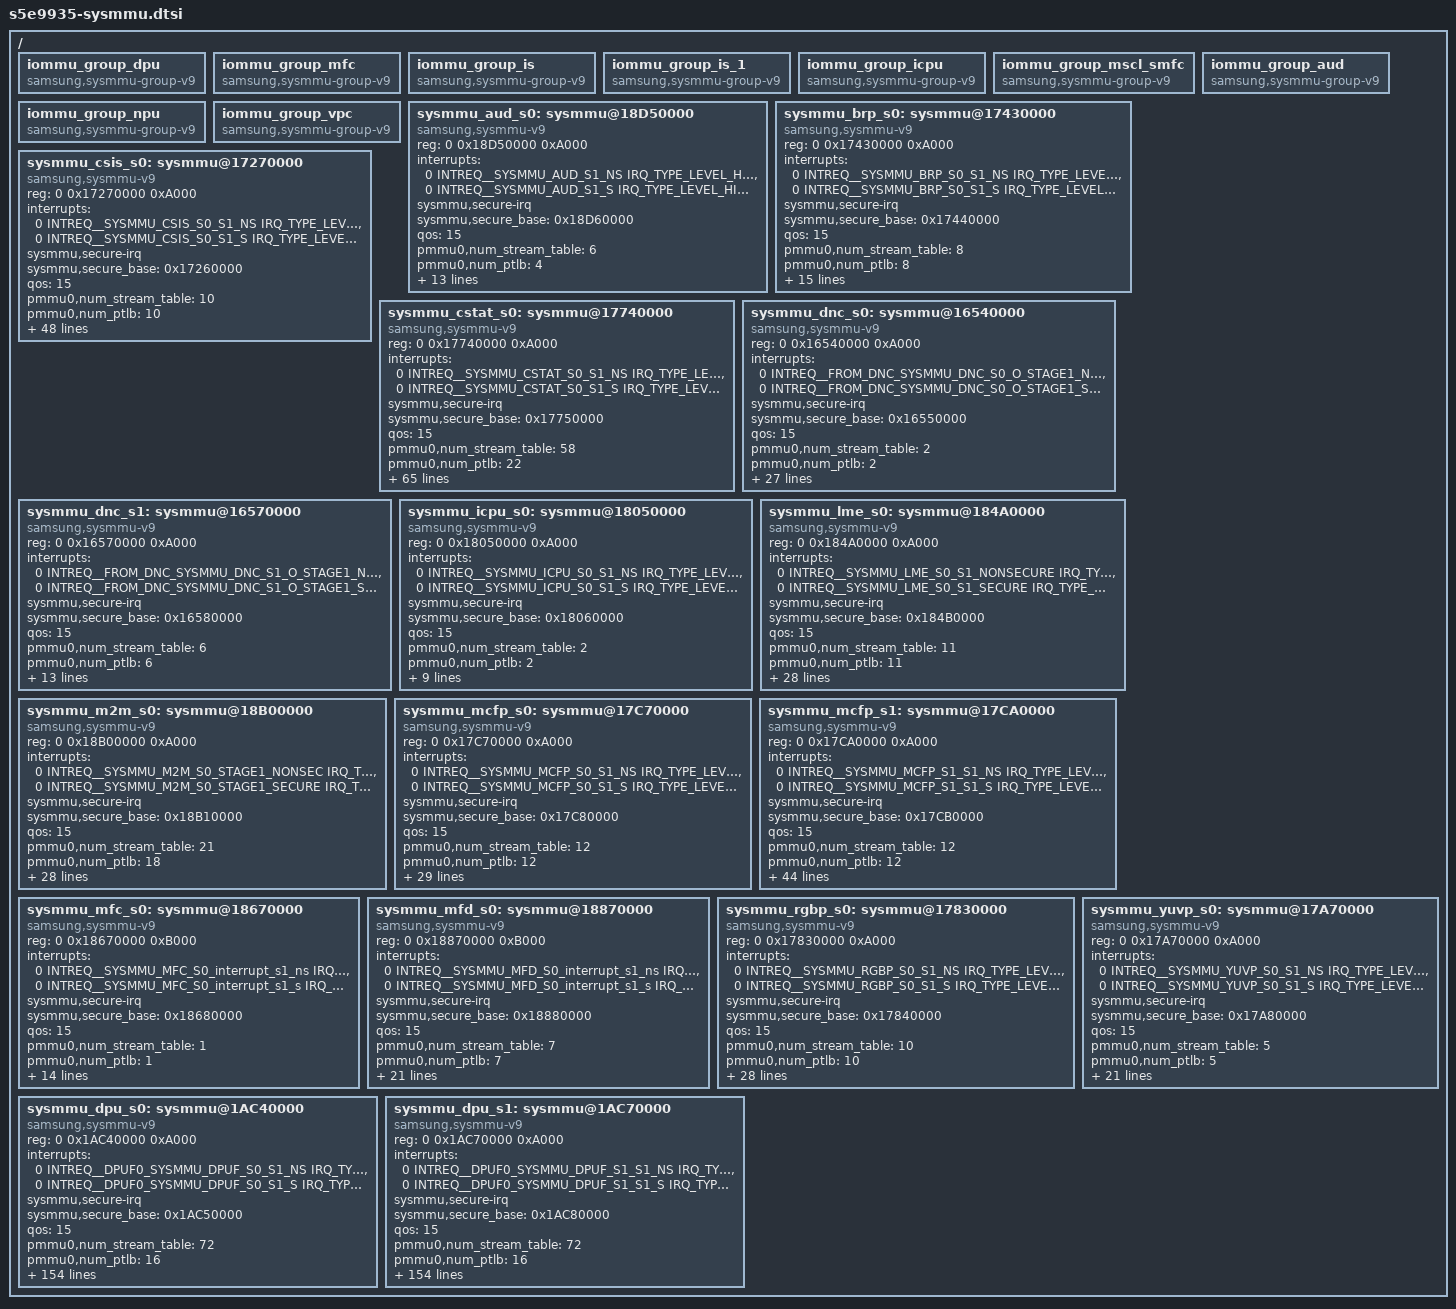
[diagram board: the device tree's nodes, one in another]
// SPDX-License-Identifier: GPL-2.0
/*
 * SAMSUNG S5E9935 SoC device tree source
 *
 * Copyright (c) 2022 Samsung Electronics Co., Ltd.
 *		http://www.samsung.com
 *
 * SAMSUNG S5E9935 SoC device nodes are listed in this file.
 * S5E9935 based board files can include this file and provide
 * values for board specific bindings.
 *
 * This program is free software; you can redistribute it and/or modify
 * it under the terms of the GNU General Public License version 2 as
 * published by the Free Software Foundation.
 */

#include <dt-bindings/interrupt-controller/arm-gic.h>
#include <dt-bindings/soc/samsung,sysmmu-v9.h>

/ {
	iommu_group_dpu: iommu_group_dpu {
		compatible = "samsung,sysmmu-group-v9";
	};

	iommu_group_mfc: iommu_group_mfc {
		compatible = "samsung,sysmmu-group-v9";
	};

	iommu_group_is: iommu_group_is {
		compatible = "samsung,sysmmu-group-v9";
	};

	iommu_group_is_1: iommu_group_is_1 {
		compatible = "samsung,sysmmu-group-v9";
	};

	iommu_group_icpu: iommu_group_icpu {
		compatible = "samsung,sysmmu-group-v9";
	};

	iommu_group_mscl_smfc: iommu_group_mscl_smfc {
		compatible = "samsung,sysmmu-group-v9";
	};

	iommu_group_aud: iommu_group_aud {
		compatible = "samsung,sysmmu-group-v9";
	};

	iommu_group_npu: iommu_group_npu {
		compatible = "samsung,sysmmu-group-v9";
	};

	iommu_group_vpc: iommu_group_vpc {
		compatible = "samsung,sysmmu-group-v9";
	};

	sysmmu_aud_s0: sysmmu@18D50000 {
		compatible = "samsung,sysmmu-v9";
		reg = <0 0x18D50000 0xA000>;
		interrupts = <0 INTREQ__SYSMMU_AUD_S1_NS IRQ_TYPE_LEVEL_HIGH>,
				<0 INTREQ__SYSMMU_AUD_S1_S IRQ_TYPE_LEVEL_HIGH>;
		sysmmu,secure-irq;
		sysmmu,secure_base = <0x18D60000>;
		qos = <15>;
		#iommu-cells = <0>;
		pmmu0,num_stream_table = <6>;
		pmmu0,num_ptlb = <4>;
		pmmu0,default_stream =
			<STREAM_CFG(PTLB_ID(0x0), STLB_ID(0x0), FETCH_SIZE(SIZE1), PTLB_DIS, STLB_DIS)>;
		pmmu0,stream_property =
			<1 STREAM_CFG(PTLB_ID(0x0), STLB_ID(0x0), FETCH_SIZE(SIZE1), PTLB_DIS, STLB_DIS)
			 STREAM_MATCH_CFG(DIR_RW)
			 STREAM_MATCH_SID_VALUE(0x1)
			 STREAM_MATCH_SID_MASK(0xF)>,
			<2 STREAM_CFG(PTLB_ID(0x0), STLB_ID(0x0), FETCH_SIZE(SIZE1), PTLB_DIS, STLB_DIS)
			 STREAM_MATCH_CFG(DIR_RW)
			 STREAM_MATCH_SID_VALUE(0x1)
			 STREAM_MATCH_SID_MASK(0xF)>,
			<3 STREAM_CFG(PTLB_ID(0x1), STLB_ID(0x1), FETCH_SIZE(SIZE1), PTLB_DIS, STLB_DIS)
			 STREAM_MATCH_CFG(DIR_RW)
			 STREAM_MATCH_SID_VALUE(0x3)
			 STREAM_MATCH_SID_MASK(0xF)>,
			<4 STREAM_CFG(PTLB_ID(0x2), STLB_ID(0x2), FETCH_SIZE(SIZE1), PTLB_DIS, STLB_DIS)
			 STREAM_MATCH_CFG(DIR_WRITE)
			 STREAM_MATCH_SID_VALUE(0x5)
			 STREAM_MATCH_SID_MASK(0xF)>,
			<5 STREAM_CFG(PTLB_ID(0x3), STLB_ID(0x3), FETCH_SIZE(SIZE1), PTLB_DIS, STLB_DIS)
			 STREAM_MATCH_CFG(DIR_WRITE)
			 STREAM_MATCH_SID_VALUE(0x6)
			 STREAM_MATCH_SID_MASK(0xF)>;
		num_pmmu = <1>;
		vmid_mask = <0x3>;
		sysmmu,feature-info = <0x0>;
		port-name = "ABOX (CA32_0) ABOX (UDMA) AB...";
		power-domains = <&pd_aud>;
	};

	sysmmu_brp_s0: sysmmu@17430000 {
		compatible = "samsung,sysmmu-v9";
		reg = <0 0x17430000 0xA000>;
		interrupts = <0 INTREQ__SYSMMU_BRP_S0_S1_NS IRQ_TYPE_LEVEL_HIGH>,
				<0 INTREQ__SYSMMU_BRP_S0_S1_S IRQ_TYPE_LEVEL_HIGH>;
		sysmmu,secure-irq;
		sysmmu,secure_base = <0x17440000>;
		qos = <15>;
		#iommu-cells = <0>;
		pmmu0,num_stream_table = <8>;
		pmmu0,num_ptlb = <8>;
		pmmu0,default_stream =
			<STREAM_CFG(PTLB_ID(0x5), STLB_ID(0x5), FETCH_SIZE(SIZE1), PTLB_DIS, STLB_DIS)>;
		pmmu0,stream_property =
			<1 STREAM_CFG(PTLB_ID(0x0), STLB_ID(0x0), FETCH_SIZE(SIZE1), PTLB_DIS, STLB_EN)
			 STREAM_MATCH_CFG(DIR_WRITE)
			 STREAM_MATCH_SID_VALUE(0x0)
			 STREAM_MATCH_SID_MASK(0xF)>,
			<2 STREAM_CFG(PTLB_ID(0x1), STLB_ID(0x1), FETCH_SIZE(SIZE1), PTLB_EN, STLB_EN)
			 STREAM_MATCH_CFG(DIR_READ)
			 STREAM_MATCH_SID_VALUE(0x1)
			 STREAM_MATCH_SID_MASK(0xF)>,
			<3 STREAM_CFG(PTLB_ID(0x2), STLB_ID(0x2), FETCH_SIZE(SIZE1), PTLB_EN, STLB_EN)
			 STREAM_MATCH_CFG(DIR_READ)
			 STREAM_MATCH_SID_VALUE(0x9)
			 STREAM_MATCH_SID_MASK(0xF)>,
			<4 STREAM_CFG(PTLB_ID(0x3), STLB_ID(0x3), FETCH_SIZE(SIZE1), PTLB_DIS, STLB_EN)
			 STREAM_MATCH_CFG(DIR_WRITE)
			 STREAM_MATCH_SID_VALUE(0x1)
			 STREAM_MATCH_SID_MASK(0xF)>,
			<5 STREAM_CFG(PTLB_ID(0x4), STLB_ID(0x4), FETCH_SIZE(SIZE1), PTLB_DIS, STLB_EN)
			 STREAM_MATCH_CFG(DIR_WRITE)
			 STREAM_MATCH_SID_VALUE(0x2)
			 STREAM_MATCH_SID_MASK(0xF)>,
			<6 STREAM_CFG(PTLB_ID(0x6), STLB_ID(0x6), FETCH_SIZE(SIZE1), PTLB_DIS, STLB_DIS)
			 STREAM_MATCH_CFG(DIR_WRITE)
			 STREAM_MATCH_SID_VALUE(0x3)
			 STREAM_MATCH_SID_MASK(0xF)>,
			<7 STREAM_CFG(PTLB_ID(0x7), STLB_ID(0x7), FETCH_SIZE(SIZE1), PTLB_DIS, STLB_DIS)
			 STREAM_MATCH_CFG(DIR_WRITE)
			 STREAM_MATCH_SID_VALUE(0x4)
			 STREAM_MATCH_SID_MASK(0xF)>;
		num_pmmu = <1>;
		vmid_mask = <0x3>;
		sysmmu,feature-info = <0x0>;
		port-name = "BYRP (M0) BYRP (M0) BYRP (M1...";
		power-domains = <&pd_brp>;
	};

	sysmmu_csis_s0: sysmmu@17270000 {
		compatible = "samsung,sysmmu-v9";
		reg = <0 0x17270000 0xA000>;
		interrupts = <0 INTREQ__SYSMMU_CSIS_S0_S1_NS IRQ_TYPE_LEVEL_HIGH>,
				<0 INTREQ__SYSMMU_CSIS_S0_S1_S IRQ_TYPE_LEVEL_HIGH>;
		sysmmu,secure-irq;
		sysmmu,secure_base = <0x17260000>;
		qos = <15>;
		#iommu-cells = <0>;
		pmmu0,num_stream_table = <10>;
		pmmu0,num_ptlb = <10>;
		pmmu0,default_stream =
			<STREAM_CFG(PTLB_ID(0x0), STLB_ID(0x0), FETCH_SIZE(SIZE1), PTLB_DIS, STLB_EN)>;
		pmmu0,stream_property =
			<1 STREAM_CFG(PTLB_ID(0x1), STLB_ID(0x1), FETCH_SIZE(SIZE1), PTLB_DIS, STLB_EN)
			 STREAM_MATCH_CFG(DIR_WRITE)
			 STREAM_MATCH_SID_VALUE(0x2)
			 STREAM_MATCH_SID_MASK(0xF)>,
			<2 STREAM_CFG(PTLB_ID(0x2), STLB_ID(0x2), FETCH_SIZE(SIZE1), PTLB_DIS, STLB_EN)
			 STREAM_MATCH_CFG(DIR_WRITE)
			 STREAM_MATCH_SID_VALUE(0x4)
			 STREAM_MATCH_SID_MASK(0xF)>,
			<3 STREAM_CFG(PTLB_ID(0x3), STLB_ID(0x3), FETCH_SIZE(SIZE1), PTLB_DIS, STLB_EN)
			 STREAM_MATCH_CFG(DIR_WRITE)
			 STREAM_MATCH_SID_VALUE(0x8)
			 STREAM_MATCH_SID_MASK(0xF)>,
			<4 STREAM_CFG(PTLB_ID(0x4), STLB_ID(0x4), FETCH_SIZE(SIZE1), PTLB_DIS, STLB_EN)
			 STREAM_MATCH_CFG(DIR_WRITE)
			 STREAM_MATCH_SID_VALUE(0xC)
			 STREAM_MATCH_SID_MASK(0xF)>,
			<5 STREAM_CFG(PTLB_ID(0x5), STLB_ID(0x5), FETCH_SIZE(SIZE1), PTLB_DIS, STLB_EN)
			 STREAM_MATCH_CFG(DIR_WRITE)
			 STREAM_MATCH_SID_VALUE(0x1)
			 STREAM_MATCH_SID_MASK(0xF)>,
			<6 STREAM_CFG(PTLB_ID(0x6), STLB_ID(0x6), FETCH_SIZE(SIZE1), PTLB_DIS, STLB_EN)
			 STREAM_MATCH_CFG(DIR_WRITE)
			 STREAM_MATCH_SID_VALUE(0x3)
			 STREAM_MATCH_SID_MASK(0xF)>,
			<7 STREAM_CFG(PTLB_ID(0x7), STLB_ID(0x7), FETCH_SIZE(SIZE1), PTLB_DIS, STLB_EN)
			 STREAM_MATCH_CFG(DIR_WRITE)
			 STREAM_MATCH_SID_VALUE(0x5)
			 STREAM_MATCH_SID_MASK(0xF)>,
			<8 STREAM_CFG(PTLB_ID(0x8), STLB_ID(0x8), FETCH_SIZE(SIZE1), PTLB_DIS, STLB_EN)
			 STREAM_MATCH_CFG(DIR_WRITE)
			 STREAM_MATCH_SID_VALUE(0x9)
			 STREAM_MATCH_SID_MASK(0xF)>,
			<9 STREAM_CFG(PTLB_ID(0x9), STLB_ID(0x9), FETCH_SIZE(SIZE1), PTLB_DIS, STLB_EN)
			 STREAM_MATCH_CFG(DIR_WRITE)
			 STREAM_MATCH_SID_VALUE(0xD)
			 STREAM_MATCH_SID_MASK(0xF)>;
		pmmu1,num_stream_table = <15>;
		pmmu1,num_ptlb = <15>;
		pmmu1,default_stream =
			<STREAM_CFG(PTLB_ID(0x0), STLB_ID(0xa), FETCH_SIZE(SIZE1), PTLB_DIS, STLB_EN)>;
		pmmu1,stream_property =
			<1 STREAM_CFG(PTLB_ID(0x1), STLB_ID(0xb), FETCH_SIZE(SIZE1), PTLB_DIS, STLB_EN)
			 STREAM_MATCH_CFG(DIR_WRITE)
			 STREAM_MATCH_SID_VALUE(0x4)
			 STREAM_MATCH_SID_MASK(0x1F)>,
			<2 STREAM_CFG(PTLB_ID(0x2), STLB_ID(0xc), FETCH_SIZE(SIZE1), PTLB_DIS, STLB_EN)
			 STREAM_MATCH_CFG(DIR_WRITE)
			 STREAM_MATCH_SID_VALUE(0x8)
			 STREAM_MATCH_SID_MASK(0x1F)>,
			<3 STREAM_CFG(PTLB_ID(0x3), STLB_ID(0xd), FETCH_SIZE(SIZE1), PTLB_DIS, STLB_EN)
			 STREAM_MATCH_CFG(DIR_WRITE)
			 STREAM_MATCH_SID_VALUE(0x10)
			 STREAM_MATCH_SID_MASK(0x1F)>,
			<4 STREAM_CFG(PTLB_ID(0x4), STLB_ID(0xe), FETCH_SIZE(SIZE1), PTLB_DIS, STLB_EN)
			 STREAM_MATCH_CFG(DIR_WRITE)
			 STREAM_MATCH_SID_VALUE(0x18)
			 STREAM_MATCH_SID_MASK(0x1F)>,
			<5 STREAM_CFG(PTLB_ID(0x5), STLB_ID(0xf), FETCH_SIZE(SIZE1), PTLB_DIS, STLB_EN)
			 STREAM_MATCH_CFG(DIR_WRITE)
			 STREAM_MATCH_SID_VALUE(0x1)
			 STREAM_MATCH_SID_MASK(0x1F)>,
			<6 STREAM_CFG(PTLB_ID(0x6), STLB_ID(0x10), FETCH_SIZE(SIZE1), PTLB_DIS, STLB_EN)
			 STREAM_MATCH_CFG(DIR_WRITE)
			 STREAM_MATCH_SID_VALUE(0x5)
			 STREAM_MATCH_SID_MASK(0x1F)>,
			<7 STREAM_CFG(PTLB_ID(0x7), STLB_ID(0x11), FETCH_SIZE(SIZE1), PTLB_DIS, STLB_EN)
			 STREAM_MATCH_CFG(DIR_WRITE)
			 STREAM_MATCH_SID_VALUE(0x9)
			 STREAM_MATCH_SID_MASK(0x1F)>,
			<8 STREAM_CFG(PTLB_ID(0x8), STLB_ID(0x12), FETCH_SIZE(SIZE1), PTLB_DIS, STLB_EN)
			 STREAM_MATCH_CFG(DIR_WRITE)
			 STREAM_MATCH_SID_VALUE(0x11)
			 STREAM_MATCH_SID_MASK(0x1F)>,
			<9 STREAM_CFG(PTLB_ID(0x9), STLB_ID(0x13), FETCH_SIZE(SIZE1), PTLB_DIS, STLB_EN)
			 STREAM_MATCH_CFG(DIR_WRITE)
			 STREAM_MATCH_SID_VALUE(0x19)
			 STREAM_MATCH_SID_MASK(0x1F)>,
			<10 STREAM_CFG(PTLB_ID(0xa), STLB_ID(0x14), FETCH_SIZE(SIZE1), PTLB_DIS, STLB_EN)
			 STREAM_MATCH_CFG(DIR_WRITE)
			 STREAM_MATCH_SID_VALUE(0x2)
			 STREAM_MATCH_SID_MASK(0x1F)>,
			<11 STREAM_CFG(PTLB_ID(0xb), STLB_ID(0x15), FETCH_SIZE(SIZE1), PTLB_DIS, STLB_EN)
			 STREAM_MATCH_CFG(DIR_WRITE)
			 STREAM_MATCH_SID_VALUE(0x6)
			 STREAM_MATCH_SID_MASK(0x1F)>,
			<12 STREAM_CFG(PTLB_ID(0xc), STLB_ID(0x16), FETCH_SIZE(SIZE1), PTLB_DIS, STLB_EN)
			 STREAM_MATCH_CFG(DIR_WRITE)
			 STREAM_MATCH_SID_VALUE(0xA)
			 STREAM_MATCH_SID_MASK(0x1F)>,
			<13 STREAM_CFG(PTLB_ID(0xd), STLB_ID(0x17), FETCH_SIZE(SIZE1), PTLB_DIS, STLB_EN)
			 STREAM_MATCH_CFG(DIR_WRITE)
			 STREAM_MATCH_SID_VALUE(0x12)
			 STREAM_MATCH_SID_MASK(0x1F)>,
			<14 STREAM_CFG(PTLB_ID(0xe), STLB_ID(0x18), FETCH_SIZE(SIZE1), PTLB_DIS, STLB_EN)
			 STREAM_MATCH_CFG(DIR_WRITE)
			 STREAM_MATCH_SID_VALUE(0x1A)
			 STREAM_MATCH_SID_MASK(0x1F)>;
		pmmu2,num_stream_table = <8>;
		pmmu2,num_ptlb = <8>;
		pmmu2,default_stream =
			<STREAM_CFG(PTLB_ID(0x5), STLB_ID(0x1e), FETCH_SIZE(SIZE1), PTLB_DIS, STLB_DIS)>;
		pmmu2,stream_property =
			<1 STREAM_CFG(PTLB_ID(0x6), STLB_ID(0x1f), FETCH_SIZE(SIZE1), PTLB_DIS, STLB_DIS)
			 STREAM_MATCH_CFG(DIR_WRITE)
			 STREAM_MATCH_SID_VALUE(0x2)
			 STREAM_MATCH_SID_MASK(0x7)>,
			<2 STREAM_CFG(PTLB_ID(0x0), STLB_ID(0x19), FETCH_SIZE(SIZE1), PTLB_DIS, STLB_EN)
			 STREAM_MATCH_CFG(DIR_WRITE)
			 STREAM_MATCH_SID_VALUE(0x0)
			 STREAM_MATCH_SID_MASK(0x7F)>,
			<3 STREAM_CFG(PTLB_ID(0x1), STLB_ID(0x1a), FETCH_SIZE(SIZE1), PTLB_DIS, STLB_EN)
			 STREAM_MATCH_CFG(DIR_READ)
			 STREAM_MATCH_SID_VALUE(0x0)
			 STREAM_MATCH_SID_MASK(0x7F)>,
			<4 STREAM_CFG(PTLB_ID(0x2), STLB_ID(0x1b), FETCH_SIZE(SIZE1), PTLB_DIS, STLB_EN)
			 STREAM_MATCH_CFG(DIR_WRITE)
			 STREAM_MATCH_SID_VALUE(0x20)
			 STREAM_MATCH_SID_MASK(0x7F)>,
			<5 STREAM_CFG(PTLB_ID(0x3), STLB_ID(0x1c), FETCH_SIZE(SIZE1), PTLB_DIS, STLB_EN)
			 STREAM_MATCH_CFG(DIR_WRITE)
			 STREAM_MATCH_SID_VALUE(0x40)
			 STREAM_MATCH_SID_MASK(0x7F)>,
			<6 STREAM_CFG(PTLB_ID(0x4), STLB_ID(0x1d), FETCH_SIZE(SIZE1), PTLB_DIS, STLB_EN)
			 STREAM_MATCH_CFG(DIR_WRITE)
			 STREAM_MATCH_SID_VALUE(0x60)
			 STREAM_MATCH_SID_MASK(0x7F)>,
			<7 STREAM_CFG(PTLB_ID(0x7), STLB_ID(0x20), FETCH_SIZE(SIZE1), PTLB_DIS, STLB_DIS)
			 STREAM_MATCH_CFG(DIR_WRITE)
			 STREAM_MATCH_SID_VALUE(0x3)
			 STREAM_MATCH_SID_MASK(0x7)>;
		num_pmmu = <3>;
		vmid_mask = <0x3>;
		sysmmu,feature-info = <0x0>;
		port-name = "CSISX7_V1.0 (CSIS DMA0) CSIS...";
		power-domains = <&pd_csis>;
	};

	sysmmu_cstat_s0: sysmmu@17740000 {
		compatible = "samsung,sysmmu-v9";
		reg = <0 0x17740000 0xA000>;
		interrupts = <0 INTREQ__SYSMMU_CSTAT_S0_S1_NS IRQ_TYPE_LEVEL_HIGH>,
				<0 INTREQ__SYSMMU_CSTAT_S0_S1_S IRQ_TYPE_LEVEL_HIGH>;
		sysmmu,secure-irq;
		sysmmu,secure_base = <0x17750000>;
		qos = <15>;
		#iommu-cells = <0>;
		pmmu0,num_stream_table = <58>;
		pmmu0,num_ptlb = <22>;
		pmmu0,default_stream =
			<STREAM_CFG(PTLB_ID(0x0), STLB_ID(0x0), FETCH_SIZE(SIZE1), PTLB_DIS, STLB_EN)>;
		pmmu0,stream_property =
			<1 STREAM_CFG(PTLB_ID(0x0), STLB_ID(0x1), FETCH_SIZE(SIZE1), PTLB_DIS, STLB_EN)
			 STREAM_MATCH_CFG(DIR_WRITE)
			 STREAM_MATCH_SID_VALUE(0x80)
			 STREAM_MATCH_SID_MASK(0x1FF)>,
			<2 STREAM_CFG(PTLB_ID(0x0), STLB_ID(0x2), FETCH_SIZE(SIZE1), PTLB_DIS, STLB_EN)
			 STREAM_MATCH_CFG(DIR_WRITE)
			 STREAM_MATCH_SID_VALUE(0x100)
			 STREAM_MATCH_SID_MASK(0x1FF)>,
			<3 STREAM_CFG(PTLB_ID(0x0), STLB_ID(0x3), FETCH_SIZE(SIZE1), PTLB_DIS, STLB_EN)
			 STREAM_MATCH_CFG(DIR_WRITE)
			 STREAM_MATCH_SID_VALUE(0x180)
			 STREAM_MATCH_SID_MASK(0x1FF)>,
			<4 STREAM_CFG(PTLB_ID(0x1), STLB_ID(0x4), FETCH_SIZE(SIZE1), PTLB_EN, STLB_EN)
			 STREAM_MATCH_CFG(DIR_READ)
			 STREAM_MATCH_SID_VALUE(0x0)
			 STREAM_MATCH_SID_MASK(0x1FF)>,
			<5 STREAM_CFG(PTLB_ID(0x2), STLB_ID(0x5), FETCH_SIZE(SIZE1), PTLB_DIS, STLB_EN)
			 STREAM_MATCH_CFG(DIR_WRITE)
			 STREAM_MATCH_SID_VALUE(0x1)
			 STREAM_MATCH_SID_MASK(0x1FF)>,
			<6 STREAM_CFG(PTLB_ID(0x0), STLB_ID(0x6), FETCH_SIZE(SIZE1), PTLB_DIS, STLB_EN)
			 STREAM_MATCH_CFG(DIR_WRITE)
			 STREAM_MATCH_SID_VALUE(0x21)
			 STREAM_MATCH_SID_MASK(0x1FF)>,
			<7 STREAM_CFG(PTLB_ID(0x0), STLB_ID(0x7), FETCH_SIZE(SIZE1), PTLB_DIS, STLB_EN)
			 STREAM_MATCH_CFG(DIR_WRITE)
			 STREAM_MATCH_SID_VALUE(0x41)
			 STREAM_MATCH_SID_MASK(0x1FF)>,
			<8 STREAM_CFG(PTLB_ID(0x0), STLB_ID(0x8), FETCH_SIZE(SIZE1), PTLB_DIS, STLB_EN)
			 STREAM_MATCH_CFG(DIR_WRITE)
			 STREAM_MATCH_SID_VALUE(0x81)
			 STREAM_MATCH_SID_MASK(0x1FF)>,
			<9 STREAM_CFG(PTLB_ID(0x3), STLB_ID(0x9), FETCH_SIZE(SIZE1), PTLB_EN, STLB_EN)
			 STREAM_MATCH_CFG(DIR_READ)
			 STREAM_MATCH_SID_VALUE(0x1)
			 STREAM_MATCH_SID_MASK(0x1FF)>,
			<10 STREAM_CFG(PTLB_ID(0x4), STLB_ID(0xa), FETCH_SIZE(SIZE1), PTLB_DIS, STLB_EN)
			 STREAM_MATCH_CFG(DIR_WRITE)
			 STREAM_MATCH_SID_VALUE(0x2)
			 STREAM_MATCH_SID_MASK(0x1FF)>,
			<11 STREAM_CFG(PTLB_ID(0x0), STLB_ID(0xb), FETCH_SIZE(SIZE1), PTLB_DIS, STLB_EN)
			 STREAM_MATCH_CFG(DIR_WRITE)
			 STREAM_MATCH_SID_VALUE(0x82)
			 STREAM_MATCH_SID_MASK(0x1FF)>,
			<12 STREAM_CFG(PTLB_ID(0x0), STLB_ID(0xc), FETCH_SIZE(SIZE1), PTLB_DIS, STLB_EN)
			 STREAM_MATCH_CFG(DIR_WRITE)
			 STREAM_MATCH_SID_VALUE(0x102)
			 STREAM_MATCH_SID_MASK(0x1FF)>,
			<13 STREAM_CFG(PTLB_ID(0x0), STLB_ID(0xd), FETCH_SIZE(SIZE1), PTLB_DIS, STLB_EN)
			 STREAM_MATCH_CFG(DIR_WRITE)
			 STREAM_MATCH_SID_VALUE(0x182)
			 STREAM_MATCH_SID_MASK(0x1FF)>,
			<14 STREAM_CFG(PTLB_ID(0x5), STLB_ID(0xe), FETCH_SIZE(SIZE1), PTLB_EN, STLB_EN)
			 STREAM_MATCH_CFG(DIR_READ)
			 STREAM_MATCH_SID_VALUE(0x2)
			 STREAM_MATCH_SID_MASK(0x1FF)>,
			<15 STREAM_CFG(PTLB_ID(0x6), STLB_ID(0xf), FETCH_SIZE(SIZE1), PTLB_DIS, STLB_EN)
			 STREAM_MATCH_CFG(DIR_WRITE)
			 STREAM_MATCH_SID_VALUE(0x3)
			 STREAM_MATCH_SID_MASK(0x1FF)>,
			<16 STREAM_CFG(PTLB_ID(0x0), STLB_ID(0x10), FETCH_SIZE(SIZE1), PTLB_DIS, STLB_EN)
			 STREAM_MATCH_CFG(DIR_WRITE)
			 STREAM_MATCH_SID_VALUE(0x83)
			 STREAM_MATCH_SID_MASK(0x1FF)>,
			<17 STREAM_CFG(PTLB_ID(0x0), STLB_ID(0x11), FETCH_SIZE(SIZE1), PTLB_DIS, STLB_EN)
			 STREAM_MATCH_CFG(DIR_WRITE)
			 STREAM_MATCH_SID_VALUE(0x103)
			 STREAM_MATCH_SID_MASK(0x1FF)>,
			<18 STREAM_CFG(PTLB_ID(0x0), STLB_ID(0x12), FETCH_SIZE(SIZE1), PTLB_DIS, STLB_EN)
			 STREAM_MATCH_CFG(DIR_WRITE)
			 STREAM_MATCH_SID_VALUE(0x183)
			 STREAM_MATCH_SID_MASK(0x1FF)>,
			<19 STREAM_CFG(PTLB_ID(0x7), STLB_ID(0x13), FETCH_SIZE(SIZE1), PTLB_EN, STLB_EN)
			 STREAM_MATCH_CFG(DIR_READ)
			 STREAM_MATCH_SID_VALUE(0x3)
			 STREAM_MATCH_SID_MASK(0x1FF)>,
			<20 STREAM_CFG(PTLB_ID(0x8), STLB_ID(0x14), FETCH_SIZE(SIZE1), PTLB_DIS, STLB_EN)
			 STREAM_MATCH_CFG(DIR_WRITE)
			 STREAM_MATCH_SID_VALUE(0x4)
			 STREAM_MATCH_SID_MASK(0x1FF)>,
			<21 STREAM_CFG(PTLB_ID(0x0), STLB_ID(0x15), FETCH_SIZE(SIZE1), PTLB_DIS, STLB_EN)
			 STREAM_MATCH_CFG(DIR_WRITE)
			 STREAM_MATCH_SID_VALUE(0x84)
			 STREAM_MATCH_SID_MASK(0x1FF)>,
			<22 STREAM_CFG(PTLB_ID(0x0), STLB_ID(0x16), FETCH_SIZE(SIZE1), PTLB_DIS, STLB_EN)
			 STREAM_MATCH_CFG(DIR_WRITE)
			 STREAM_MATCH_SID_VALUE(0x104)
			 STREAM_MATCH_SID_MASK(0x1FF)>,
			<23 STREAM_CFG(PTLB_ID(0x0), STLB_ID(0x17), FETCH_SIZE(SIZE1), PTLB_DIS, STLB_EN)
			 STREAM_MATCH_CFG(DIR_WRITE)
			 STREAM_MATCH_SID_VALUE(0x184)
			 STREAM_MATCH_SID_MASK(0x1FF)>,
			<24 STREAM_CFG(PTLB_ID(0x10), STLB_ID(0x34), FETCH_SIZE(SIZE1), PTLB_DIS, STLB_DIS)
			 STREAM_MATCH_CFG(DIR_READ)
			 STREAM_MATCH_SID_VALUE(0x4)
			 STREAM_MATCH_SID_MASK(0x1FF)>,
			<25 STREAM_CFG(PTLB_ID(0x9), STLB_ID(0x18), FETCH_SIZE(SIZE1), PTLB_DIS, STLB_EN)
			 STREAM_MATCH_CFG(DIR_WRITE)
			 STREAM_MATCH_SID_VALUE(0x5)
			 STREAM_MATCH_SID_MASK(0x1FF)>,
			<26 STREAM_CFG(PTLB_ID(0x0), STLB_ID(0x19), FETCH_SIZE(SIZE1), PTLB_DIS, STLB_EN)
			 STREAM_MATCH_CFG(DIR_WRITE)
			 STREAM_MATCH_SID_VALUE(0x85)
			 STREAM_MATCH_SID_MASK(0x1FF)>,
			<27 STREAM_CFG(PTLB_ID(0x0), STLB_ID(0x1a), FETCH_SIZE(SIZE1), PTLB_DIS, STLB_EN)
			 STREAM_MATCH_CFG(DIR_WRITE)
			 STREAM_MATCH_SID_VALUE(0x105)
			 STREAM_MATCH_SID_MASK(0x1FF)>,
			<28 STREAM_CFG(PTLB_ID(0x0), STLB_ID(0x1b), FETCH_SIZE(SIZE1), PTLB_DIS, STLB_EN)
			 STREAM_MATCH_CFG(DIR_WRITE)
			 STREAM_MATCH_SID_VALUE(0x185)
			 STREAM_MATCH_SID_MASK(0x1FF)>,
			<29 STREAM_CFG(PTLB_ID(0x11), STLB_ID(0x35), FETCH_SIZE(SIZE1), PTLB_DIS, STLB_DIS)
			 STREAM_MATCH_CFG(DIR_READ)
			 STREAM_MATCH_SID_VALUE(0x5)
			 STREAM_MATCH_SID_MASK(0x1FF)>,
			<30 STREAM_CFG(PTLB_ID(0xa), STLB_ID(0x1c), FETCH_SIZE(SIZE1), PTLB_DIS, STLB_EN)
			 STREAM_MATCH_CFG(DIR_WRITE)
			 STREAM_MATCH_SID_VALUE(0x6)
			 STREAM_MATCH_SID_MASK(0x1FF)>,
			<31 STREAM_CFG(PTLB_ID(0x0), STLB_ID(0x1d), FETCH_SIZE(SIZE1), PTLB_DIS, STLB_EN)
			 STREAM_MATCH_CFG(DIR_WRITE)
			 STREAM_MATCH_SID_VALUE(0x86)
			 STREAM_MATCH_SID_MASK(0x1FF)>,
			<32 STREAM_CFG(PTLB_ID(0x0), STLB_ID(0x1e), FETCH_SIZE(SIZE1), PTLB_DIS, STLB_EN)
			 STREAM_MATCH_CFG(DIR_WRITE)
			 STREAM_MATCH_SID_VALUE(0x106)
			 STREAM_MATCH_SID_MASK(0x1FF)>,
			<33 STREAM_CFG(PTLB_ID(0x0), STLB_ID(0x1f), FETCH_SIZE(SIZE1), PTLB_DIS, STLB_EN)
			 STREAM_MATCH_CFG(DIR_WRITE)
			 STREAM_MATCH_SID_VALUE(0x186)
			 STREAM_MATCH_SID_MASK(0x1FF)>,
			<34 STREAM_CFG(PTLB_ID(0x12), STLB_ID(0x36), FETCH_SIZE(SIZE1), PTLB_DIS, STLB_DIS)
			 STREAM_MATCH_CFG(DIR_READ)
			 STREAM_MATCH_SID_VALUE(0x6)
			 STREAM_MATCH_SID_MASK(0x1FF)>,
			<35 STREAM_CFG(PTLB_ID(0xb), STLB_ID(0x20), FETCH_SIZE(SIZE1), PTLB_DIS, STLB_EN)
			 STREAM_MATCH_CFG(DIR_WRITE)
			 STREAM_MATCH_SID_VALUE(0x7)
			 STREAM_MATCH_SID_MASK(0x1FF)>,
			<36 STREAM_CFG(PTLB_ID(0x0), STLB_ID(0x21), FETCH_SIZE(SIZE1), PTLB_DIS, STLB_EN)
			 STREAM_MATCH_CFG(DIR_WRITE)
			 STREAM_MATCH_SID_VALUE(0x87)
			 STREAM_MATCH_SID_MASK(0x1FF)>,
			<37 STREAM_CFG(PTLB_ID(0x0), STLB_ID(0x22), FETCH_SIZE(SIZE1), PTLB_DIS, STLB_EN)
			 STREAM_MATCH_CFG(DIR_WRITE)
			 STREAM_MATCH_SID_VALUE(0x107)
			 STREAM_MATCH_SID_MASK(0x1FF)>,
			<38 STREAM_CFG(PTLB_ID(0x0), STLB_ID(0x23), FETCH_SIZE(SIZE1), PTLB_DIS, STLB_EN)
			 STREAM_MATCH_CFG(DIR_WRITE)
			 STREAM_MATCH_SID_VALUE(0x187)
			 STREAM_MATCH_SID_MASK(0x1FF)>,
			<39 STREAM_CFG(PTLB_ID(0x13), STLB_ID(0x37), FETCH_SIZE(SIZE1), PTLB_DIS, STLB_DIS)
			 STREAM_MATCH_CFG(DIR_READ)
			 STREAM_MATCH_SID_VALUE(0x7)
			 STREAM_MATCH_SID_MASK(0x1FF)>,
			<40 STREAM_CFG(PTLB_ID(0xc), STLB_ID(0x24), FETCH_SIZE(SIZE1), PTLB_DIS, STLB_EN)
			 STREAM_MATCH_CFG(DIR_WRITE)
			 STREAM_MATCH_SID_VALUE(0x8)
			 STREAM_MATCH_SID_MASK(0x1FF)>,
			<41 STREAM_CFG(PTLB_ID(0x0), STLB_ID(0x25), FETCH_SIZE(SIZE1), PTLB_DIS, STLB_EN)
			 STREAM_MATCH_CFG(DIR_WRITE)
			 STREAM_MATCH_SID_VALUE(0x28)
			 STREAM_MATCH_SID_MASK(0x1FF)>,
			<42 STREAM_CFG(PTLB_ID(0x0), STLB_ID(0x26), FETCH_SIZE(SIZE1), PTLB_DIS, STLB_EN)
			 STREAM_MATCH_CFG(DIR_WRITE)
			 STREAM_MATCH_SID_VALUE(0x48)
			 STREAM_MATCH_SID_MASK(0x1FF)>,
			<43 STREAM_CFG(PTLB_ID(0x0), STLB_ID(0x27), FETCH_SIZE(SIZE1), PTLB_DIS, STLB_EN)
			 STREAM_MATCH_CFG(DIR_WRITE)
			 STREAM_MATCH_SID_VALUE(0x88)
			 STREAM_MATCH_SID_MASK(0x1FF)>,
			<44 STREAM_CFG(PTLB_ID(0xd), STLB_ID(0x28), FETCH_SIZE(SIZE1), PTLB_DIS, STLB_EN)
			 STREAM_MATCH_CFG(DIR_WRITE)
			 STREAM_MATCH_SID_VALUE(0x9)
			 STREAM_MATCH_SID_MASK(0x1FF)>,
			<45 STREAM_CFG(PTLB_ID(0x0), STLB_ID(0x29), FETCH_SIZE(SIZE1), PTLB_DIS, STLB_EN)
			 STREAM_MATCH_CFG(DIR_WRITE)
			 STREAM_MATCH_SID_VALUE(0x89)
			 STREAM_MATCH_SID_MASK(0x1FF)>,
			<46 STREAM_CFG(PTLB_ID(0x0), STLB_ID(0x2a), FETCH_SIZE(SIZE1), PTLB_DIS, STLB_EN)
			 STREAM_MATCH_CFG(DIR_WRITE)
			 STREAM_MATCH_SID_VALUE(0x109)
			 STREAM_MATCH_SID_MASK(0x1FF)>,
			<47 STREAM_CFG(PTLB_ID(0x0), STLB_ID(0x2b), FETCH_SIZE(SIZE1), PTLB_DIS, STLB_EN)
			 STREAM_MATCH_CFG(DIR_WRITE)
			 STREAM_MATCH_SID_VALUE(0x189)
			 STREAM_MATCH_SID_MASK(0x1FF)>,
			<48 STREAM_CFG(PTLB_ID(0xe), STLB_ID(0x2c), FETCH_SIZE(SIZE1), PTLB_DIS, STLB_EN)
			 STREAM_MATCH_CFG(DIR_WRITE)
			 STREAM_MATCH_SID_VALUE(0x29)
			 STREAM_MATCH_SID_MASK(0x1FF)>,
			<49 STREAM_CFG(PTLB_ID(0x0), STLB_ID(0x2d), FETCH_SIZE(SIZE1), PTLB_DIS, STLB_EN)
			 STREAM_MATCH_CFG(DIR_WRITE)
			 STREAM_MATCH_SID_VALUE(0xA9)
			 STREAM_MATCH_SID_MASK(0x1FF)>,
			<50 STREAM_CFG(PTLB_ID(0x0), STLB_ID(0x2e), FETCH_SIZE(SIZE1), PTLB_DIS, STLB_EN)
			 STREAM_MATCH_CFG(DIR_WRITE)
			 STREAM_MATCH_SID_VALUE(0x129)
			 STREAM_MATCH_SID_MASK(0x1FF)>,
			<51 STREAM_CFG(PTLB_ID(0x0), STLB_ID(0x2f), FETCH_SIZE(SIZE1), PTLB_DIS, STLB_EN)
			 STREAM_MATCH_CFG(DIR_WRITE)
			 STREAM_MATCH_SID_VALUE(0x1A9)
			 STREAM_MATCH_SID_MASK(0x1FF)>,
			<52 STREAM_CFG(PTLB_ID(0xf), STLB_ID(0x30), FETCH_SIZE(SIZE1), PTLB_DIS, STLB_EN)
			 STREAM_MATCH_CFG(DIR_WRITE)
			 STREAM_MATCH_SID_VALUE(0x49)
			 STREAM_MATCH_SID_MASK(0x1FF)>,
			<53 STREAM_CFG(PTLB_ID(0x0), STLB_ID(0x31), FETCH_SIZE(SIZE1), PTLB_DIS, STLB_EN)
			 STREAM_MATCH_CFG(DIR_WRITE)
			 STREAM_MATCH_SID_VALUE(0xC9)
			 STREAM_MATCH_SID_MASK(0x1FF)>,
			<54 STREAM_CFG(PTLB_ID(0x0), STLB_ID(0x32), FETCH_SIZE(SIZE1), PTLB_DIS, STLB_EN)
			 STREAM_MATCH_CFG(DIR_WRITE)
			 STREAM_MATCH_SID_VALUE(0x149)
			 STREAM_MATCH_SID_MASK(0x1FF)>,
			<55 STREAM_CFG(PTLB_ID(0x0), STLB_ID(0x33), FETCH_SIZE(SIZE1), PTLB_DIS, STLB_EN)
			 STREAM_MATCH_CFG(DIR_WRITE)
			 STREAM_MATCH_SID_VALUE(0x1C9)
			 STREAM_MATCH_SID_MASK(0x1FF)>,
			<56 STREAM_CFG(PTLB_ID(0x14), STLB_ID(0x38), FETCH_SIZE(SIZE1), PTLB_DIS, STLB_DIS)
			 STREAM_MATCH_CFG(DIR_WRITE)
			 STREAM_MATCH_SID_VALUE(0xA)
			 STREAM_MATCH_SID_MASK(0x1FF)>,
			<57 STREAM_CFG(PTLB_ID(0x15), STLB_ID(0x39), FETCH_SIZE(SIZE1), PTLB_DIS, STLB_DIS)
			 STREAM_MATCH_CFG(DIR_WRITE)
			 STREAM_MATCH_SID_VALUE(0xB)
			 STREAM_MATCH_SID_MASK(0x1FF)>;
		num_pmmu = <1>;
		vmid_mask = <0x3>;
		sysmmu,feature-info = <0x0>;
		port-name = "CSTAT_RD0_RGBYHIST CSTAT_RD1...";
		power-domains = <&pd_cstat>;
	};

	sysmmu_dnc_s0: sysmmu@16540000 {
		compatible = "samsung,sysmmu-v9";
		reg = <0 0x16540000 0xA000>;
		interrupts = <0 INTREQ__FROM_DNC_SYSMMU_DNC_S0_O_STAGE1_NONSEC IRQ_TYPE_LEVEL_HIGH>,
				<0 INTREQ__FROM_DNC_SYSMMU_DNC_S0_O_STAGE1_SECURE IRQ_TYPE_LEVEL_HIGH>;
		sysmmu,secure-irq;
		sysmmu,secure_base = <0x16550000>;
		qos = <15>;
		#iommu-cells = <0>;
		pmmu0,num_stream_table = <2>;
		pmmu0,num_ptlb = <2>;
		pmmu0,default_stream =
			<STREAM_CFG(PTLB_ID(0x0), STLB_ID(0x0), FETCH_SIZE(SIZE8), PTLB_EN, STLB_EN)>;
		pmmu0,stream_property =
			<1 STREAM_CFG(PTLB_ID(0x1), STLB_ID(0x1), FETCH_SIZE(SIZE1), PTLB_DIS, STLB_DIS)
			 STREAM_MATCH_CFG(DIR_RW)
			 STREAM_MATCH_SID_VALUE(0x40)
			 STREAM_MATCH_SID_MASK(0x40)>;
		pmmu1,num_stream_table = <2>;
		pmmu1,num_ptlb = <2>;
		pmmu1,default_stream =
			<STREAM_CFG(PTLB_ID(0x0), STLB_ID(0x0), FETCH_SIZE(SIZE8), PTLB_EN, STLB_EN)>;
		pmmu1,stream_property =
			<1 STREAM_CFG(PTLB_ID(0x1), STLB_ID(0x1), FETCH_SIZE(SIZE1), PTLB_DIS, STLB_DIS)
			 STREAM_MATCH_CFG(DIR_RW)
			 STREAM_MATCH_SID_VALUE(0x40)
			 STREAM_MATCH_SID_MASK(0x40)>;
		pmmu2,num_stream_table = <2>;
		pmmu2,num_ptlb = <2>;
		pmmu2,default_stream =
			<STREAM_CFG(PTLB_ID(0x0), STLB_ID(0x0), FETCH_SIZE(SIZE8), PTLB_EN, STLB_EN)>;
		pmmu2,stream_property =
			<1 STREAM_CFG(PTLB_ID(0x1), STLB_ID(0x1), FETCH_SIZE(SIZE1), PTLB_DIS, STLB_DIS)
			 STREAM_MATCH_CFG(DIR_RW)
			 STREAM_MATCH_SID_VALUE(0x40)
			 STREAM_MATCH_SID_MASK(0x40)>;
		pmmu3,num_stream_table = <2>;
		pmmu3,num_ptlb = <2>;
		pmmu3,default_stream =
			<STREAM_CFG(PTLB_ID(0x0), STLB_ID(0x0), FETCH_SIZE(SIZE8), PTLB_EN, STLB_EN)>;
		pmmu3,stream_property =
			<1 STREAM_CFG(PTLB_ID(0x1), STLB_ID(0x1), FETCH_SIZE(SIZE1), PTLB_DIS, STLB_DIS)
			 STREAM_MATCH_CFG(DIR_RW)
			 STREAM_MATCH_SID_VALUE(0x40)
			 STREAM_MATCH_SID_MASK(0x40)>;
		num_pmmu = <4>;
		vmid_mask = <0x3>;
		sysmmu,feature-info = <0x0>;
		port-name = "IP_SDMA (BUSD0) IP_SDMA (BUS...";
		power-domains = <&pd_dnc>;
	};

	sysmmu_dnc_s1: sysmmu@16570000 {
		compatible = "samsung,sysmmu-v9";
		reg = <0 0x16570000 0xA000>;
		interrupts = <0 INTREQ__FROM_DNC_SYSMMU_DNC_S1_O_STAGE1_NONSEC IRQ_TYPE_LEVEL_HIGH>,
				<0 INTREQ__FROM_DNC_SYSMMU_DNC_S1_O_STAGE1_SECURE IRQ_TYPE_LEVEL_HIGH>;
		sysmmu,secure-irq;
		sysmmu,secure_base = <0x16580000>;
		qos = <15>;
		#iommu-cells = <0>;
		pmmu0,num_stream_table = <6>;
		pmmu0,num_ptlb = <6>;
		pmmu0,default_stream =
			<STREAM_CFG(PTLB_ID(0x0), STLB_ID(0x0), FETCH_SIZE(SIZE1), PTLB_DIS, STLB_DIS)>;
		pmmu0,stream_property =
			<1 STREAM_CFG(PTLB_ID(0x4), STLB_ID(0x4), FETCH_SIZE(SIZE1), PTLB_DIS, STLB_DIS)
			 STREAM_MATCH_CFG(DIR_READ)
			 STREAM_MATCH_SID_VALUE(0x1)
			 STREAM_MATCH_SID_MASK(0xF)>,
			<2 STREAM_CFG(PTLB_ID(0x1), STLB_ID(0x1), FETCH_SIZE(SIZE1), PTLB_DIS, STLB_EN)
			 STREAM_MATCH_CFG(DIR_READ)
			 STREAM_MATCH_SID_VALUE(0x9)
			 STREAM_MATCH_SID_MASK(0xF)>,
			<3 STREAM_CFG(PTLB_ID(0x2), STLB_ID(0x2), FETCH_SIZE(SIZE1), PTLB_DIS, STLB_EN)
			 STREAM_MATCH_CFG(DIR_READ)
			 STREAM_MATCH_SID_VALUE(0x2)
			 STREAM_MATCH_SID_MASK(0xF)>,
			<4 STREAM_CFG(PTLB_ID(0x3), STLB_ID(0x3), FETCH_SIZE(SIZE1), PTLB_DIS, STLB_EN)
			 STREAM_MATCH_CFG(DIR_READ)
			 STREAM_MATCH_SID_VALUE(0x3)
			 STREAM_MATCH_SID_MASK(0xF)>,
			<5 STREAM_CFG(PTLB_ID(0x5), STLB_ID(0x5), FETCH_SIZE(SIZE1), PTLB_DIS, STLB_DIS)
			 STREAM_MATCH_CFG(DIR_WRITE)
			 STREAM_MATCH_SID_VALUE(0x4)
			 STREAM_MATCH_SID_MASK(0xF)>;
		num_pmmu = <1>;
		vmid_mask = <0x3>;
		sysmmu,feature-info = <0x0>;
		port-name = "IP_DNC (DRAM) ";
		power-domains = <&pd_dnc>;
	};

	sysmmu_icpu_s0: sysmmu@18050000 {
		compatible = "samsung,sysmmu-v9";
		reg = <0 0x18050000 0xA000>;
		interrupts = <0 INTREQ__SYSMMU_ICPU_S0_S1_NS IRQ_TYPE_LEVEL_HIGH>,
				<0 INTREQ__SYSMMU_ICPU_S0_S1_S IRQ_TYPE_LEVEL_HIGH>;
		sysmmu,secure-irq;
		sysmmu,secure_base = <0x18060000>;
		qos = <15>;
		#iommu-cells = <0>;
		pmmu0,num_stream_table = <2>;
		pmmu0,num_ptlb = <2>;
		pmmu0,default_stream =
			<STREAM_CFG(PTLB_ID(0x0), STLB_ID(0x0), FETCH_SIZE(SIZE1), PTLB_DIS, STLB_DIS)>;
		pmmu0,stream_property =
			<1 STREAM_CFG(PTLB_ID(0x1), STLB_ID(0x1), FETCH_SIZE(SIZE1), PTLB_DIS, STLB_EN)
			 STREAM_MATCH_CFG(DIR_RW)
			 STREAM_MATCH_SID_VALUE(0x1)
			 STREAM_MATCH_SID_MASK(0x1)>;
		num_pmmu = <1>;
		vmid_mask = <0x3>;
		sysmmu,feature-info = <0x0>;
		port-name = "ICPU (CA32) ";
		power-domains = <&pd_icpu>;
	};

	sysmmu_lme_s0: sysmmu@184A0000 {
		compatible = "samsung,sysmmu-v9";
		reg = <0 0x184A0000 0xA000>;
		interrupts = <0 INTREQ__SYSMMU_LME_S0_S1_NONSECURE IRQ_TYPE_LEVEL_HIGH>,
				<0 INTREQ__SYSMMU_LME_S0_S1_SECURE IRQ_TYPE_LEVEL_HIGH>;
		sysmmu,secure-irq;
		sysmmu,secure_base = <0x184B0000>;
		qos = <15>;
		#iommu-cells = <0>;
		pmmu0,num_stream_table = <11>;
		pmmu0,num_ptlb = <11>;
		pmmu0,default_stream =
			<STREAM_CFG(PTLB_ID(0x0), STLB_ID(0x0), FETCH_SIZE(SIZE16), PTLB_DIS, STLB_EN)>;
		pmmu0,stream_property =
			<1 STREAM_CFG(PTLB_ID(0x4), STLB_ID(0x4), FETCH_SIZE(SIZE1), PTLB_DIS, STLB_EN)
			 STREAM_MATCH_CFG(DIR_READ)
			 STREAM_MATCH_SID_VALUE(0x8)
			 STREAM_MATCH_SID_MASK(0x1F)>,
			<2 STREAM_CFG(PTLB_ID(0x2), STLB_ID(0x1), FETCH_SIZE(SIZE8), PTLB_DIS, STLB_EN)
			 STREAM_MATCH_CFG(DIR_WRITE)
			 STREAM_MATCH_SID_VALUE(0x0)
			 STREAM_MATCH_SID_MASK(0x1F)>,
			<3 STREAM_CFG(PTLB_ID(0x5), STLB_ID(0x5), FETCH_SIZE(SIZE1), PTLB_DIS, STLB_EN)
			 STREAM_MATCH_CFG(DIR_WRITE)
			 STREAM_MATCH_SID_VALUE(0x8)
			 STREAM_MATCH_SID_MASK(0x1F)>,
			<4 STREAM_CFG(PTLB_ID(0x3), STLB_ID(0x2), FETCH_SIZE(SIZE8), PTLB_DIS, STLB_EN)
			 STREAM_MATCH_CFG(DIR_WRITE)
			 STREAM_MATCH_SID_VALUE(0x10)
			 STREAM_MATCH_SID_MASK(0x1F)>,
			<5 STREAM_CFG(PTLB_ID(0x6), STLB_ID(0x6), FETCH_SIZE(SIZE1), PTLB_DIS, STLB_EN)
			 STREAM_MATCH_CFG(DIR_WRITE)
			 STREAM_MATCH_SID_VALUE(0x18)
			 STREAM_MATCH_SID_MASK(0x1F)>,
			<6 STREAM_CFG(PTLB_ID(0x1), STLB_ID(0x3), FETCH_SIZE(SIZE16), PTLB_DIS, STLB_EN)
			 STREAM_MATCH_CFG(DIR_READ)
			 STREAM_MATCH_SID_VALUE(0x1)
			 STREAM_MATCH_SID_MASK(0x1F)>,
			<7 STREAM_CFG(PTLB_ID(0x7), STLB_ID(0x7), FETCH_SIZE(SIZE1), PTLB_DIS, STLB_EN)
			 STREAM_MATCH_CFG(DIR_READ)
			 STREAM_MATCH_SID_VALUE(0x9)
			 STREAM_MATCH_SID_MASK(0x1F)>,
			<8 STREAM_CFG(PTLB_ID(0x8), STLB_ID(0xe), FETCH_SIZE(SIZE1), PTLB_DIS, STLB_DIS)
			 STREAM_MATCH_CFG(DIR_WRITE)
			 STREAM_MATCH_SID_VALUE(0x2)
			 STREAM_MATCH_SID_MASK(0x1F)>,
			<9 STREAM_CFG(PTLB_ID(0xa), STLB_ID(0x10), FETCH_SIZE(SIZE1), PTLB_DIS, STLB_DIS)
			 STREAM_MATCH_CFG(DIR_WRITE)
			 STREAM_MATCH_SID_VALUE(0x3)
			 STREAM_MATCH_SID_MASK(0x1F)>,
			<10 STREAM_CFG(PTLB_ID(0x9), STLB_ID(0xf), FETCH_SIZE(SIZE1), PTLB_DIS, STLB_DIS)
			 STREAM_MATCH_CFG(DIR_READ)
			 STREAM_MATCH_SID_VALUE(0x4)
			 STREAM_MATCH_SID_MASK(0x1F)>;
		pmmu1,num_stream_table = <6>;
		pmmu1,num_ptlb = <6>;
		pmmu1,default_stream =
			<STREAM_CFG(PTLB_ID(0x1), STLB_ID(0x8), FETCH_SIZE(SIZE1), PTLB_DIS, STLB_EN)>;
		pmmu1,stream_property =
			<1 STREAM_CFG(PTLB_ID(0x2), STLB_ID(0x9), FETCH_SIZE(SIZE1), PTLB_DIS, STLB_EN)
			 STREAM_MATCH_CFG(DIR_WRITE)
			 STREAM_MATCH_SID_VALUE(0x1)
			 STREAM_MATCH_SID_MASK(0x1F)>,
			<2 STREAM_CFG(PTLB_ID(0x0), STLB_ID(0xd), FETCH_SIZE(SIZE1), PTLB_DIS, STLB_DIS)
			 STREAM_MATCH_CFG(DIR_READ)
			 STREAM_MATCH_SID_VALUE(0x0)
			 STREAM_MATCH_SID_MASK(0x1F)>,
			<3 STREAM_CFG(PTLB_ID(0x3), STLB_ID(0xa), FETCH_SIZE(SIZE1), PTLB_EN, STLB_EN)
			 STREAM_MATCH_CFG(DIR_READ)
			 STREAM_MATCH_SID_VALUE(0x1)
			 STREAM_MATCH_SID_MASK(0x1F)>,
			<4 STREAM_CFG(PTLB_ID(0x4), STLB_ID(0xb), FETCH_SIZE(SIZE1), PTLB_DIS, STLB_EN)
			 STREAM_MATCH_CFG(DIR_WRITE)
			 STREAM_MATCH_SID_VALUE(0x3)
			 STREAM_MATCH_SID_MASK(0x1F)>,
			<5 STREAM_CFG(PTLB_ID(0x5), STLB_ID(0xc), FETCH_SIZE(SIZE1), PTLB_DIS, STLB_EN)
			 STREAM_MATCH_CFG(DIR_WRITE)
			 STREAM_MATCH_SID_VALUE(0x2)
			 STREAM_MATCH_SID_MASK(0x1F)>;
		num_pmmu = <2>;
		vmid_mask = <0x3>;
		sysmmu,feature-info = <0x0>;
		port-name = "GDC1 (M0) GDC1 (M1) GDC1 (M2...";
		power-domains = <&pd_lme>;
	};

	sysmmu_m2m_s0: sysmmu@18B00000 {
		compatible = "samsung,sysmmu-v9";
		reg = <0 0x18B00000 0xA000>;
		interrupts = <0 INTREQ__SYSMMU_M2M_S0_STAGE1_NONSEC IRQ_TYPE_LEVEL_HIGH>,
				<0 INTREQ__SYSMMU_M2M_S0_STAGE1_SECURE IRQ_TYPE_LEVEL_HIGH>;
		sysmmu,secure-irq;
		sysmmu,secure_base = <0x18B10000>;
		qos = <15>;
		#iommu-cells = <0>;
		pmmu0,num_stream_table = <21>;
		pmmu0,num_ptlb = <18>;
		pmmu0,default_stream =
			<STREAM_CFG(PTLB_ID(0x1), STLB_ID(0xd), FETCH_SIZE(SIZE8), PTLB_DIS, STLB_DIS)>;
		pmmu0,stream_property =
			<1 STREAM_CFG(PTLB_ID(0x2), STLB_ID(0xe), FETCH_SIZE(SIZE8), PTLB_DIS, STLB_DIS)
			 STREAM_MATCH_CFG(DIR_RW)
			 STREAM_MATCH_SID_VALUE(0x1)
			 STREAM_MATCH_SID_MASK(0x3F)>,
			<2 STREAM_CFG(PTLB_ID(0x4), STLB_ID(0x10), FETCH_SIZE(SIZE1), PTLB_DIS, STLB_DIS)
			 STREAM_MATCH_CFG(DIR_READ)
			 STREAM_MATCH_SID_VALUE(0xA)
			 STREAM_MATCH_SID_MASK(0x3F)>,
			<3 STREAM_CFG(PTLB_ID(0x5), STLB_ID(0x7), FETCH_SIZE(SIZE1), PTLB_DIS, STLB_EN)
			 STREAM_MATCH_CFG(DIR_WRITE)
			 STREAM_MATCH_SID_VALUE(0x22)
			 STREAM_MATCH_SID_MASK(0x3F)>,
			<4 STREAM_CFG(PTLB_ID(0x6), STLB_ID(0x8), FETCH_SIZE(SIZE1), PTLB_DIS, STLB_EN)
			 STREAM_MATCH_CFG(DIR_WRITE)
			 STREAM_MATCH_SID_VALUE(0x32)
			 STREAM_MATCH_SID_MASK(0x3F)>,
			<5 STREAM_CFG(PTLB_ID(0x0), STLB_ID(0xc), FETCH_SIZE(SIZE32), PTLB_DIS, STLB_EN)
			 STREAM_MATCH_CFG(DIR_READ)
			 STREAM_MATCH_SID_VALUE(0x2)
			 STREAM_MATCH_SID_MASK(0x3F)>,
			<6 STREAM_CFG(PTLB_ID(0x0), STLB_ID(0xc), FETCH_SIZE(SIZE32), PTLB_DIS, STLB_EN)
			 STREAM_MATCH_CFG(DIR_WRITE)
			 STREAM_MATCH_SID_VALUE(0x42)
			 STREAM_MATCH_SID_MASK(0x3F)>,
			<7 STREAM_CFG(PTLB_ID(0x0), STLB_ID(0xc), FETCH_SIZE(SIZE32), PTLB_DIS, STLB_EN)
			 STREAM_MATCH_CFG(DIR_WRITE)
			 STREAM_MATCH_SID_VALUE(0x2)
			 STREAM_MATCH_SID_MASK(0x3F)>,
			<8 STREAM_CFG(PTLB_ID(0x0), STLB_ID(0xc), FETCH_SIZE(SIZE32), PTLB_DIS, STLB_EN)
			 STREAM_MATCH_CFG(DIR_WRITE)
			 STREAM_MATCH_SID_VALUE(0x12)
			 STREAM_MATCH_SID_MASK(0x3F)>,
			<9 STREAM_CFG(PTLB_ID(0xa), STLB_ID(0x11), FETCH_SIZE(SIZE1), PTLB_DIS, STLB_DIS)
			 STREAM_MATCH_CFG(DIR_WRITE)
			 STREAM_MATCH_SID_VALUE(0xA)
			 STREAM_MATCH_SID_MASK(0x3F)>,
			<10 STREAM_CFG(PTLB_ID(0x3), STLB_ID(0xf), FETCH_SIZE(SIZE8), PTLB_DIS, STLB_DIS)
			 STREAM_MATCH_CFG(DIR_RW)
			 STREAM_MATCH_SID_VALUE(0x3)
			 STREAM_MATCH_SID_MASK(0x3F)>,
			<11 STREAM_CFG(PTLB_ID(0xb), STLB_ID(0x0), FETCH_SIZE(SIZE8), PTLB_DIS, STLB_EN)
			 STREAM_MATCH_CFG(DIR_READ)
			 STREAM_MATCH_SID_VALUE(0x4)
			 STREAM_MATCH_SID_MASK(0x3F)>,
			<12 STREAM_CFG(PTLB_ID(0xc), STLB_ID(0x3), FETCH_SIZE(SIZE4), PTLB_DIS, STLB_EN)
			 STREAM_MATCH_CFG(DIR_READ)
			 STREAM_MATCH_SID_VALUE(0xC)
			 STREAM_MATCH_SID_MASK(0x3F)>,
			<13 STREAM_CFG(PTLB_ID(0xd), STLB_ID(0x1), FETCH_SIZE(SIZE8), PTLB_DIS, STLB_EN)
			 STREAM_MATCH_CFG(DIR_READ)
			 STREAM_MATCH_SID_VALUE(0x14)
			 STREAM_MATCH_SID_MASK(0x3F)>,
			<14 STREAM_CFG(PTLB_ID(0xe), STLB_ID(0x4), FETCH_SIZE(SIZE4), PTLB_DIS, STLB_EN)
			 STREAM_MATCH_CFG(DIR_READ)
			 STREAM_MATCH_SID_VALUE(0x1C)
			 STREAM_MATCH_SID_MASK(0x3F)>,
			<15 STREAM_CFG(PTLB_ID(0xf), STLB_ID(0x2), FETCH_SIZE(SIZE8), PTLB_DIS, STLB_EN)
			 STREAM_MATCH_CFG(DIR_READ)
			 STREAM_MATCH_SID_VALUE(0x24)
			 STREAM_MATCH_SID_MASK(0x3F)>,
			<16 STREAM_CFG(PTLB_ID(0x7), STLB_ID(0x9), FETCH_SIZE(SIZE1), PTLB_DIS, STLB_EN)
			 STREAM_MATCH_CFG(DIR_READ)
			 STREAM_MATCH_SID_VALUE(0x2C)
			 STREAM_MATCH_SID_MASK(0x3F)>,
			<17 STREAM_CFG(PTLB_ID(0x10), STLB_ID(0x5), FETCH_SIZE(SIZE4), PTLB_DIS, STLB_EN)
			 STREAM_MATCH_CFG(DIR_WRITE)
			 STREAM_MATCH_SID_VALUE(0x4)
			 STREAM_MATCH_SID_MASK(0x3F)>,
			<18 STREAM_CFG(PTLB_ID(0x11), STLB_ID(0x6), FETCH_SIZE(SIZE2), PTLB_DIS, STLB_EN)
			 STREAM_MATCH_CFG(DIR_WRITE)
			 STREAM_MATCH_SID_VALUE(0xC)
			 STREAM_MATCH_SID_MASK(0x3F)>,
			<19 STREAM_CFG(PTLB_ID(0x8), STLB_ID(0xa), FETCH_SIZE(SIZE1), PTLB_DIS, STLB_EN)
			 STREAM_MATCH_CFG(DIR_WRITE)
			 STREAM_MATCH_SID_VALUE(0x14)
			 STREAM_MATCH_SID_MASK(0x3F)>,
			<20 STREAM_CFG(PTLB_ID(0x9), STLB_ID(0xb), FETCH_SIZE(SIZE1), PTLB_DIS, STLB_EN)
			 STREAM_MATCH_CFG(DIR_WRITE)
			 STREAM_MATCH_SID_VALUE(0x1C)
			 STREAM_MATCH_SID_MASK(0x3F)>;
		num_pmmu = <1>;
		vmid_mask = <0x3>;
		sysmmu,feature-info = <0x0>;
		port-name = "JPEG0 JPEG1 M2M(M2M_SCALER_V...";
		power-domains = <&pd_m2m>;
	};

	sysmmu_mcfp_s0: sysmmu@17C70000 {
		compatible = "samsung,sysmmu-v9";
		reg = <0 0x17C70000 0xA000>;
		interrupts = <0 INTREQ__SYSMMU_MCFP_S0_S1_NS IRQ_TYPE_LEVEL_HIGH>,
				<0 INTREQ__SYSMMU_MCFP_S0_S1_S IRQ_TYPE_LEVEL_HIGH>;
		sysmmu,secure-irq;
		sysmmu,secure_base = <0x17C80000>;
		qos = <15>;
		#iommu-cells = <0>;
		pmmu0,num_stream_table = <12>;
		pmmu0,num_ptlb = <12>;
		pmmu0,default_stream =
			<STREAM_CFG(PTLB_ID(0x0), STLB_ID(0x0), FETCH_SIZE(SIZE32), PTLB_DIS, STLB_EN)>;
		pmmu0,stream_property =
			<1 STREAM_CFG(PTLB_ID(0x2), STLB_ID(0x2), FETCH_SIZE(SIZE1), PTLB_EN, STLB_EN)
			 STREAM_MATCH_CFG(DIR_READ)
			 STREAM_MATCH_SID_VALUE(0x8)
			 STREAM_MATCH_SID_MASK(0x1F)>,
			<2 STREAM_CFG(PTLB_ID(0x1), STLB_ID(0x0), FETCH_SIZE(SIZE32), PTLB_DIS, STLB_EN)
			 STREAM_MATCH_CFG(DIR_READ)
			 STREAM_MATCH_SID_VALUE(0x1)
			 STREAM_MATCH_SID_MASK(0x1F)>,
			<3 STREAM_CFG(PTLB_ID(0x3), STLB_ID(0x2), FETCH_SIZE(SIZE1), PTLB_EN, STLB_EN)
			 STREAM_MATCH_CFG(DIR_READ)
			 STREAM_MATCH_SID_VALUE(0x9)
			 STREAM_MATCH_SID_MASK(0x1F)>,
			<4 STREAM_CFG(PTLB_ID(0x4), STLB_ID(0x4), FETCH_SIZE(SIZE1), PTLB_DIS, STLB_EN)
			 STREAM_MATCH_CFG(DIR_WRITE)
			 STREAM_MATCH_SID_VALUE(0x2)
			 STREAM_MATCH_SID_MASK(0x1F)>,
			<5 STREAM_CFG(PTLB_ID(0x5), STLB_ID(0x5), FETCH_SIZE(SIZE1), PTLB_DIS, STLB_EN)
			 STREAM_MATCH_CFG(DIR_WRITE)
			 STREAM_MATCH_SID_VALUE(0x6)
			 STREAM_MATCH_SID_MASK(0x1F)>,
			<6 STREAM_CFG(PTLB_ID(0x6), STLB_ID(0x6), FETCH_SIZE(SIZE1), PTLB_DIS, STLB_EN)
			 STREAM_MATCH_CFG(DIR_WRITE)
			 STREAM_MATCH_SID_VALUE(0xA)
			 STREAM_MATCH_SID_MASK(0x1F)>,
			<7 STREAM_CFG(PTLB_ID(0x7), STLB_ID(0x7), FETCH_SIZE(SIZE1), PTLB_DIS, STLB_EN)
			 STREAM_MATCH_CFG(DIR_WRITE)
			 STREAM_MATCH_SID_VALUE(0xE)
			 STREAM_MATCH_SID_MASK(0x1F)>,
			<8 STREAM_CFG(PTLB_ID(0x8), STLB_ID(0x8), FETCH_SIZE(SIZE1), PTLB_DIS, STLB_EN)
			 STREAM_MATCH_CFG(DIR_WRITE)
			 STREAM_MATCH_SID_VALUE(0x12)
			 STREAM_MATCH_SID_MASK(0x1F)>,
			<9 STREAM_CFG(PTLB_ID(0x9), STLB_ID(0x9), FETCH_SIZE(SIZE1), PTLB_DIS, STLB_EN)
			 STREAM_MATCH_CFG(DIR_WRITE)
			 STREAM_MATCH_SID_VALUE(0x3)
			 STREAM_MATCH_SID_MASK(0x1F)>,
			<10 STREAM_CFG(PTLB_ID(0xa), STLB_ID(0xa), FETCH_SIZE(SIZE16), PTLB_DIS, STLB_EN)
			 STREAM_MATCH_CFG(DIR_WRITE)
			 STREAM_MATCH_SID_VALUE(0xB)
			 STREAM_MATCH_SID_MASK(0x1F)>,
			<11 STREAM_CFG(PTLB_ID(0xb), STLB_ID(0xb), FETCH_SIZE(SIZE1), PTLB_DIS, STLB_EN)
			 STREAM_MATCH_CFG(DIR_WRITE)
			 STREAM_MATCH_SID_VALUE(0x13)
			 STREAM_MATCH_SID_MASK(0x1F)>;
		pmmu1,num_stream_table = <6>;
		pmmu1,num_ptlb = <6>;
		pmmu1,default_stream =
			<STREAM_CFG(PTLB_ID(0x0), STLB_ID(0x1), FETCH_SIZE(SIZE1), PTLB_DIS, STLB_EN)>;
		pmmu1,stream_property =
			<1 STREAM_CFG(PTLB_ID(0x1), STLB_ID(0x3), FETCH_SIZE(SIZE1), PTLB_DIS, STLB_EN)
			 STREAM_MATCH_CFG(DIR_WRITE)
			 STREAM_MATCH_SID_VALUE(0x0)
			 STREAM_MATCH_SID_MASK(0xF)>,
			<2 STREAM_CFG(PTLB_ID(0x2), STLB_ID(0xc), FETCH_SIZE(SIZE1), PTLB_DIS, STLB_EN)
			 STREAM_MATCH_CFG(DIR_READ)
			 STREAM_MATCH_SID_VALUE(0x1)
			 STREAM_MATCH_SID_MASK(0xF)>,
			<3 STREAM_CFG(PTLB_ID(0x3), STLB_ID(0xd), FETCH_SIZE(SIZE1), PTLB_DIS, STLB_EN)
			 STREAM_MATCH_CFG(DIR_WRITE)
			 STREAM_MATCH_SID_VALUE(0x1)
			 STREAM_MATCH_SID_MASK(0xF)>,
			<4 STREAM_CFG(PTLB_ID(0x4), STLB_ID(0xe), FETCH_SIZE(SIZE1), PTLB_DIS, STLB_EN)
			 STREAM_MATCH_CFG(DIR_WRITE)
			 STREAM_MATCH_SID_VALUE(0x5)
			 STREAM_MATCH_SID_MASK(0xF)>,
			<5 STREAM_CFG(PTLB_ID(0x5), STLB_ID(0xf), FETCH_SIZE(SIZE1), PTLB_DIS, STLB_DIS)
			 STREAM_MATCH_CFG(DIR_READ)
			 STREAM_MATCH_SID_VALUE(0x2)
			 STREAM_MATCH_SID_MASK(0xF)>;
		num_pmmu = <2>;
		vmid_mask = <0x3>;
		sysmmu,feature-info = <0x0>;
		port-name = "MCFP_M0 MCFP_M1 MCSC_M1 MCSC...";
		power-domains = <&pd_mcsc>;
	};

	sysmmu_mcfp_s1: sysmmu@17CA0000 {
		compatible = "samsung,sysmmu-v9";
		reg = <0 0x17CA0000 0xA000>;
		interrupts = <0 INTREQ__SYSMMU_MCFP_S1_S1_NS IRQ_TYPE_LEVEL_HIGH>,
				<0 INTREQ__SYSMMU_MCFP_S1_S1_S IRQ_TYPE_LEVEL_HIGH>;
		sysmmu,secure-irq;
		sysmmu,secure_base = <0x17CB0000>;
		qos = <15>;
		#iommu-cells = <0>;
		pmmu0,num_stream_table = <12>;
		pmmu0,num_ptlb = <12>;
		pmmu0,default_stream =
			<STREAM_CFG(PTLB_ID(0x0), STLB_ID(0x3), FETCH_SIZE(SIZE1), PTLB_EN, STLB_EN)>;
		pmmu0,stream_property =
			<1 STREAM_CFG(PTLB_ID(0x1), STLB_ID(0x4), FETCH_SIZE(SIZE1), PTLB_DIS, STLB_EN)
			 STREAM_MATCH_CFG(DIR_WRITE)
			 STREAM_MATCH_SID_VALUE(0x0)
			 STREAM_MATCH_SID_MASK(0x1F)>,
			<2 STREAM_CFG(PTLB_ID(0x2), STLB_ID(0x5), FETCH_SIZE(SIZE1), PTLB_DIS, STLB_EN)
			 STREAM_MATCH_CFG(DIR_WRITE)
			 STREAM_MATCH_SID_VALUE(0x10)
			 STREAM_MATCH_SID_MASK(0x1F)>,
			<3 STREAM_CFG(PTLB_ID(0x3), STLB_ID(0x6), FETCH_SIZE(SIZE1), PTLB_EN, STLB_EN)
			 STREAM_MATCH_CFG(DIR_READ)
			 STREAM_MATCH_SID_VALUE(0x1)
			 STREAM_MATCH_SID_MASK(0x1F)>,
			<4 STREAM_CFG(PTLB_ID(0x4), STLB_ID(0x7), FETCH_SIZE(SIZE1), PTLB_EN, STLB_EN)
			 STREAM_MATCH_CFG(DIR_READ)
			 STREAM_MATCH_SID_VALUE(0x2)
			 STREAM_MATCH_SID_MASK(0x1F)>,
			<5 STREAM_CFG(PTLB_ID(0x5), STLB_ID(0x8), FETCH_SIZE(SIZE1), PTLB_EN, STLB_EN)
			 STREAM_MATCH_CFG(DIR_READ)
			 STREAM_MATCH_SID_VALUE(0x3)
			 STREAM_MATCH_SID_MASK(0x1F)>,
			<6 STREAM_CFG(PTLB_ID(0x6), STLB_ID(0x9), FETCH_SIZE(SIZE1), PTLB_EN, STLB_EN)
			 STREAM_MATCH_CFG(DIR_READ)
			 STREAM_MATCH_SID_VALUE(0x4)
			 STREAM_MATCH_SID_MASK(0x1F)>,
			<7 STREAM_CFG(PTLB_ID(0x7), STLB_ID(0xa), FETCH_SIZE(SIZE1), PTLB_EN, STLB_EN)
			 STREAM_MATCH_CFG(DIR_READ)
			 STREAM_MATCH_SID_VALUE(0x5)
			 STREAM_MATCH_SID_MASK(0x1F)>,
			<8 STREAM_CFG(PTLB_ID(0x8), STLB_ID(0x1), FETCH_SIZE(SIZE1), PTLB_EN, STLB_EN)
			 STREAM_MATCH_CFG(DIR_READ)
			 STREAM_MATCH_SID_VALUE(0x6)
			 STREAM_MATCH_SID_MASK(0x1F)>,
			<9 STREAM_CFG(PTLB_ID(0x9), STLB_ID(0xb), FETCH_SIZE(SIZE1), PTLB_EN, STLB_EN)
			 STREAM_MATCH_CFG(DIR_READ)
			 STREAM_MATCH_SID_VALUE(0x7)
			 STREAM_MATCH_SID_MASK(0x1F)>,
			<10 STREAM_CFG(PTLB_ID(0xa), STLB_ID(0x19), FETCH_SIZE(SIZE1), PTLB_DIS, STLB_DIS)
			 STREAM_MATCH_CFG(DIR_WRITE)
			 STREAM_MATCH_SID_VALUE(0x8)
			 STREAM_MATCH_SID_MASK(0x1F)>,
			<11 STREAM_CFG(PTLB_ID(0xb), STLB_ID(0x1a), FETCH_SIZE(SIZE1), PTLB_DIS, STLB_DIS)
			 STREAM_MATCH_CFG(DIR_WRITE)
			 STREAM_MATCH_SID_VALUE(0x9)
			 STREAM_MATCH_SID_MASK(0x1F)>;
		pmmu1,num_stream_table = <8>;
		pmmu1,num_ptlb = <8>;
		pmmu1,default_stream =
			<STREAM_CFG(PTLB_ID(0x0), STLB_ID(0x0), FETCH_SIZE(SIZE32), PTLB_DIS, STLB_EN)>;
		pmmu1,stream_property =
			<1 STREAM_CFG(PTLB_ID(0x1), STLB_ID(0x2), FETCH_SIZE(SIZE1), PTLB_DIS, STLB_EN)
			 STREAM_MATCH_CFG(DIR_READ)
			 STREAM_MATCH_SID_VALUE(0x4)
			 STREAM_MATCH_SID_MASK(0x1F)>,
			<2 STREAM_CFG(PTLB_ID(0x2), STLB_ID(0xc), FETCH_SIZE(SIZE1), PTLB_DIS, STLB_EN)
			 STREAM_MATCH_CFG(DIR_WRITE)
			 STREAM_MATCH_SID_VALUE(0x1)
			 STREAM_MATCH_SID_MASK(0x1F)>,
			<3 STREAM_CFG(PTLB_ID(0x3), STLB_ID(0xd), FETCH_SIZE(SIZE1), PTLB_DIS, STLB_EN)
			 STREAM_MATCH_CFG(DIR_WRITE)
			 STREAM_MATCH_SID_VALUE(0x9)
			 STREAM_MATCH_SID_MASK(0x1F)>,
			<4 STREAM_CFG(PTLB_ID(0x4), STLB_ID(0xe), FETCH_SIZE(SIZE1), PTLB_DIS, STLB_EN)
			 STREAM_MATCH_CFG(DIR_WRITE)
			 STREAM_MATCH_SID_VALUE(0x11)
			 STREAM_MATCH_SID_MASK(0x1F)>,
			<5 STREAM_CFG(PTLB_ID(0x5), STLB_ID(0xf), FETCH_SIZE(SIZE1), PTLB_DIS, STLB_EN)
			 STREAM_MATCH_CFG(DIR_WRITE)
			 STREAM_MATCH_SID_VALUE(0x2)
			 STREAM_MATCH_SID_MASK(0x1F)>,
			<6 STREAM_CFG(PTLB_ID(0x6), STLB_ID(0x10), FETCH_SIZE(SIZE1), PTLB_DIS, STLB_EN)
			 STREAM_MATCH_CFG(DIR_WRITE)
			 STREAM_MATCH_SID_VALUE(0xA)
			 STREAM_MATCH_SID_MASK(0x1F)>,
			<7 STREAM_CFG(PTLB_ID(0x7), STLB_ID(0x11), FETCH_SIZE(SIZE1), PTLB_DIS, STLB_EN)
			 STREAM_MATCH_CFG(DIR_WRITE)
			 STREAM_MATCH_SID_VALUE(0x12)
			 STREAM_MATCH_SID_MASK(0x1F)>;
		pmmu2,num_stream_table = <9>;
		pmmu2,num_ptlb = <9>;
		pmmu2,default_stream =
			<STREAM_CFG(PTLB_ID(0x0), STLB_ID(0x0), FETCH_SIZE(SIZE32), PTLB_DIS, STLB_EN)>;
		pmmu2,stream_property =
			<1 STREAM_CFG(PTLB_ID(0x1), STLB_ID(0x2), FETCH_SIZE(SIZE1), PTLB_EN, STLB_EN)
			 STREAM_MATCH_CFG(DIR_READ)
			 STREAM_MATCH_SID_VALUE(0x2)
			 STREAM_MATCH_SID_MASK(0xF)>,
			<2 STREAM_CFG(PTLB_ID(0x2), STLB_ID(0x12), FETCH_SIZE(SIZE1), PTLB_EN, STLB_EN)
			 STREAM_MATCH_CFG(DIR_READ)
			 STREAM_MATCH_SID_VALUE(0x1)
			 STREAM_MATCH_SID_MASK(0xF)>,
			<3 STREAM_CFG(PTLB_ID(0x3), STLB_ID(0x13), FETCH_SIZE(SIZE1), PTLB_EN, STLB_EN)
			 STREAM_MATCH_CFG(DIR_READ)
			 STREAM_MATCH_SID_VALUE(0x3)
			 STREAM_MATCH_SID_MASK(0xF)>,
			<4 STREAM_CFG(PTLB_ID(0x4), STLB_ID(0x14), FETCH_SIZE(SIZE1), PTLB_DIS, STLB_EN)
			 STREAM_MATCH_CFG(DIR_WRITE)
			 STREAM_MATCH_SID_VALUE(0x1)
			 STREAM_MATCH_SID_MASK(0xF)>,
			<5 STREAM_CFG(PTLB_ID(0x5), STLB_ID(0x15), FETCH_SIZE(SIZE1), PTLB_DIS, STLB_EN)
			 STREAM_MATCH_CFG(DIR_WRITE)
			 STREAM_MATCH_SID_VALUE(0x3)
			 STREAM_MATCH_SID_MASK(0xF)>,
			<6 STREAM_CFG(PTLB_ID(0x6), STLB_ID(0x16), FETCH_SIZE(SIZE1), PTLB_DIS, STLB_EN)
			 STREAM_MATCH_CFG(DIR_WRITE)
			 STREAM_MATCH_SID_VALUE(0x5)
			 STREAM_MATCH_SID_MASK(0xF)>,
			<7 STREAM_CFG(PTLB_ID(0x7), STLB_ID(0x17), FETCH_SIZE(SIZE1), PTLB_DIS, STLB_EN)
			 STREAM_MATCH_CFG(DIR_WRITE)
			 STREAM_MATCH_SID_VALUE(0x7)
			 STREAM_MATCH_SID_MASK(0xF)>,
			<8 STREAM_CFG(PTLB_ID(0x8), STLB_ID(0x18), FETCH_SIZE(SIZE1), PTLB_DIS, STLB_EN)
			 STREAM_MATCH_CFG(DIR_WRITE)
			 STREAM_MATCH_SID_VALUE(0x9)
			 STREAM_MATCH_SID_MASK(0xF)>;
		num_pmmu = <3>;
		vmid_mask = <0x3>;
		sysmmu,feature-info = <0x0>;
		port-name = "MCFP_M6 MCFP_M7 MCFP_M8 MCFP...";
		power-domains = <&pd_mcsc>;
	};

	sysmmu_mfc_s0: sysmmu@18670000 {
		compatible = "samsung,sysmmu-v9";
		reg = <0 0x18670000 0xB000>;
		interrupts = <0 INTREQ__SYSMMU_MFC_S0_interrupt_s1_ns IRQ_TYPE_LEVEL_HIGH>,
				<0 INTREQ__SYSMMU_MFC_S0_interrupt_s1_s IRQ_TYPE_LEVEL_HIGH>;
		sysmmu,secure-irq;
		sysmmu,secure_base = <0x18680000>;
		qos = <15>;
		#iommu-cells = <0>;
		pmmu0,num_stream_table = <1>;
		pmmu0,num_ptlb = <1>;
		pmmu0,default_stream =
			<STREAM_CFG(PTLB_ID(0x0), STLB_ID(0x0), FETCH_SIZE(SIZE4), PTLB_DIS, STLB_DIS)>;
		pmmu1,num_stream_table = <3>;
		pmmu1,num_ptlb = <3>;
		pmmu1,default_stream =
			<STREAM_CFG(PTLB_ID(0x0), STLB_ID(0x1), FETCH_SIZE(SIZE4), PTLB_DIS, STLB_EN)>;
		pmmu1,stream_property =
			<1 STREAM_CFG(PTLB_ID(0x2), STLB_ID(0x3), FETCH_SIZE(SIZE1), PTLB_DIS, STLB_DIS)
			 STREAM_MATCH_CFG(DIR_WRITE)
			 STREAM_MATCH_SID_VALUE(0x1)
			 STREAM_MATCH_SID_MASK(0x3)>,
			<2 STREAM_CFG(PTLB_ID(0x1), STLB_ID(0x2), FETCH_SIZE(SIZE1), PTLB_DIS, STLB_DIS)
			 STREAM_MATCH_CFG(DIR_RW)
			 STREAM_MATCH_SID_VALUE(0x2)
			 STREAM_MATCH_SID_MASK(0x3)>;
		num_pmmu = <2>;
		vmid_mask = <0x7>;
		sysmmu,feature-info = <0x0>;
		port-name = "FIMV_MFC_V17.0 (M0) FIMV_MFC...";
		power-domains = <&pd_mfc>;
	};

	sysmmu_mfd_s0: sysmmu@18870000 {
		compatible = "samsung,sysmmu-v9";
		reg = <0 0x18870000 0xB000>;
		interrupts = <0 INTREQ__SYSMMU_MFD_S0_interrupt_s1_ns IRQ_TYPE_LEVEL_HIGH>,
				<0 INTREQ__SYSMMU_MFD_S0_interrupt_s1_s IRQ_TYPE_LEVEL_HIGH>;
		sysmmu,secure-irq;
		sysmmu,secure_base = <0x18880000>;
		qos = <15>;
		#iommu-cells = <0>;
		pmmu0,num_stream_table = <7>;
		pmmu0,num_ptlb = <7>;
		pmmu0,default_stream =
			<STREAM_CFG(PTLB_ID(0x0), STLB_ID(0x1), FETCH_SIZE(SIZE4), PTLB_DIS, STLB_DIS)>;
		pmmu0,stream_property =
			<1 STREAM_CFG(PTLB_ID(0x1), STLB_ID(0x2), FETCH_SIZE(SIZE32), PTLB_DIS, STLB_EN)
			 STREAM_MATCH_CFG(DIR_READ)
			 STREAM_MATCH_SID_VALUE(0x1)
			 STREAM_MATCH_SID_MASK(0x7)>,
			<2 STREAM_CFG(PTLB_ID(0x4), STLB_ID(0x6), FETCH_SIZE(SIZE1), PTLB_DIS, STLB_EN)
			 STREAM_MATCH_CFG(DIR_READ)
			 STREAM_MATCH_SID_VALUE(0x3)
			 STREAM_MATCH_SID_MASK(0x7)>,
			<3 STREAM_CFG(PTLB_ID(0x2), STLB_ID(0x4), FETCH_SIZE(SIZE16), PTLB_DIS, STLB_EN)
			 STREAM_MATCH_CFG(DIR_READ)
			 STREAM_MATCH_SID_VALUE(0x5)
			 STREAM_MATCH_SID_MASK(0x7)>,
			<4 STREAM_CFG(PTLB_ID(0x5), STLB_ID(0x7), FETCH_SIZE(SIZE1), PTLB_DIS, STLB_EN)
			 STREAM_MATCH_CFG(DIR_READ)
			 STREAM_MATCH_SID_VALUE(0x7)
			 STREAM_MATCH_SID_MASK(0x7)>,
			<5 STREAM_CFG(PTLB_ID(0x3), STLB_ID(0x5), FETCH_SIZE(SIZE16), PTLB_DIS, STLB_EN)
			 STREAM_MATCH_CFG(DIR_WRITE)
			 STREAM_MATCH_SID_VALUE(0x1)
			 STREAM_MATCH_SID_MASK(0x7)>,
			<6 STREAM_CFG(PTLB_ID(0x6), STLB_ID(0x8), FETCH_SIZE(SIZE1), PTLB_DIS, STLB_EN)
			 STREAM_MATCH_CFG(DIR_WRITE)
			 STREAM_MATCH_SID_VALUE(0x3)
			 STREAM_MATCH_SID_MASK(0x7)>;
		pmmu1,num_stream_table = <3>;
		pmmu1,num_ptlb = <3>;
		pmmu1,default_stream =
			<STREAM_CFG(PTLB_ID(0x0), STLB_ID(0x0), FETCH_SIZE(SIZE4), PTLB_DIS, STLB_EN)>;
		pmmu1,stream_property =
			<1 STREAM_CFG(PTLB_ID(0x1), STLB_ID(0x3), FETCH_SIZE(SIZE32), PTLB_DIS, STLB_EN)
			 STREAM_MATCH_CFG(DIR_WRITE)
			 STREAM_MATCH_SID_VALUE(0x1)
			 STREAM_MATCH_SID_MASK(0x3)>,
			<2 STREAM_CFG(PTLB_ID(0x2), STLB_ID(0x9), FETCH_SIZE(SIZE1), PTLB_DIS, STLB_EN)
			 STREAM_MATCH_CFG(DIR_WRITE)
			 STREAM_MATCH_SID_VALUE(0x3)
			 STREAM_MATCH_SID_MASK(0x3)>;
		num_pmmu = <2>;
		vmid_mask = <0x7>;
		sysmmu,feature-info = <0x0>;
		port-name = "FIMV_MFD_V17.0 (M0) FIMV_MFD...";
		power-domains = <&pd_mfd>;
	};

	sysmmu_rgbp_s0: sysmmu@17830000 {
		compatible = "samsung,sysmmu-v9";
		reg = <0 0x17830000 0xA000>;
		interrupts = <0 INTREQ__SYSMMU_RGBP_S0_S1_NS IRQ_TYPE_LEVEL_HIGH>,
				<0 INTREQ__SYSMMU_RGBP_S0_S1_S IRQ_TYPE_LEVEL_HIGH>;
		sysmmu,secure-irq;
		sysmmu,secure_base = <0x17840000>;
		qos = <15>;
		#iommu-cells = <0>;
		pmmu0,num_stream_table = <10>;
		pmmu0,num_ptlb = <10>;
		pmmu0,default_stream =
			<STREAM_CFG(PTLB_ID(0x8), STLB_ID(0xe), FETCH_SIZE(SIZE1), PTLB_DIS, STLB_DIS)>;
		pmmu0,stream_property =
			<1 STREAM_CFG(PTLB_ID(0x0), STLB_ID(0x0), FETCH_SIZE(SIZE1), PTLB_DIS, STLB_EN)
			 STREAM_MATCH_CFG(DIR_WRITE)
			 STREAM_MATCH_SID_VALUE(0x0)
			 STREAM_MATCH_SID_MASK(0xF)>,
			<2 STREAM_CFG(PTLB_ID(0x1), STLB_ID(0x1), FETCH_SIZE(SIZE1), PTLB_DIS, STLB_EN)
			 STREAM_MATCH_CFG(DIR_WRITE)
			 STREAM_MATCH_SID_VALUE(0x8)
			 STREAM_MATCH_SID_MASK(0xF)>,
			<3 STREAM_CFG(PTLB_ID(0x2), STLB_ID(0x2), FETCH_SIZE(SIZE1), PTLB_EN, STLB_EN)
			 STREAM_MATCH_CFG(DIR_READ)
			 STREAM_MATCH_SID_VALUE(0x1)
			 STREAM_MATCH_SID_MASK(0xF)>,
			<4 STREAM_CFG(PTLB_ID(0x3), STLB_ID(0x3), FETCH_SIZE(SIZE1), PTLB_DIS, STLB_EN)
			 STREAM_MATCH_CFG(DIR_WRITE)
			 STREAM_MATCH_SID_VALUE(0x1)
			 STREAM_MATCH_SID_MASK(0xF)>,
			<5 STREAM_CFG(PTLB_ID(0x4), STLB_ID(0x4), FETCH_SIZE(SIZE1), PTLB_DIS, STLB_EN)
			 STREAM_MATCH_CFG(DIR_WRITE)
			 STREAM_MATCH_SID_VALUE(0x9)
			 STREAM_MATCH_SID_MASK(0xF)>,
			<6 STREAM_CFG(PTLB_ID(0x5), STLB_ID(0x5), FETCH_SIZE(SIZE1), PTLB_DIS, STLB_EN)
			 STREAM_MATCH_CFG(DIR_WRITE)
			 STREAM_MATCH_SID_VALUE(0x2)
			 STREAM_MATCH_SID_MASK(0xF)>,
			<7 STREAM_CFG(PTLB_ID(0x9), STLB_ID(0xf), FETCH_SIZE(SIZE1), PTLB_DIS, STLB_DIS)
			 STREAM_MATCH_CFG(DIR_WRITE)
			 STREAM_MATCH_SID_VALUE(0x3)
			 STREAM_MATCH_SID_MASK(0xF)>,
			<8 STREAM_CFG(PTLB_ID(0x6), STLB_ID(0x6), FETCH_SIZE(SIZE1), PTLB_EN, STLB_EN)
			 STREAM_MATCH_CFG(DIR_READ)
			 STREAM_MATCH_SID_VALUE(0x4)
			 STREAM_MATCH_SID_MASK(0xF)>,
			<9 STREAM_CFG(PTLB_ID(0x7), STLB_ID(0x7), FETCH_SIZE(SIZE1), PTLB_EN, STLB_EN)
			 STREAM_MATCH_CFG(DIR_READ)
			 STREAM_MATCH_SID_VALUE(0xC)
			 STREAM_MATCH_SID_MASK(0xF)>;
		pmmu1,num_stream_table = <7>;
		pmmu1,num_ptlb = <7>;
		pmmu1,default_stream =
			<STREAM_CFG(PTLB_ID(0x0), STLB_ID(0x8), FETCH_SIZE(SIZE1), PTLB_EN, STLB_EN)>;
		pmmu1,stream_property =
			<1 STREAM_CFG(PTLB_ID(0x1), STLB_ID(0x9), FETCH_SIZE(SIZE1), PTLB_DIS, STLB_EN)
			 STREAM_MATCH_CFG(DIR_WRITE)
			 STREAM_MATCH_SID_VALUE(0x0)
			 STREAM_MATCH_SID_MASK(0xF)>,
			<2 STREAM_CFG(PTLB_ID(0x2), STLB_ID(0xa), FETCH_SIZE(SIZE1), PTLB_EN, STLB_EN)
			 STREAM_MATCH_CFG(DIR_READ)
			 STREAM_MATCH_SID_VALUE(0x1)
			 STREAM_MATCH_SID_MASK(0xF)>,
			<3 STREAM_CFG(PTLB_ID(0x3), STLB_ID(0xb), FETCH_SIZE(SIZE1), PTLB_DIS, STLB_EN)
			 STREAM_MATCH_CFG(DIR_WRITE)
			 STREAM_MATCH_SID_VALUE(0x1)
			 STREAM_MATCH_SID_MASK(0xF)>,
			<4 STREAM_CFG(PTLB_ID(0x4), STLB_ID(0xc), FETCH_SIZE(SIZE1), PTLB_DIS, STLB_EN)
			 STREAM_MATCH_CFG(DIR_WRITE)
			 STREAM_MATCH_SID_VALUE(0x5)
			 STREAM_MATCH_SID_MASK(0xF)>,
			<5 STREAM_CFG(PTLB_ID(0x5), STLB_ID(0xd), FETCH_SIZE(SIZE1), PTLB_DIS, STLB_EN)
			 STREAM_MATCH_CFG(DIR_WRITE)
			 STREAM_MATCH_SID_VALUE(0x2)
			 STREAM_MATCH_SID_MASK(0xF)>,
			<6 STREAM_CFG(PTLB_ID(0x6), STLB_ID(0x10), FETCH_SIZE(SIZE1), PTLB_DIS, STLB_DIS)
			 STREAM_MATCH_CFG(DIR_WRITE)
			 STREAM_MATCH_SID_VALUE(0x3)
			 STREAM_MATCH_SID_MASK(0xF)>;
		num_pmmu = <2>;
		vmid_mask = <0x3>;
		sysmmu,feature-info = <0x0>;
		port-name = "RGBP (M0) RGBP (M0) RGBP (M0...";
		power-domains = <&pd_rgbp>;
	};

	sysmmu_yuvp_s0: sysmmu@17A70000 {
		compatible = "samsung,sysmmu-v9";
		reg = <0 0x17A70000 0xA000>;
		interrupts = <0 INTREQ__SYSMMU_YUVP_S0_S1_NS IRQ_TYPE_LEVEL_HIGH>,
				<0 INTREQ__SYSMMU_YUVP_S0_S1_S IRQ_TYPE_LEVEL_HIGH>;
		sysmmu,secure-irq;
		sysmmu,secure_base = <0x17A80000>;
		qos = <15>;
		#iommu-cells = <0>;
		pmmu0,num_stream_table = <5>;
		pmmu0,num_ptlb = <5>;
		pmmu0,default_stream =
			<STREAM_CFG(PTLB_ID(0x2), STLB_ID(0x7), FETCH_SIZE(SIZE1), PTLB_DIS, STLB_DIS)>;
		pmmu0,stream_property =
			<1 STREAM_CFG(PTLB_ID(0x3), STLB_ID(0x8), FETCH_SIZE(SIZE1), PTLB_DIS, STLB_DIS)
			 STREAM_MATCH_CFG(DIR_WRITE)
			 STREAM_MATCH_SID_VALUE(0x0)
			 STREAM_MATCH_SID_MASK(0x3)>,
			<2 STREAM_CFG(PTLB_ID(0x0), STLB_ID(0x0), FETCH_SIZE(SIZE1), PTLB_EN, STLB_EN)
			 STREAM_MATCH_CFG(DIR_READ)
			 STREAM_MATCH_SID_VALUE(0x1)
			 STREAM_MATCH_SID_MASK(0x3)>,
			<3 STREAM_CFG(PTLB_ID(0x1), STLB_ID(0x1), FETCH_SIZE(SIZE1), PTLB_EN, STLB_EN)
			 STREAM_MATCH_CFG(DIR_READ)
			 STREAM_MATCH_SID_VALUE(0x2)
			 STREAM_MATCH_SID_MASK(0x3)>,
			<4 STREAM_CFG(PTLB_ID(0x4), STLB_ID(0x9), FETCH_SIZE(SIZE1), PTLB_DIS, STLB_DIS)
			 STREAM_MATCH_CFG(DIR_WRITE)
			 STREAM_MATCH_SID_VALUE(0x2)
			 STREAM_MATCH_SID_MASK(0x3)>;
		pmmu1,num_stream_table = <5>;
		pmmu1,num_ptlb = <5>;
		pmmu1,default_stream =
			<STREAM_CFG(PTLB_ID(0x0), STLB_ID(0x2), FETCH_SIZE(SIZE1), PTLB_EN, STLB_EN)>;
		pmmu1,stream_property =
			<1 STREAM_CFG(PTLB_ID(0x1), STLB_ID(0x3), FETCH_SIZE(SIZE1), PTLB_EN, STLB_EN)
			 STREAM_MATCH_CFG(DIR_READ)
			 STREAM_MATCH_SID_VALUE(0x1)
			 STREAM_MATCH_SID_MASK(0x3)>,
			<2 STREAM_CFG(PTLB_ID(0x2), STLB_ID(0x4), FETCH_SIZE(SIZE1), PTLB_EN, STLB_EN)
			 STREAM_MATCH_CFG(DIR_READ)
			 STREAM_MATCH_SID_VALUE(0x2)
			 STREAM_MATCH_SID_MASK(0x3)>,
			<3 STREAM_CFG(PTLB_ID(0x3), STLB_ID(0x5), FETCH_SIZE(SIZE1), PTLB_EN, STLB_EN)
			 STREAM_MATCH_CFG(DIR_READ)
			 STREAM_MATCH_SID_VALUE(0x3)
			 STREAM_MATCH_SID_MASK(0x3)>,
			<4 STREAM_CFG(PTLB_ID(0x4), STLB_ID(0x6), FETCH_SIZE(SIZE1), PTLB_EN, STLB_EN)
			 STREAM_MATCH_CFG(DIR_WRITE)
			 STREAM_MATCH_SID_VALUE(0x3)
			 STREAM_MATCH_SID_MASK(0x3)>;
		num_pmmu = <2>;
		vmid_mask = <0x3>;
		sysmmu,feature-info = <0x0>;
		port-name = "YUVP_M0_CL_VOTFR YUVP_M1_Y_x...";
		power-domains = <&pd_yuvp>;
	};

	sysmmu_dpu_s0: sysmmu@1AC40000 {
		compatible = "samsung,sysmmu-v9";
		reg = <0 0x1AC40000 0xA000>;
		interrupts = <0 INTREQ__DPUF0_SYSMMU_DPUF_S0_S1_NS IRQ_TYPE_LEVEL_HIGH>,
				<0 INTREQ__DPUF0_SYSMMU_DPUF_S0_S1_S IRQ_TYPE_LEVEL_HIGH>;
		sysmmu,secure-irq;
		sysmmu,secure_base = <0x1AC50000>;
		qos = <15>;
		#iommu-cells = <0>;
		pmmu0,num_stream_table = <72>;
		pmmu0,num_ptlb = <16>;
		pmmu0,default_stream =
			<STREAM_CFG(PTLB_ID(0x0), STLB_ID(0x2), FETCH_SIZE(SIZE16), PTLB_DIS, STLB_EN)>;
		pmmu0,stream_property =
			<1 STREAM_CFG(PTLB_ID(0x0), STLB_ID(0x0), FETCH_SIZE(SIZE64), PTLB_DIS, STLB_DIS)
			 STREAM_MATCH_CFG(DIR_READ)
			 STREAM_MATCH_SID_VALUE(0x82)
			 STREAM_MATCH_SID_MASK(0x3FF)>,
			<2 STREAM_CFG(PTLB_ID(0x0), STLB_ID(0x3), FETCH_SIZE(SIZE16), PTLB_DIS, STLB_EN)
			 STREAM_MATCH_CFG(DIR_READ)
			 STREAM_MATCH_SID_VALUE(0x102)
			 STREAM_MATCH_SID_MASK(0x3FF)>,
			<3 STREAM_CFG(PTLB_ID(0x0), STLB_ID(0x4), FETCH_SIZE(SIZE16), PTLB_DIS, STLB_EN)
			 STREAM_MATCH_CFG(DIR_READ)
			 STREAM_MATCH_SID_VALUE(0x202)
			 STREAM_MATCH_SID_MASK(0x3FF)>,
			<4 STREAM_CFG(PTLB_ID(0x0), STLB_ID(0x5), FETCH_SIZE(SIZE16), PTLB_DIS, STLB_EN)
			 STREAM_MATCH_CFG(DIR_READ)
			 STREAM_MATCH_SID_VALUE(0x302)
			 STREAM_MATCH_SID_MASK(0x3FF)>,
			<5 STREAM_CFG(PTLB_ID(0x0), STLB_ID(0xa), FETCH_SIZE(SIZE2), PTLB_DIS, STLB_EN)
			 STREAM_MATCH_CFG(DIR_READ)
			 STREAM_MATCH_SID_VALUE(0x182)
			 STREAM_MATCH_SID_MASK(0x3FF)>,
			<6 STREAM_CFG(PTLB_ID(0x0), STLB_ID(0xe), FETCH_SIZE(SIZE2), PTLB_DIS, STLB_EN)
			 STREAM_MATCH_CFG(DIR_READ)
			 STREAM_MATCH_SID_VALUE(0x282)
			 STREAM_MATCH_SID_MASK(0x3FF)>,
			<7 STREAM_CFG(PTLB_ID(0x0), STLB_ID(0x11), FETCH_SIZE(SIZE2), PTLB_DIS, STLB_EN)
			 STREAM_MATCH_CFG(DIR_READ)
			 STREAM_MATCH_SID_VALUE(0x382)
			 STREAM_MATCH_SID_MASK(0x3FF)>,
			<8 STREAM_CFG(PTLB_ID(0x1), STLB_ID(0x6), FETCH_SIZE(SIZE2), PTLB_DIS, STLB_EN)
			 STREAM_MATCH_CFG(DIR_READ)
			 STREAM_MATCH_SID_VALUE(0x40)
			 STREAM_MATCH_SID_MASK(0x3FF)>,
			<9 STREAM_CFG(PTLB_ID(0x1), STLB_ID(0x9), FETCH_SIZE(SIZE2), PTLB_DIS, STLB_EN)
			 STREAM_MATCH_CFG(DIR_READ)
			 STREAM_MATCH_SID_VALUE(0x140)
			 STREAM_MATCH_SID_MASK(0x3FF)>,
			<10 STREAM_CFG(PTLB_ID(0x1), STLB_ID(0xd), FETCH_SIZE(SIZE2), PTLB_DIS, STLB_EN)
			 STREAM_MATCH_CFG(DIR_READ)
			 STREAM_MATCH_SID_VALUE(0x240)
			 STREAM_MATCH_SID_MASK(0x3FF)>,
			<11 STREAM_CFG(PTLB_ID(0x1), STLB_ID(0x10), FETCH_SIZE(SIZE2), PTLB_DIS, STLB_EN)
			 STREAM_MATCH_CFG(DIR_READ)
			 STREAM_MATCH_SID_VALUE(0x340)
			 STREAM_MATCH_SID_MASK(0x3FF)>,
			<12 STREAM_CFG(PTLB_ID(0x2), STLB_ID(0x2), FETCH_SIZE(SIZE16), PTLB_DIS, STLB_EN)
			 STREAM_MATCH_CFG(DIR_READ)
			 STREAM_MATCH_SID_VALUE(0x6)
			 STREAM_MATCH_SID_MASK(0x3FF)>,
			<13 STREAM_CFG(PTLB_ID(0x2), STLB_ID(0x0), FETCH_SIZE(SIZE64), PTLB_DIS, STLB_DIS)
			 STREAM_MATCH_CFG(DIR_READ)
			 STREAM_MATCH_SID_VALUE(0x86)
			 STREAM_MATCH_SID_MASK(0x3FF)>,
			<14 STREAM_CFG(PTLB_ID(0x2), STLB_ID(0x3), FETCH_SIZE(SIZE16), PTLB_DIS, STLB_EN)
			 STREAM_MATCH_CFG(DIR_READ)
			 STREAM_MATCH_SID_VALUE(0x106)
			 STREAM_MATCH_SID_MASK(0x3FF)>,
			<15 STREAM_CFG(PTLB_ID(0x2), STLB_ID(0x4), FETCH_SIZE(SIZE16), PTLB_DIS, STLB_EN)
			 STREAM_MATCH_CFG(DIR_READ)
			 STREAM_MATCH_SID_VALUE(0x206)
			 STREAM_MATCH_SID_MASK(0x3FF)>,
			<16 STREAM_CFG(PTLB_ID(0x2), STLB_ID(0x5), FETCH_SIZE(SIZE16), PTLB_DIS, STLB_EN)
			 STREAM_MATCH_CFG(DIR_READ)
			 STREAM_MATCH_SID_VALUE(0x306)
			 STREAM_MATCH_SID_MASK(0x3FF)>,
			<17 STREAM_CFG(PTLB_ID(0x2), STLB_ID(0xa), FETCH_SIZE(SIZE2), PTLB_DIS, STLB_EN)
			 STREAM_MATCH_CFG(DIR_READ)
			 STREAM_MATCH_SID_VALUE(0x186)
			 STREAM_MATCH_SID_MASK(0x3FF)>,
			<18 STREAM_CFG(PTLB_ID(0x2), STLB_ID(0xe), FETCH_SIZE(SIZE2), PTLB_DIS, STLB_EN)
			 STREAM_MATCH_CFG(DIR_READ)
			 STREAM_MATCH_SID_VALUE(0x286)
			 STREAM_MATCH_SID_MASK(0x3FF)>,
			<19 STREAM_CFG(PTLB_ID(0x2), STLB_ID(0x11), FETCH_SIZE(SIZE2), PTLB_DIS, STLB_EN)
			 STREAM_MATCH_CFG(DIR_READ)
			 STREAM_MATCH_SID_VALUE(0x386)
			 STREAM_MATCH_SID_MASK(0x3FF)>,
			<20 STREAM_CFG(PTLB_ID(0x3), STLB_ID(0x1), FETCH_SIZE(SIZE64), PTLB_DIS, STLB_DIS)
			 STREAM_MATCH_CFG(DIR_READ)
			 STREAM_MATCH_SID_VALUE(0xA7)
			 STREAM_MATCH_SID_MASK(0x3FF)>,
			<21 STREAM_CFG(PTLB_ID(0x3), STLB_ID(0xb), FETCH_SIZE(SIZE2), PTLB_DIS, STLB_EN)
			 STREAM_MATCH_CFG(DIR_READ)
			 STREAM_MATCH_SID_VALUE(0x1A7)
			 STREAM_MATCH_SID_MASK(0x3FF)>,
			<22 STREAM_CFG(PTLB_ID(0x3), STLB_ID(0xf), FETCH_SIZE(SIZE2), PTLB_DIS, STLB_EN)
			 STREAM_MATCH_CFG(DIR_READ)
			 STREAM_MATCH_SID_VALUE(0x2A7)
			 STREAM_MATCH_SID_MASK(0x3FF)>,
			<23 STREAM_CFG(PTLB_ID(0x3), STLB_ID(0x12), FETCH_SIZE(SIZE2), PTLB_DIS, STLB_EN)
			 STREAM_MATCH_CFG(DIR_READ)
			 STREAM_MATCH_SID_VALUE(0x3A7)
			 STREAM_MATCH_SID_MASK(0x3FF)>,
			<24 STREAM_CFG(PTLB_ID(0x4), STLB_ID(0x6), FETCH_SIZE(SIZE2), PTLB_DIS, STLB_EN)
			 STREAM_MATCH_CFG(DIR_READ)
			 STREAM_MATCH_SID_VALUE(0x44)
			 STREAM_MATCH_SID_MASK(0x3FF)>,
			<25 STREAM_CFG(PTLB_ID(0x4), STLB_ID(0x9), FETCH_SIZE(SIZE2), PTLB_DIS, STLB_EN)
			 STREAM_MATCH_CFG(DIR_READ)
			 STREAM_MATCH_SID_VALUE(0x144)
			 STREAM_MATCH_SID_MASK(0x3FF)>,
			<26 STREAM_CFG(PTLB_ID(0x4), STLB_ID(0xd), FETCH_SIZE(SIZE2), PTLB_DIS, STLB_EN)
			 STREAM_MATCH_CFG(DIR_READ)
			 STREAM_MATCH_SID_VALUE(0x244)
			 STREAM_MATCH_SID_MASK(0x3FF)>,
			<27 STREAM_CFG(PTLB_ID(0x4), STLB_ID(0x10), FETCH_SIZE(SIZE2), PTLB_DIS, STLB_EN)
			 STREAM_MATCH_CFG(DIR_READ)
			 STREAM_MATCH_SID_VALUE(0x344)
			 STREAM_MATCH_SID_MASK(0x3FF)>,
			<28 STREAM_CFG(PTLB_ID(0x4), STLB_ID(0x7), FETCH_SIZE(SIZE2), PTLB_DIS, STLB_EN)
			 STREAM_MATCH_CFG(DIR_READ)
			 STREAM_MATCH_SID_VALUE(0xC4)
			 STREAM_MATCH_SID_MASK(0x3FF)>,
			<29 STREAM_CFG(PTLB_ID(0x4), STLB_ID(0xc), FETCH_SIZE(SIZE2), PTLB_DIS, STLB_EN)
			 STREAM_MATCH_CFG(DIR_READ)
			 STREAM_MATCH_SID_VALUE(0x1C4)
			 STREAM_MATCH_SID_MASK(0x3FF)>,
			<30 STREAM_CFG(PTLB_ID(0x4), STLB_ID(0x1a), FETCH_SIZE(SIZE1), PTLB_DIS, STLB_EN)
			 STREAM_MATCH_CFG(DIR_READ)
			 STREAM_MATCH_SID_VALUE(0x2C4)
			 STREAM_MATCH_SID_MASK(0x3FF)>,
			<31 STREAM_CFG(PTLB_ID(0x5), STLB_ID(0x8), FETCH_SIZE(SIZE2), PTLB_DIS, STLB_EN)
			 STREAM_MATCH_CFG(DIR_READ)
			 STREAM_MATCH_SID_VALUE(0xE5)
			 STREAM_MATCH_SID_MASK(0x3FF)>,
			<32 STREAM_CFG(PTLB_ID(0x5), STLB_ID(0x15), FETCH_SIZE(SIZE1), PTLB_DIS, STLB_EN)
			 STREAM_MATCH_CFG(DIR_READ)
			 STREAM_MATCH_SID_VALUE(0x1E5)
			 STREAM_MATCH_SID_MASK(0x3FF)>,
			<33 STREAM_CFG(PTLB_ID(0x5), STLB_ID(0x1b), FETCH_SIZE(SIZE1), PTLB_DIS, STLB_EN)
			 STREAM_MATCH_CFG(DIR_READ)
			 STREAM_MATCH_SID_VALUE(0x2E5)
			 STREAM_MATCH_SID_MASK(0x3FF)>,
			<34 STREAM_CFG(PTLB_ID(0x6), STLB_ID(0x2), FETCH_SIZE(SIZE16), PTLB_DIS, STLB_EN)
			 STREAM_MATCH_CFG(DIR_READ)
			 STREAM_MATCH_SID_VALUE(0xA)
			 STREAM_MATCH_SID_MASK(0x3FF)>,
			<35 STREAM_CFG(PTLB_ID(0x6), STLB_ID(0x0), FETCH_SIZE(SIZE64), PTLB_DIS, STLB_DIS)
			 STREAM_MATCH_CFG(DIR_READ)
			 STREAM_MATCH_SID_VALUE(0x8A)
			 STREAM_MATCH_SID_MASK(0x3FF)>,
			<36 STREAM_CFG(PTLB_ID(0x6), STLB_ID(0x3), FETCH_SIZE(SIZE16), PTLB_DIS, STLB_EN)
			 STREAM_MATCH_CFG(DIR_READ)
			 STREAM_MATCH_SID_VALUE(0x10A)
			 STREAM_MATCH_SID_MASK(0x3FF)>,
			<37 STREAM_CFG(PTLB_ID(0x6), STLB_ID(0x4), FETCH_SIZE(SIZE16), PTLB_DIS, STLB_EN)
			 STREAM_MATCH_CFG(DIR_READ)
			 STREAM_MATCH_SID_VALUE(0x20A)
			 STREAM_MATCH_SID_MASK(0x3FF)>,
			<38 STREAM_CFG(PTLB_ID(0x6), STLB_ID(0x5), FETCH_SIZE(SIZE16), PTLB_DIS, STLB_EN)
			 STREAM_MATCH_CFG(DIR_READ)
			 STREAM_MATCH_SID_VALUE(0x30A)
			 STREAM_MATCH_SID_MASK(0x3FF)>,
			<39 STREAM_CFG(PTLB_ID(0x6), STLB_ID(0xa), FETCH_SIZE(SIZE2), PTLB_DIS, STLB_EN)
			 STREAM_MATCH_CFG(DIR_READ)
			 STREAM_MATCH_SID_VALUE(0x18A)
			 STREAM_MATCH_SID_MASK(0x3FF)>,
			<40 STREAM_CFG(PTLB_ID(0x6), STLB_ID(0xe), FETCH_SIZE(SIZE2), PTLB_DIS, STLB_EN)
			 STREAM_MATCH_CFG(DIR_READ)
			 STREAM_MATCH_SID_VALUE(0x28A)
			 STREAM_MATCH_SID_MASK(0x3FF)>,
			<41 STREAM_CFG(PTLB_ID(0x6), STLB_ID(0x11), FETCH_SIZE(SIZE2), PTLB_DIS, STLB_EN)
			 STREAM_MATCH_CFG(DIR_READ)
			 STREAM_MATCH_SID_VALUE(0x38A)
			 STREAM_MATCH_SID_MASK(0x3FF)>,
			<42 STREAM_CFG(PTLB_ID(0x7), STLB_ID(0x6), FETCH_SIZE(SIZE2), PTLB_DIS, STLB_EN)
			 STREAM_MATCH_CFG(DIR_READ)
			 STREAM_MATCH_SID_VALUE(0x48)
			 STREAM_MATCH_SID_MASK(0x3FF)>,
			<43 STREAM_CFG(PTLB_ID(0x7), STLB_ID(0x9), FETCH_SIZE(SIZE2), PTLB_DIS, STLB_EN)
			 STREAM_MATCH_CFG(DIR_READ)
			 STREAM_MATCH_SID_VALUE(0x148)
			 STREAM_MATCH_SID_MASK(0x3FF)>,
			<44 STREAM_CFG(PTLB_ID(0x7), STLB_ID(0xd), FETCH_SIZE(SIZE2), PTLB_DIS, STLB_EN)
			 STREAM_MATCH_CFG(DIR_READ)
			 STREAM_MATCH_SID_VALUE(0x248)
			 STREAM_MATCH_SID_MASK(0x3FF)>,
			<45 STREAM_CFG(PTLB_ID(0x7), STLB_ID(0x10), FETCH_SIZE(SIZE2), PTLB_DIS, STLB_EN)
			 STREAM_MATCH_CFG(DIR_READ)
			 STREAM_MATCH_SID_VALUE(0x248)
			 STREAM_MATCH_SID_MASK(0x3FF)>,
			<46 STREAM_CFG(PTLB_ID(0x8), STLB_ID(0x2), FETCH_SIZE(SIZE16), PTLB_DIS, STLB_EN)
			 STREAM_MATCH_CFG(DIR_READ)
			 STREAM_MATCH_SID_VALUE(0xE)
			 STREAM_MATCH_SID_MASK(0x3FF)>,
			<47 STREAM_CFG(PTLB_ID(0x8), STLB_ID(0x0), FETCH_SIZE(SIZE64), PTLB_DIS, STLB_DIS)
			 STREAM_MATCH_CFG(DIR_READ)
			 STREAM_MATCH_SID_VALUE(0x8E)
			 STREAM_MATCH_SID_MASK(0x3FF)>,
			<48 STREAM_CFG(PTLB_ID(0x8), STLB_ID(0x3), FETCH_SIZE(SIZE16), PTLB_DIS, STLB_EN)
			 STREAM_MATCH_CFG(DIR_READ)
			 STREAM_MATCH_SID_VALUE(0x10E)
			 STREAM_MATCH_SID_MASK(0x3FF)>,
			<49 STREAM_CFG(PTLB_ID(0x8), STLB_ID(0x4), FETCH_SIZE(SIZE16), PTLB_DIS, STLB_EN)
			 STREAM_MATCH_CFG(DIR_READ)
			 STREAM_MATCH_SID_VALUE(0x20E)
			 STREAM_MATCH_SID_MASK(0x3FF)>,
			<50 STREAM_CFG(PTLB_ID(0x8), STLB_ID(0x5), FETCH_SIZE(SIZE16), PTLB_DIS, STLB_EN)
			 STREAM_MATCH_CFG(DIR_READ)
			 STREAM_MATCH_SID_VALUE(0x30E)
			 STREAM_MATCH_SID_MASK(0x3FF)>,
			<51 STREAM_CFG(PTLB_ID(0x8), STLB_ID(0xa), FETCH_SIZE(SIZE2), PTLB_DIS, STLB_EN)
			 STREAM_MATCH_CFG(DIR_READ)
			 STREAM_MATCH_SID_VALUE(0x18E)
			 STREAM_MATCH_SID_MASK(0x3FF)>,
			<52 STREAM_CFG(PTLB_ID(0x8), STLB_ID(0xe), FETCH_SIZE(SIZE2), PTLB_DIS, STLB_EN)
			 STREAM_MATCH_CFG(DIR_READ)
			 STREAM_MATCH_SID_VALUE(0x28E)
			 STREAM_MATCH_SID_MASK(0x3FF)>,
			<53 STREAM_CFG(PTLB_ID(0x8), STLB_ID(0x11), FETCH_SIZE(SIZE2), PTLB_DIS, STLB_EN)
			 STREAM_MATCH_CFG(DIR_READ)
			 STREAM_MATCH_SID_VALUE(0x38E)
			 STREAM_MATCH_SID_MASK(0x3FF)>,
			<54 STREAM_CFG(PTLB_ID(0x9), STLB_ID(0x1), FETCH_SIZE(SIZE64), PTLB_DIS, STLB_DIS)
			 STREAM_MATCH_CFG(DIR_READ)
			 STREAM_MATCH_SID_VALUE(0xAF)
			 STREAM_MATCH_SID_MASK(0x3FF)>,
			<55 STREAM_CFG(PTLB_ID(0x9), STLB_ID(0xb), FETCH_SIZE(SIZE2), PTLB_DIS, STLB_EN)
			 STREAM_MATCH_CFG(DIR_READ)
			 STREAM_MATCH_SID_VALUE(0x1AF)
			 STREAM_MATCH_SID_MASK(0x3FF)>,
			<56 STREAM_CFG(PTLB_ID(0x9), STLB_ID(0xf), FETCH_SIZE(SIZE2), PTLB_DIS, STLB_EN)
			 STREAM_MATCH_CFG(DIR_READ)
			 STREAM_MATCH_SID_VALUE(0x2AF)
			 STREAM_MATCH_SID_MASK(0x3FF)>,
			<57 STREAM_CFG(PTLB_ID(0x9), STLB_ID(0x12), FETCH_SIZE(SIZE2), PTLB_DIS, STLB_EN)
			 STREAM_MATCH_CFG(DIR_READ)
			 STREAM_MATCH_SID_VALUE(0x3AF)
			 STREAM_MATCH_SID_MASK(0x3FF)>,
			<58 STREAM_CFG(PTLB_ID(0xa), STLB_ID(0x6), FETCH_SIZE(SIZE2), PTLB_DIS, STLB_EN)
			 STREAM_MATCH_CFG(DIR_READ)
			 STREAM_MATCH_SID_VALUE(0x4C)
			 STREAM_MATCH_SID_MASK(0x3FF)>,
			<59 STREAM_CFG(PTLB_ID(0xa), STLB_ID(0x9), FETCH_SIZE(SIZE2), PTLB_DIS, STLB_EN)
			 STREAM_MATCH_CFG(DIR_READ)
			 STREAM_MATCH_SID_VALUE(0x14C)
			 STREAM_MATCH_SID_MASK(0x3FF)>,
			<60 STREAM_CFG(PTLB_ID(0xa), STLB_ID(0xd), FETCH_SIZE(SIZE2), PTLB_DIS, STLB_EN)
			 STREAM_MATCH_CFG(DIR_READ)
			 STREAM_MATCH_SID_VALUE(0x24C)
			 STREAM_MATCH_SID_MASK(0x3FF)>,
			<61 STREAM_CFG(PTLB_ID(0xa), STLB_ID(0x10), FETCH_SIZE(SIZE2), PTLB_DIS, STLB_EN)
			 STREAM_MATCH_CFG(DIR_READ)
			 STREAM_MATCH_SID_VALUE(0x24C)
			 STREAM_MATCH_SID_MASK(0x3FF)>,
			<62 STREAM_CFG(PTLB_ID(0xa), STLB_ID(0x7), FETCH_SIZE(SIZE2), PTLB_DIS, STLB_EN)
			 STREAM_MATCH_CFG(DIR_READ)
			 STREAM_MATCH_SID_VALUE(0xCC)
			 STREAM_MATCH_SID_MASK(0x3FF)>,
			<63 STREAM_CFG(PTLB_ID(0xa), STLB_ID(0xc), FETCH_SIZE(SIZE2), PTLB_DIS, STLB_EN)
			 STREAM_MATCH_CFG(DIR_READ)
			 STREAM_MATCH_SID_VALUE(0x1CC)
			 STREAM_MATCH_SID_MASK(0x3FF)>,
			<64 STREAM_CFG(PTLB_ID(0xa), STLB_ID(0x1a), FETCH_SIZE(SIZE1), PTLB_DIS, STLB_EN)
			 STREAM_MATCH_CFG(DIR_READ)
			 STREAM_MATCH_SID_VALUE(0x2CC)
			 STREAM_MATCH_SID_MASK(0x3FF)>,
			<65 STREAM_CFG(PTLB_ID(0xb), STLB_ID(0x8), FETCH_SIZE(SIZE2), PTLB_DIS, STLB_EN)
			 STREAM_MATCH_CFG(DIR_READ)
			 STREAM_MATCH_SID_VALUE(0xED)
			 STREAM_MATCH_SID_MASK(0x3FF)>,
			<66 STREAM_CFG(PTLB_ID(0xb), STLB_ID(0x15), FETCH_SIZE(SIZE1), PTLB_DIS, STLB_EN)
			 STREAM_MATCH_CFG(DIR_READ)
			 STREAM_MATCH_SID_VALUE(0x1ED)
			 STREAM_MATCH_SID_MASK(0x3FF)>,
			<67 STREAM_CFG(PTLB_ID(0xb), STLB_ID(0x1b), FETCH_SIZE(SIZE1), PTLB_DIS, STLB_EN)
			 STREAM_MATCH_CFG(DIR_READ)
			 STREAM_MATCH_SID_VALUE(0x2ED)
			 STREAM_MATCH_SID_MASK(0x3FF)>,
			<68 STREAM_CFG(PTLB_ID(0xc), STLB_ID(0x16), FETCH_SIZE(SIZE1), PTLB_DIS, STLB_EN)
			 STREAM_MATCH_CFG(DIR_READ)
			 STREAM_MATCH_SID_VALUE(0x10)
			 STREAM_MATCH_SID_MASK(0x3FF)>,
			<69 STREAM_CFG(PTLB_ID(0xd), STLB_ID(0x17), FETCH_SIZE(SIZE1), PTLB_DIS, STLB_EN)
			 STREAM_MATCH_CFG(DIR_READ)
			 STREAM_MATCH_SID_VALUE(0x14)
			 STREAM_MATCH_SID_MASK(0x3FF)>,
			<70 STREAM_CFG(PTLB_ID(0xe), STLB_ID(0x18), FETCH_SIZE(SIZE1), PTLB_DIS, STLB_EN)
			 STREAM_MATCH_CFG(DIR_WRITE)
			 STREAM_MATCH_SID_VALUE(0x0)
			 STREAM_MATCH_SID_MASK(0x3FF)>,
			<71 STREAM_CFG(PTLB_ID(0xf), STLB_ID(0x19), FETCH_SIZE(SIZE1), PTLB_DIS, STLB_EN)
			 STREAM_MATCH_CFG(DIR_WRITE)
			 STREAM_MATCH_SID_VALUE(0x1)
			 STREAM_MATCH_SID_MASK(0x3FF)>;
		pmmu1,num_stream_table = <71>;
		pmmu1,num_ptlb = <15>;
		pmmu1,default_stream =
			<STREAM_CFG(PTLB_ID(0x0), STLB_ID(0x2), FETCH_SIZE(SIZE16), PTLB_DIS, STLB_EN)>;
		pmmu1,stream_property =
			<1 STREAM_CFG(PTLB_ID(0x0), STLB_ID(0x0), FETCH_SIZE(SIZE64), PTLB_DIS, STLB_DIS)
			 STREAM_MATCH_CFG(DIR_READ)
			 STREAM_MATCH_SID_VALUE(0x82)
			 STREAM_MATCH_SID_MASK(0x3FF)>,
			<2 STREAM_CFG(PTLB_ID(0x0), STLB_ID(0x3), FETCH_SIZE(SIZE16), PTLB_DIS, STLB_EN)
			 STREAM_MATCH_CFG(DIR_READ)
			 STREAM_MATCH_SID_VALUE(0x102)
			 STREAM_MATCH_SID_MASK(0x3FF)>,
			<3 STREAM_CFG(PTLB_ID(0x0), STLB_ID(0x4), FETCH_SIZE(SIZE16), PTLB_DIS, STLB_EN)
			 STREAM_MATCH_CFG(DIR_READ)
			 STREAM_MATCH_SID_VALUE(0x202)
			 STREAM_MATCH_SID_MASK(0x3FF)>,
			<4 STREAM_CFG(PTLB_ID(0x0), STLB_ID(0x5), FETCH_SIZE(SIZE16), PTLB_DIS, STLB_EN)
			 STREAM_MATCH_CFG(DIR_READ)
			 STREAM_MATCH_SID_VALUE(0x302)
			 STREAM_MATCH_SID_MASK(0x3FF)>,
			<5 STREAM_CFG(PTLB_ID(0x0), STLB_ID(0xa), FETCH_SIZE(SIZE2), PTLB_DIS, STLB_EN)
			 STREAM_MATCH_CFG(DIR_READ)
			 STREAM_MATCH_SID_VALUE(0x182)
			 STREAM_MATCH_SID_MASK(0x3FF)>,
			<6 STREAM_CFG(PTLB_ID(0x0), STLB_ID(0xe), FETCH_SIZE(SIZE2), PTLB_DIS, STLB_EN)
			 STREAM_MATCH_CFG(DIR_READ)
			 STREAM_MATCH_SID_VALUE(0x282)
			 STREAM_MATCH_SID_MASK(0x3FF)>,
			<7 STREAM_CFG(PTLB_ID(0x0), STLB_ID(0x11), FETCH_SIZE(SIZE2), PTLB_DIS, STLB_EN)
			 STREAM_MATCH_CFG(DIR_READ)
			 STREAM_MATCH_SID_VALUE(0x382)
			 STREAM_MATCH_SID_MASK(0x3FF)>,
			<8 STREAM_CFG(PTLB_ID(0x1), STLB_ID(0x6), FETCH_SIZE(SIZE2), PTLB_DIS, STLB_EN)
			 STREAM_MATCH_CFG(DIR_READ)
			 STREAM_MATCH_SID_VALUE(0x40)
			 STREAM_MATCH_SID_MASK(0x3FF)>,
			<9 STREAM_CFG(PTLB_ID(0x1), STLB_ID(0x9), FETCH_SIZE(SIZE2), PTLB_DIS, STLB_EN)
			 STREAM_MATCH_CFG(DIR_READ)
			 STREAM_MATCH_SID_VALUE(0x140)
			 STREAM_MATCH_SID_MASK(0x3FF)>,
			<10 STREAM_CFG(PTLB_ID(0x1), STLB_ID(0xd), FETCH_SIZE(SIZE2), PTLB_DIS, STLB_EN)
			 STREAM_MATCH_CFG(DIR_READ)
			 STREAM_MATCH_SID_VALUE(0x240)
			 STREAM_MATCH_SID_MASK(0x3FF)>,
			<11 STREAM_CFG(PTLB_ID(0x1), STLB_ID(0x10), FETCH_SIZE(SIZE2), PTLB_DIS, STLB_EN)
			 STREAM_MATCH_CFG(DIR_READ)
			 STREAM_MATCH_SID_VALUE(0x340)
			 STREAM_MATCH_SID_MASK(0x3FF)>,
			<12 STREAM_CFG(PTLB_ID(0x2), STLB_ID(0x2), FETCH_SIZE(SIZE16), PTLB_DIS, STLB_EN)
			 STREAM_MATCH_CFG(DIR_READ)
			 STREAM_MATCH_SID_VALUE(0x6)
			 STREAM_MATCH_SID_MASK(0x3FF)>,
			<13 STREAM_CFG(PTLB_ID(0x2), STLB_ID(0x0), FETCH_SIZE(SIZE64), PTLB_DIS, STLB_DIS)
			 STREAM_MATCH_CFG(DIR_READ)
			 STREAM_MATCH_SID_VALUE(0x86)
			 STREAM_MATCH_SID_MASK(0x3FF)>,
			<14 STREAM_CFG(PTLB_ID(0x2), STLB_ID(0x3), FETCH_SIZE(SIZE16), PTLB_DIS, STLB_EN)
			 STREAM_MATCH_CFG(DIR_READ)
			 STREAM_MATCH_SID_VALUE(0x106)
			 STREAM_MATCH_SID_MASK(0x3FF)>,
			<15 STREAM_CFG(PTLB_ID(0x2), STLB_ID(0x4), FETCH_SIZE(SIZE16), PTLB_DIS, STLB_EN)
			 STREAM_MATCH_CFG(DIR_READ)
			 STREAM_MATCH_SID_VALUE(0x206)
			 STREAM_MATCH_SID_MASK(0x3FF)>,
			<16 STREAM_CFG(PTLB_ID(0x2), STLB_ID(0x5), FETCH_SIZE(SIZE16), PTLB_DIS, STLB_EN)
			 STREAM_MATCH_CFG(DIR_READ)
			 STREAM_MATCH_SID_VALUE(0x306)
			 STREAM_MATCH_SID_MASK(0x3FF)>,
			<17 STREAM_CFG(PTLB_ID(0x2), STLB_ID(0xa), FETCH_SIZE(SIZE2), PTLB_DIS, STLB_EN)
			 STREAM_MATCH_CFG(DIR_READ)
			 STREAM_MATCH_SID_VALUE(0x186)
			 STREAM_MATCH_SID_MASK(0x3FF)>,
			<18 STREAM_CFG(PTLB_ID(0x2), STLB_ID(0xe), FETCH_SIZE(SIZE2), PTLB_DIS, STLB_EN)
			 STREAM_MATCH_CFG(DIR_READ)
			 STREAM_MATCH_SID_VALUE(0x286)
			 STREAM_MATCH_SID_MASK(0x3FF)>,
			<19 STREAM_CFG(PTLB_ID(0x2), STLB_ID(0x11), FETCH_SIZE(SIZE2), PTLB_DIS, STLB_EN)
			 STREAM_MATCH_CFG(DIR_READ)
			 STREAM_MATCH_SID_VALUE(0x386)
			 STREAM_MATCH_SID_MASK(0x3FF)>,
			<20 STREAM_CFG(PTLB_ID(0x3), STLB_ID(0x1), FETCH_SIZE(SIZE64), PTLB_DIS, STLB_DIS)
			 STREAM_MATCH_CFG(DIR_READ)
			 STREAM_MATCH_SID_VALUE(0xA7)
			 STREAM_MATCH_SID_MASK(0x3FF)>,
			<21 STREAM_CFG(PTLB_ID(0x3), STLB_ID(0xb), FETCH_SIZE(SIZE2), PTLB_DIS, STLB_EN)
			 STREAM_MATCH_CFG(DIR_READ)
			 STREAM_MATCH_SID_VALUE(0x1A7)
			 STREAM_MATCH_SID_MASK(0x3FF)>,
			<22 STREAM_CFG(PTLB_ID(0x3), STLB_ID(0xf), FETCH_SIZE(SIZE2), PTLB_DIS, STLB_EN)
			 STREAM_MATCH_CFG(DIR_READ)
			 STREAM_MATCH_SID_VALUE(0x2A7)
			 STREAM_MATCH_SID_MASK(0x3FF)>,
			<23 STREAM_CFG(PTLB_ID(0x3), STLB_ID(0x12), FETCH_SIZE(SIZE2), PTLB_DIS, STLB_EN)
			 STREAM_MATCH_CFG(DIR_READ)
			 STREAM_MATCH_SID_VALUE(0x3A7)
			 STREAM_MATCH_SID_MASK(0x3FF)>,
			<24 STREAM_CFG(PTLB_ID(0x4), STLB_ID(0x6), FETCH_SIZE(SIZE2), PTLB_DIS, STLB_EN)
			 STREAM_MATCH_CFG(DIR_READ)
			 STREAM_MATCH_SID_VALUE(0x44)
			 STREAM_MATCH_SID_MASK(0x3FF)>,
			<25 STREAM_CFG(PTLB_ID(0x4), STLB_ID(0x9), FETCH_SIZE(SIZE2), PTLB_DIS, STLB_EN)
			 STREAM_MATCH_CFG(DIR_READ)
			 STREAM_MATCH_SID_VALUE(0x144)
			 STREAM_MATCH_SID_MASK(0x3FF)>,
			<26 STREAM_CFG(PTLB_ID(0x4), STLB_ID(0xd), FETCH_SIZE(SIZE2), PTLB_DIS, STLB_EN)
			 STREAM_MATCH_CFG(DIR_READ)
			 STREAM_MATCH_SID_VALUE(0x244)
			 STREAM_MATCH_SID_MASK(0x3FF)>,
			<27 STREAM_CFG(PTLB_ID(0x4), STLB_ID(0x10), FETCH_SIZE(SIZE2), PTLB_DIS, STLB_EN)
			 STREAM_MATCH_CFG(DIR_READ)
			 STREAM_MATCH_SID_VALUE(0x344)
			 STREAM_MATCH_SID_MASK(0x3FF)>,
			<28 STREAM_CFG(PTLB_ID(0x4), STLB_ID(0x7), FETCH_SIZE(SIZE2), PTLB_DIS, STLB_EN)
			 STREAM_MATCH_CFG(DIR_READ)
			 STREAM_MATCH_SID_VALUE(0xC4)
			 STREAM_MATCH_SID_MASK(0x3FF)>,
			<29 STREAM_CFG(PTLB_ID(0x4), STLB_ID(0xc), FETCH_SIZE(SIZE2), PTLB_DIS, STLB_EN)
			 STREAM_MATCH_CFG(DIR_READ)
			 STREAM_MATCH_SID_VALUE(0x1C4)
			 STREAM_MATCH_SID_MASK(0x3FF)>,
			<30 STREAM_CFG(PTLB_ID(0x4), STLB_ID(0x1a), FETCH_SIZE(SIZE1), PTLB_DIS, STLB_EN)
			 STREAM_MATCH_CFG(DIR_READ)
			 STREAM_MATCH_SID_VALUE(0x2C4)
			 STREAM_MATCH_SID_MASK(0x3FF)>,
			<31 STREAM_CFG(PTLB_ID(0x5), STLB_ID(0x8), FETCH_SIZE(SIZE2), PTLB_DIS, STLB_EN)
			 STREAM_MATCH_CFG(DIR_READ)
			 STREAM_MATCH_SID_VALUE(0xE5)
			 STREAM_MATCH_SID_MASK(0x3FF)>,
			<32 STREAM_CFG(PTLB_ID(0x5), STLB_ID(0x15), FETCH_SIZE(SIZE1), PTLB_DIS, STLB_EN)
			 STREAM_MATCH_CFG(DIR_READ)
			 STREAM_MATCH_SID_VALUE(0x1E5)
			 STREAM_MATCH_SID_MASK(0x3FF)>,
			<33 STREAM_CFG(PTLB_ID(0x5), STLB_ID(0x1b), FETCH_SIZE(SIZE1), PTLB_DIS, STLB_EN)
			 STREAM_MATCH_CFG(DIR_READ)
			 STREAM_MATCH_SID_VALUE(0x2E5)
			 STREAM_MATCH_SID_MASK(0x3FF)>,
			<34 STREAM_CFG(PTLB_ID(0x6), STLB_ID(0x2), FETCH_SIZE(SIZE16), PTLB_DIS, STLB_EN)
			 STREAM_MATCH_CFG(DIR_READ)
			 STREAM_MATCH_SID_VALUE(0xA)
			 STREAM_MATCH_SID_MASK(0x3FF)>,
			<35 STREAM_CFG(PTLB_ID(0x6), STLB_ID(0x0), FETCH_SIZE(SIZE64), PTLB_DIS, STLB_DIS)
			 STREAM_MATCH_CFG(DIR_READ)
			 STREAM_MATCH_SID_VALUE(0x8A)
			 STREAM_MATCH_SID_MASK(0x3FF)>,
			<36 STREAM_CFG(PTLB_ID(0x6), STLB_ID(0x3), FETCH_SIZE(SIZE16), PTLB_DIS, STLB_EN)
			 STREAM_MATCH_CFG(DIR_READ)
			 STREAM_MATCH_SID_VALUE(0x10A)
			 STREAM_MATCH_SID_MASK(0x3FF)>,
			<37 STREAM_CFG(PTLB_ID(0x6), STLB_ID(0x4), FETCH_SIZE(SIZE16), PTLB_DIS, STLB_EN)
			 STREAM_MATCH_CFG(DIR_READ)
			 STREAM_MATCH_SID_VALUE(0x20A)
			 STREAM_MATCH_SID_MASK(0x3FF)>,
			<38 STREAM_CFG(PTLB_ID(0x6), STLB_ID(0x5), FETCH_SIZE(SIZE16), PTLB_DIS, STLB_EN)
			 STREAM_MATCH_CFG(DIR_READ)
			 STREAM_MATCH_SID_VALUE(0x30A)
			 STREAM_MATCH_SID_MASK(0x3FF)>,
			<39 STREAM_CFG(PTLB_ID(0x6), STLB_ID(0xa), FETCH_SIZE(SIZE2), PTLB_DIS, STLB_EN)
			 STREAM_MATCH_CFG(DIR_READ)
			 STREAM_MATCH_SID_VALUE(0x18A)
			 STREAM_MATCH_SID_MASK(0x3FF)>,
			<40 STREAM_CFG(PTLB_ID(0x6), STLB_ID(0xe), FETCH_SIZE(SIZE2), PTLB_DIS, STLB_EN)
			 STREAM_MATCH_CFG(DIR_READ)
			 STREAM_MATCH_SID_VALUE(0x28A)
			 STREAM_MATCH_SID_MASK(0x3FF)>,
			<41 STREAM_CFG(PTLB_ID(0x6), STLB_ID(0x11), FETCH_SIZE(SIZE2), PTLB_DIS, STLB_EN)
			 STREAM_MATCH_CFG(DIR_READ)
			 STREAM_MATCH_SID_VALUE(0x38A)
			 STREAM_MATCH_SID_MASK(0x3FF)>,
			<42 STREAM_CFG(PTLB_ID(0x7), STLB_ID(0x6), FETCH_SIZE(SIZE2), PTLB_DIS, STLB_EN)
			 STREAM_MATCH_CFG(DIR_READ)
			 STREAM_MATCH_SID_VALUE(0x48)
			 STREAM_MATCH_SID_MASK(0x3FF)>,
			<43 STREAM_CFG(PTLB_ID(0x7), STLB_ID(0x9), FETCH_SIZE(SIZE2), PTLB_DIS, STLB_EN)
			 STREAM_MATCH_CFG(DIR_READ)
			 STREAM_MATCH_SID_VALUE(0x148)
			 STREAM_MATCH_SID_MASK(0x3FF)>,
			<44 STREAM_CFG(PTLB_ID(0x7), STLB_ID(0xd), FETCH_SIZE(SIZE2), PTLB_DIS, STLB_EN)
			 STREAM_MATCH_CFG(DIR_READ)
			 STREAM_MATCH_SID_VALUE(0x248)
			 STREAM_MATCH_SID_MASK(0x3FF)>,
			<45 STREAM_CFG(PTLB_ID(0x7), STLB_ID(0x10), FETCH_SIZE(SIZE2), PTLB_DIS, STLB_EN)
			 STREAM_MATCH_CFG(DIR_READ)
			 STREAM_MATCH_SID_VALUE(0x248)
			 STREAM_MATCH_SID_MASK(0x3FF)>,
			<46 STREAM_CFG(PTLB_ID(0x8), STLB_ID(0x2), FETCH_SIZE(SIZE16), PTLB_DIS, STLB_EN)
			 STREAM_MATCH_CFG(DIR_READ)
			 STREAM_MATCH_SID_VALUE(0xE)
			 STREAM_MATCH_SID_MASK(0x3FF)>,
			<47 STREAM_CFG(PTLB_ID(0x8), STLB_ID(0x0), FETCH_SIZE(SIZE64), PTLB_DIS, STLB_DIS)
			 STREAM_MATCH_CFG(DIR_READ)
			 STREAM_MATCH_SID_VALUE(0x8E)
			 STREAM_MATCH_SID_MASK(0x3FF)>,
			<48 STREAM_CFG(PTLB_ID(0x8), STLB_ID(0x3), FETCH_SIZE(SIZE16), PTLB_DIS, STLB_EN)
			 STREAM_MATCH_CFG(DIR_READ)
			 STREAM_MATCH_SID_VALUE(0x10E)
			 STREAM_MATCH_SID_MASK(0x3FF)>,
			<49 STREAM_CFG(PTLB_ID(0x8), STLB_ID(0x4), FETCH_SIZE(SIZE16), PTLB_DIS, STLB_EN)
			 STREAM_MATCH_CFG(DIR_READ)
			 STREAM_MATCH_SID_VALUE(0x20E)
			 STREAM_MATCH_SID_MASK(0x3FF)>,
			<50 STREAM_CFG(PTLB_ID(0x8), STLB_ID(0x5), FETCH_SIZE(SIZE16), PTLB_DIS, STLB_EN)
			 STREAM_MATCH_CFG(DIR_READ)
			 STREAM_MATCH_SID_VALUE(0x30E)
			 STREAM_MATCH_SID_MASK(0x3FF)>,
			<51 STREAM_CFG(PTLB_ID(0x8), STLB_ID(0xa), FETCH_SIZE(SIZE2), PTLB_DIS, STLB_EN)
			 STREAM_MATCH_CFG(DIR_READ)
			 STREAM_MATCH_SID_VALUE(0x18E)
			 STREAM_MATCH_SID_MASK(0x3FF)>,
			<52 STREAM_CFG(PTLB_ID(0x8), STLB_ID(0xe), FETCH_SIZE(SIZE2), PTLB_DIS, STLB_EN)
			 STREAM_MATCH_CFG(DIR_READ)
			 STREAM_MATCH_SID_VALUE(0x28E)
			 STREAM_MATCH_SID_MASK(0x3FF)>,
			<53 STREAM_CFG(PTLB_ID(0x8), STLB_ID(0x11), FETCH_SIZE(SIZE2), PTLB_DIS, STLB_EN)
			 STREAM_MATCH_CFG(DIR_READ)
			 STREAM_MATCH_SID_VALUE(0x38E)
			 STREAM_MATCH_SID_MASK(0x3FF)>,
			<54 STREAM_CFG(PTLB_ID(0x9), STLB_ID(0x1), FETCH_SIZE(SIZE64), PTLB_DIS, STLB_DIS)
			 STREAM_MATCH_CFG(DIR_READ)
			 STREAM_MATCH_SID_VALUE(0xAF)
			 STREAM_MATCH_SID_MASK(0x3FF)>,
			<55 STREAM_CFG(PTLB_ID(0x9), STLB_ID(0xb), FETCH_SIZE(SIZE2), PTLB_DIS, STLB_EN)
			 STREAM_MATCH_CFG(DIR_READ)
			 STREAM_MATCH_SID_VALUE(0x1AF)
			 STREAM_MATCH_SID_MASK(0x3FF)>,
			<56 STREAM_CFG(PTLB_ID(0x9), STLB_ID(0xf), FETCH_SIZE(SIZE2), PTLB_DIS, STLB_EN)
			 STREAM_MATCH_CFG(DIR_READ)
			 STREAM_MATCH_SID_VALUE(0x2AF)
			 STREAM_MATCH_SID_MASK(0x3FF)>,
			<57 STREAM_CFG(PTLB_ID(0x9), STLB_ID(0x12), FETCH_SIZE(SIZE2), PTLB_DIS, STLB_EN)
			 STREAM_MATCH_CFG(DIR_READ)
			 STREAM_MATCH_SID_VALUE(0x3AF)
			 STREAM_MATCH_SID_MASK(0x3FF)>,
			<58 STREAM_CFG(PTLB_ID(0xa), STLB_ID(0x6), FETCH_SIZE(SIZE2), PTLB_DIS, STLB_EN)
			 STREAM_MATCH_CFG(DIR_READ)
			 STREAM_MATCH_SID_VALUE(0x4C)
			 STREAM_MATCH_SID_MASK(0x3FF)>,
			<59 STREAM_CFG(PTLB_ID(0xa), STLB_ID(0x9), FETCH_SIZE(SIZE2), PTLB_DIS, STLB_EN)
			 STREAM_MATCH_CFG(DIR_READ)
			 STREAM_MATCH_SID_VALUE(0x14C)
			 STREAM_MATCH_SID_MASK(0x3FF)>,
			<60 STREAM_CFG(PTLB_ID(0xa), STLB_ID(0xd), FETCH_SIZE(SIZE2), PTLB_DIS, STLB_EN)
			 STREAM_MATCH_CFG(DIR_READ)
			 STREAM_MATCH_SID_VALUE(0x24C)
			 STREAM_MATCH_SID_MASK(0x3FF)>,
			<61 STREAM_CFG(PTLB_ID(0xa), STLB_ID(0x10), FETCH_SIZE(SIZE2), PTLB_DIS, STLB_EN)
			 STREAM_MATCH_CFG(DIR_READ)
			 STREAM_MATCH_SID_VALUE(0x24C)
			 STREAM_MATCH_SID_MASK(0x3FF)>,
			<62 STREAM_CFG(PTLB_ID(0xa), STLB_ID(0x7), FETCH_SIZE(SIZE2), PTLB_DIS, STLB_EN)
			 STREAM_MATCH_CFG(DIR_READ)
			 STREAM_MATCH_SID_VALUE(0xCC)
			 STREAM_MATCH_SID_MASK(0x3FF)>,
			<63 STREAM_CFG(PTLB_ID(0xa), STLB_ID(0xc), FETCH_SIZE(SIZE2), PTLB_DIS, STLB_EN)
			 STREAM_MATCH_CFG(DIR_READ)
			 STREAM_MATCH_SID_VALUE(0x1CC)
			 STREAM_MATCH_SID_MASK(0x3FF)>,
			<64 STREAM_CFG(PTLB_ID(0xa), STLB_ID(0x1a), FETCH_SIZE(SIZE1), PTLB_DIS, STLB_EN)
			 STREAM_MATCH_CFG(DIR_READ)
			 STREAM_MATCH_SID_VALUE(0x2CC)
			 STREAM_MATCH_SID_MASK(0x3FF)>,
			<65 STREAM_CFG(PTLB_ID(0xb), STLB_ID(0x8), FETCH_SIZE(SIZE2), PTLB_DIS, STLB_EN)
			 STREAM_MATCH_CFG(DIR_READ)
			 STREAM_MATCH_SID_VALUE(0xED)
			 STREAM_MATCH_SID_MASK(0x3FF)>,
			<66 STREAM_CFG(PTLB_ID(0xb), STLB_ID(0x15), FETCH_SIZE(SIZE1), PTLB_DIS, STLB_EN)
			 STREAM_MATCH_CFG(DIR_READ)
			 STREAM_MATCH_SID_VALUE(0x1ED)
			 STREAM_MATCH_SID_MASK(0x3FF)>,
			<67 STREAM_CFG(PTLB_ID(0xb), STLB_ID(0x1b), FETCH_SIZE(SIZE1), PTLB_DIS, STLB_EN)
			 STREAM_MATCH_CFG(DIR_READ)
			 STREAM_MATCH_SID_VALUE(0x2ED)
			 STREAM_MATCH_SID_MASK(0x3FF)>,
			<68 STREAM_CFG(PTLB_ID(0xc), STLB_ID(0x16), FETCH_SIZE(SIZE1), PTLB_DIS, STLB_EN)
			 STREAM_MATCH_CFG(DIR_READ)
			 STREAM_MATCH_SID_VALUE(0x10)
			 STREAM_MATCH_SID_MASK(0x3FF)>,
			<69 STREAM_CFG(PTLB_ID(0xd), STLB_ID(0x1d), FETCH_SIZE(SIZE1), PTLB_DIS, STLB_DIS)
			 STREAM_MATCH_CFG(DIR_WRITE)
			 STREAM_MATCH_SID_VALUE(0x0)
			 STREAM_MATCH_SID_MASK(0x3FF)>,
			<70 STREAM_CFG(PTLB_ID(0xe), STLB_ID(0x1e), FETCH_SIZE(SIZE1), PTLB_DIS, STLB_DIS)
			 STREAM_MATCH_CFG(DIR_WRITE)
			 STREAM_MATCH_SID_VALUE(0x1)
			 STREAM_MATCH_SID_MASK(0x3FF)>;
		num_pmmu = <2>;
		vmid_mask = <0x3>;
		sysmmu,feature-info = <0x0>;
		port-name = "DPU_DMA_TOP DPU_DMA_TOP ";
		power-domains = <&pd_dpuf0>;
	};

	sysmmu_dpu_s1: sysmmu@1AC70000 {
		compatible = "samsung,sysmmu-v9";
		reg = <0 0x1AC70000 0xA000>;
		interrupts = <0 INTREQ__DPUF0_SYSMMU_DPUF_S1_S1_NS IRQ_TYPE_LEVEL_HIGH>,
				<0 INTREQ__DPUF0_SYSMMU_DPUF_S1_S1_S IRQ_TYPE_LEVEL_HIGH>;
		sysmmu,secure-irq;
		sysmmu,secure_base = <0x1AC80000>;
		qos = <15>;
		#iommu-cells = <0>;
		pmmu0,num_stream_table = <72>;
		pmmu0,num_ptlb = <16>;
		pmmu0,default_stream =
			<STREAM_CFG(PTLB_ID(0x0), STLB_ID(0x2), FETCH_SIZE(SIZE16), PTLB_DIS, STLB_EN)>;
		pmmu0,stream_property =
			<1 STREAM_CFG(PTLB_ID(0x0), STLB_ID(0x0), FETCH_SIZE(SIZE64), PTLB_DIS, STLB_DIS)
			 STREAM_MATCH_CFG(DIR_READ)
			 STREAM_MATCH_SID_VALUE(0x82)
			 STREAM_MATCH_SID_MASK(0x3FF)>,
			<2 STREAM_CFG(PTLB_ID(0x0), STLB_ID(0x3), FETCH_SIZE(SIZE16), PTLB_DIS, STLB_EN)
			 STREAM_MATCH_CFG(DIR_READ)
			 STREAM_MATCH_SID_VALUE(0x102)
			 STREAM_MATCH_SID_MASK(0x3FF)>,
			<3 STREAM_CFG(PTLB_ID(0x0), STLB_ID(0x4), FETCH_SIZE(SIZE16), PTLB_DIS, STLB_EN)
			 STREAM_MATCH_CFG(DIR_READ)
			 STREAM_MATCH_SID_VALUE(0x202)
			 STREAM_MATCH_SID_MASK(0x3FF)>,
			<4 STREAM_CFG(PTLB_ID(0x0), STLB_ID(0x5), FETCH_SIZE(SIZE16), PTLB_DIS, STLB_EN)
			 STREAM_MATCH_CFG(DIR_READ)
			 STREAM_MATCH_SID_VALUE(0x302)
			 STREAM_MATCH_SID_MASK(0x3FF)>,
			<5 STREAM_CFG(PTLB_ID(0x0), STLB_ID(0xa), FETCH_SIZE(SIZE2), PTLB_DIS, STLB_EN)
			 STREAM_MATCH_CFG(DIR_READ)
			 STREAM_MATCH_SID_VALUE(0x182)
			 STREAM_MATCH_SID_MASK(0x3FF)>,
			<6 STREAM_CFG(PTLB_ID(0x0), STLB_ID(0xe), FETCH_SIZE(SIZE2), PTLB_DIS, STLB_EN)
			 STREAM_MATCH_CFG(DIR_READ)
			 STREAM_MATCH_SID_VALUE(0x282)
			 STREAM_MATCH_SID_MASK(0x3FF)>,
			<7 STREAM_CFG(PTLB_ID(0x0), STLB_ID(0x11), FETCH_SIZE(SIZE2), PTLB_DIS, STLB_EN)
			 STREAM_MATCH_CFG(DIR_READ)
			 STREAM_MATCH_SID_VALUE(0x382)
			 STREAM_MATCH_SID_MASK(0x3FF)>,
			<8 STREAM_CFG(PTLB_ID(0x1), STLB_ID(0x6), FETCH_SIZE(SIZE2), PTLB_DIS, STLB_EN)
			 STREAM_MATCH_CFG(DIR_READ)
			 STREAM_MATCH_SID_VALUE(0x40)
			 STREAM_MATCH_SID_MASK(0x3FF)>,
			<9 STREAM_CFG(PTLB_ID(0x1), STLB_ID(0x9), FETCH_SIZE(SIZE2), PTLB_DIS, STLB_EN)
			 STREAM_MATCH_CFG(DIR_READ)
			 STREAM_MATCH_SID_VALUE(0x140)
			 STREAM_MATCH_SID_MASK(0x3FF)>,
			<10 STREAM_CFG(PTLB_ID(0x1), STLB_ID(0xd), FETCH_SIZE(SIZE2), PTLB_DIS, STLB_EN)
			 STREAM_MATCH_CFG(DIR_READ)
			 STREAM_MATCH_SID_VALUE(0x240)
			 STREAM_MATCH_SID_MASK(0x3FF)>,
			<11 STREAM_CFG(PTLB_ID(0x1), STLB_ID(0x10), FETCH_SIZE(SIZE2), PTLB_DIS, STLB_EN)
			 STREAM_MATCH_CFG(DIR_READ)
			 STREAM_MATCH_SID_VALUE(0x340)
			 STREAM_MATCH_SID_MASK(0x3FF)>,
			<12 STREAM_CFG(PTLB_ID(0x2), STLB_ID(0x2), FETCH_SIZE(SIZE16), PTLB_DIS, STLB_EN)
			 STREAM_MATCH_CFG(DIR_READ)
			 STREAM_MATCH_SID_VALUE(0x6)
			 STREAM_MATCH_SID_MASK(0x3FF)>,
			<13 STREAM_CFG(PTLB_ID(0x2), STLB_ID(0x0), FETCH_SIZE(SIZE64), PTLB_DIS, STLB_DIS)
			 STREAM_MATCH_CFG(DIR_READ)
			 STREAM_MATCH_SID_VALUE(0x86)
			 STREAM_MATCH_SID_MASK(0x3FF)>,
			<14 STREAM_CFG(PTLB_ID(0x2), STLB_ID(0x3), FETCH_SIZE(SIZE16), PTLB_DIS, STLB_EN)
			 STREAM_MATCH_CFG(DIR_READ)
			 STREAM_MATCH_SID_VALUE(0x106)
			 STREAM_MATCH_SID_MASK(0x3FF)>,
			<15 STREAM_CFG(PTLB_ID(0x2), STLB_ID(0x4), FETCH_SIZE(SIZE16), PTLB_DIS, STLB_EN)
			 STREAM_MATCH_CFG(DIR_READ)
			 STREAM_MATCH_SID_VALUE(0x206)
			 STREAM_MATCH_SID_MASK(0x3FF)>,
			<16 STREAM_CFG(PTLB_ID(0x2), STLB_ID(0x5), FETCH_SIZE(SIZE16), PTLB_DIS, STLB_EN)
			 STREAM_MATCH_CFG(DIR_READ)
			 STREAM_MATCH_SID_VALUE(0x306)
			 STREAM_MATCH_SID_MASK(0x3FF)>,
			<17 STREAM_CFG(PTLB_ID(0x2), STLB_ID(0xa), FETCH_SIZE(SIZE2), PTLB_DIS, STLB_EN)
			 STREAM_MATCH_CFG(DIR_READ)
			 STREAM_MATCH_SID_VALUE(0x186)
			 STREAM_MATCH_SID_MASK(0x3FF)>,
			<18 STREAM_CFG(PTLB_ID(0x2), STLB_ID(0xe), FETCH_SIZE(SIZE2), PTLB_DIS, STLB_EN)
			 STREAM_MATCH_CFG(DIR_READ)
			 STREAM_MATCH_SID_VALUE(0x286)
			 STREAM_MATCH_SID_MASK(0x3FF)>,
			<19 STREAM_CFG(PTLB_ID(0x2), STLB_ID(0x11), FETCH_SIZE(SIZE2), PTLB_DIS, STLB_EN)
			 STREAM_MATCH_CFG(DIR_READ)
			 STREAM_MATCH_SID_VALUE(0x386)
			 STREAM_MATCH_SID_MASK(0x3FF)>,
			<20 STREAM_CFG(PTLB_ID(0x3), STLB_ID(0x1), FETCH_SIZE(SIZE64), PTLB_DIS, STLB_DIS)
			 STREAM_MATCH_CFG(DIR_READ)
			 STREAM_MATCH_SID_VALUE(0xA7)
			 STREAM_MATCH_SID_MASK(0x3FF)>,
			<21 STREAM_CFG(PTLB_ID(0x3), STLB_ID(0xb), FETCH_SIZE(SIZE2), PTLB_DIS, STLB_EN)
			 STREAM_MATCH_CFG(DIR_READ)
			 STREAM_MATCH_SID_VALUE(0x1A7)
			 STREAM_MATCH_SID_MASK(0x3FF)>,
			<22 STREAM_CFG(PTLB_ID(0x3), STLB_ID(0xf), FETCH_SIZE(SIZE2), PTLB_DIS, STLB_EN)
			 STREAM_MATCH_CFG(DIR_READ)
			 STREAM_MATCH_SID_VALUE(0x2A7)
			 STREAM_MATCH_SID_MASK(0x3FF)>,
			<23 STREAM_CFG(PTLB_ID(0x3), STLB_ID(0x12), FETCH_SIZE(SIZE2), PTLB_DIS, STLB_EN)
			 STREAM_MATCH_CFG(DIR_READ)
			 STREAM_MATCH_SID_VALUE(0x3A7)
			 STREAM_MATCH_SID_MASK(0x3FF)>,
			<24 STREAM_CFG(PTLB_ID(0x4), STLB_ID(0x6), FETCH_SIZE(SIZE2), PTLB_DIS, STLB_EN)
			 STREAM_MATCH_CFG(DIR_READ)
			 STREAM_MATCH_SID_VALUE(0x44)
			 STREAM_MATCH_SID_MASK(0x3FF)>,
			<25 STREAM_CFG(PTLB_ID(0x4), STLB_ID(0x9), FETCH_SIZE(SIZE2), PTLB_DIS, STLB_EN)
			 STREAM_MATCH_CFG(DIR_READ)
			 STREAM_MATCH_SID_VALUE(0x144)
			 STREAM_MATCH_SID_MASK(0x3FF)>,
			<26 STREAM_CFG(PTLB_ID(0x4), STLB_ID(0xd), FETCH_SIZE(SIZE2), PTLB_DIS, STLB_EN)
			 STREAM_MATCH_CFG(DIR_READ)
			 STREAM_MATCH_SID_VALUE(0x244)
			 STREAM_MATCH_SID_MASK(0x3FF)>,
			<27 STREAM_CFG(PTLB_ID(0x4), STLB_ID(0x10), FETCH_SIZE(SIZE2), PTLB_DIS, STLB_EN)
			 STREAM_MATCH_CFG(DIR_READ)
			 STREAM_MATCH_SID_VALUE(0x344)
			 STREAM_MATCH_SID_MASK(0x3FF)>,
			<28 STREAM_CFG(PTLB_ID(0x4), STLB_ID(0x7), FETCH_SIZE(SIZE2), PTLB_DIS, STLB_EN)
			 STREAM_MATCH_CFG(DIR_READ)
			 STREAM_MATCH_SID_VALUE(0xC4)
			 STREAM_MATCH_SID_MASK(0x3FF)>,
			<29 STREAM_CFG(PTLB_ID(0x4), STLB_ID(0xc), FETCH_SIZE(SIZE2), PTLB_DIS, STLB_EN)
			 STREAM_MATCH_CFG(DIR_READ)
			 STREAM_MATCH_SID_VALUE(0x1C4)
			 STREAM_MATCH_SID_MASK(0x3FF)>,
			<30 STREAM_CFG(PTLB_ID(0x4), STLB_ID(0x1a), FETCH_SIZE(SIZE1), PTLB_DIS, STLB_EN)
			 STREAM_MATCH_CFG(DIR_READ)
			 STREAM_MATCH_SID_VALUE(0x2C4)
			 STREAM_MATCH_SID_MASK(0x3FF)>,
			<31 STREAM_CFG(PTLB_ID(0x5), STLB_ID(0x8), FETCH_SIZE(SIZE2), PTLB_DIS, STLB_EN)
			 STREAM_MATCH_CFG(DIR_READ)
			 STREAM_MATCH_SID_VALUE(0xE5)
			 STREAM_MATCH_SID_MASK(0x3FF)>,
			<32 STREAM_CFG(PTLB_ID(0x5), STLB_ID(0x15), FETCH_SIZE(SIZE1), PTLB_DIS, STLB_EN)
			 STREAM_MATCH_CFG(DIR_READ)
			 STREAM_MATCH_SID_VALUE(0x1E5)
			 STREAM_MATCH_SID_MASK(0x3FF)>,
			<33 STREAM_CFG(PTLB_ID(0x5), STLB_ID(0x1b), FETCH_SIZE(SIZE1), PTLB_DIS, STLB_EN)
			 STREAM_MATCH_CFG(DIR_READ)
			 STREAM_MATCH_SID_VALUE(0x2E5)
			 STREAM_MATCH_SID_MASK(0x3FF)>,
			<34 STREAM_CFG(PTLB_ID(0x6), STLB_ID(0x2), FETCH_SIZE(SIZE16), PTLB_DIS, STLB_EN)
			 STREAM_MATCH_CFG(DIR_READ)
			 STREAM_MATCH_SID_VALUE(0xA)
			 STREAM_MATCH_SID_MASK(0x3FF)>,
			<35 STREAM_CFG(PTLB_ID(0x6), STLB_ID(0x0), FETCH_SIZE(SIZE64), PTLB_DIS, STLB_DIS)
			 STREAM_MATCH_CFG(DIR_READ)
			 STREAM_MATCH_SID_VALUE(0x8A)
			 STREAM_MATCH_SID_MASK(0x3FF)>,
			<36 STREAM_CFG(PTLB_ID(0x6), STLB_ID(0x3), FETCH_SIZE(SIZE16), PTLB_DIS, STLB_EN)
			 STREAM_MATCH_CFG(DIR_READ)
			 STREAM_MATCH_SID_VALUE(0x10A)
			 STREAM_MATCH_SID_MASK(0x3FF)>,
			<37 STREAM_CFG(PTLB_ID(0x6), STLB_ID(0x4), FETCH_SIZE(SIZE16), PTLB_DIS, STLB_EN)
			 STREAM_MATCH_CFG(DIR_READ)
			 STREAM_MATCH_SID_VALUE(0x20A)
			 STREAM_MATCH_SID_MASK(0x3FF)>,
			<38 STREAM_CFG(PTLB_ID(0x6), STLB_ID(0x5), FETCH_SIZE(SIZE16), PTLB_DIS, STLB_EN)
			 STREAM_MATCH_CFG(DIR_READ)
			 STREAM_MATCH_SID_VALUE(0x30A)
			 STREAM_MATCH_SID_MASK(0x3FF)>,
			<39 STREAM_CFG(PTLB_ID(0x6), STLB_ID(0xa), FETCH_SIZE(SIZE2), PTLB_DIS, STLB_EN)
			 STREAM_MATCH_CFG(DIR_READ)
			 STREAM_MATCH_SID_VALUE(0x18A)
			 STREAM_MATCH_SID_MASK(0x3FF)>,
			<40 STREAM_CFG(PTLB_ID(0x6), STLB_ID(0xe), FETCH_SIZE(SIZE2), PTLB_DIS, STLB_EN)
			 STREAM_MATCH_CFG(DIR_READ)
			 STREAM_MATCH_SID_VALUE(0x28A)
			 STREAM_MATCH_SID_MASK(0x3FF)>,
			<41 STREAM_CFG(PTLB_ID(0x6), STLB_ID(0x11), FETCH_SIZE(SIZE2), PTLB_DIS, STLB_EN)
			 STREAM_MATCH_CFG(DIR_READ)
			 STREAM_MATCH_SID_VALUE(0x38A)
			 STREAM_MATCH_SID_MASK(0x3FF)>,
			<42 STREAM_CFG(PTLB_ID(0x7), STLB_ID(0x6), FETCH_SIZE(SIZE2), PTLB_DIS, STLB_EN)
			 STREAM_MATCH_CFG(DIR_READ)
			 STREAM_MATCH_SID_VALUE(0x48)
			 STREAM_MATCH_SID_MASK(0x3FF)>,
			<43 STREAM_CFG(PTLB_ID(0x7), STLB_ID(0x9), FETCH_SIZE(SIZE2), PTLB_DIS, STLB_EN)
			 STREAM_MATCH_CFG(DIR_READ)
			 STREAM_MATCH_SID_VALUE(0x148)
			 STREAM_MATCH_SID_MASK(0x3FF)>,
			<44 STREAM_CFG(PTLB_ID(0x7), STLB_ID(0xd), FETCH_SIZE(SIZE2), PTLB_DIS, STLB_EN)
			 STREAM_MATCH_CFG(DIR_READ)
			 STREAM_MATCH_SID_VALUE(0x248)
			 STREAM_MATCH_SID_MASK(0x3FF)>,
			<45 STREAM_CFG(PTLB_ID(0x7), STLB_ID(0x10), FETCH_SIZE(SIZE2), PTLB_DIS, STLB_EN)
			 STREAM_MATCH_CFG(DIR_READ)
			 STREAM_MATCH_SID_VALUE(0x248)
			 STREAM_MATCH_SID_MASK(0x3FF)>,
			<46 STREAM_CFG(PTLB_ID(0x8), STLB_ID(0x2), FETCH_SIZE(SIZE16), PTLB_DIS, STLB_EN)
			 STREAM_MATCH_CFG(DIR_READ)
			 STREAM_MATCH_SID_VALUE(0xE)
			 STREAM_MATCH_SID_MASK(0x3FF)>,
			<47 STREAM_CFG(PTLB_ID(0x8), STLB_ID(0x0), FETCH_SIZE(SIZE64), PTLB_DIS, STLB_DIS)
			 STREAM_MATCH_CFG(DIR_READ)
			 STREAM_MATCH_SID_VALUE(0x8E)
			 STREAM_MATCH_SID_MASK(0x3FF)>,
			<48 STREAM_CFG(PTLB_ID(0x8), STLB_ID(0x3), FETCH_SIZE(SIZE16), PTLB_DIS, STLB_EN)
			 STREAM_MATCH_CFG(DIR_READ)
			 STREAM_MATCH_SID_VALUE(0x10E)
			 STREAM_MATCH_SID_MASK(0x3FF)>,
			<49 STREAM_CFG(PTLB_ID(0x8), STLB_ID(0x4), FETCH_SIZE(SIZE16), PTLB_DIS, STLB_EN)
			 STREAM_MATCH_CFG(DIR_READ)
			 STREAM_MATCH_SID_VALUE(0x20E)
			 STREAM_MATCH_SID_MASK(0x3FF)>,
			<50 STREAM_CFG(PTLB_ID(0x8), STLB_ID(0x5), FETCH_SIZE(SIZE16), PTLB_DIS, STLB_EN)
			 STREAM_MATCH_CFG(DIR_READ)
			 STREAM_MATCH_SID_VALUE(0x30E)
			 STREAM_MATCH_SID_MASK(0x3FF)>,
			<51 STREAM_CFG(PTLB_ID(0x8), STLB_ID(0xa), FETCH_SIZE(SIZE2), PTLB_DIS, STLB_EN)
			 STREAM_MATCH_CFG(DIR_READ)
			 STREAM_MATCH_SID_VALUE(0x18E)
			 STREAM_MATCH_SID_MASK(0x3FF)>,
			<52 STREAM_CFG(PTLB_ID(0x8), STLB_ID(0xe), FETCH_SIZE(SIZE2), PTLB_DIS, STLB_EN)
			 STREAM_MATCH_CFG(DIR_READ)
			 STREAM_MATCH_SID_VALUE(0x28E)
			 STREAM_MATCH_SID_MASK(0x3FF)>,
			<53 STREAM_CFG(PTLB_ID(0x8), STLB_ID(0x11), FETCH_SIZE(SIZE2), PTLB_DIS, STLB_EN)
			 STREAM_MATCH_CFG(DIR_READ)
			 STREAM_MATCH_SID_VALUE(0x38E)
			 STREAM_MATCH_SID_MASK(0x3FF)>,
			<54 STREAM_CFG(PTLB_ID(0x9), STLB_ID(0x1), FETCH_SIZE(SIZE64), PTLB_DIS, STLB_DIS)
			 STREAM_MATCH_CFG(DIR_READ)
			 STREAM_MATCH_SID_VALUE(0xAF)
			 STREAM_MATCH_SID_MASK(0x3FF)>,
			<55 STREAM_CFG(PTLB_ID(0x9), STLB_ID(0xb), FETCH_SIZE(SIZE2), PTLB_DIS, STLB_EN)
			 STREAM_MATCH_CFG(DIR_READ)
			 STREAM_MATCH_SID_VALUE(0x1AF)
			 STREAM_MATCH_SID_MASK(0x3FF)>,
			<56 STREAM_CFG(PTLB_ID(0x9), STLB_ID(0xf), FETCH_SIZE(SIZE2), PTLB_DIS, STLB_EN)
			 STREAM_MATCH_CFG(DIR_READ)
			 STREAM_MATCH_SID_VALUE(0x2AF)
			 STREAM_MATCH_SID_MASK(0x3FF)>,
			<57 STREAM_CFG(PTLB_ID(0x9), STLB_ID(0x12), FETCH_SIZE(SIZE2), PTLB_DIS, STLB_EN)
			 STREAM_MATCH_CFG(DIR_READ)
			 STREAM_MATCH_SID_VALUE(0x3AF)
			 STREAM_MATCH_SID_MASK(0x3FF)>,
			<58 STREAM_CFG(PTLB_ID(0xa), STLB_ID(0x6), FETCH_SIZE(SIZE2), PTLB_DIS, STLB_EN)
			 STREAM_MATCH_CFG(DIR_READ)
			 STREAM_MATCH_SID_VALUE(0x4C)
			 STREAM_MATCH_SID_MASK(0x3FF)>,
			<59 STREAM_CFG(PTLB_ID(0xa), STLB_ID(0x9), FETCH_SIZE(SIZE2), PTLB_DIS, STLB_EN)
			 STREAM_MATCH_CFG(DIR_READ)
			 STREAM_MATCH_SID_VALUE(0x14C)
			 STREAM_MATCH_SID_MASK(0x3FF)>,
			<60 STREAM_CFG(PTLB_ID(0xa), STLB_ID(0xd), FETCH_SIZE(SIZE2), PTLB_DIS, STLB_EN)
			 STREAM_MATCH_CFG(DIR_READ)
			 STREAM_MATCH_SID_VALUE(0x24C)
			 STREAM_MATCH_SID_MASK(0x3FF)>,
			<61 STREAM_CFG(PTLB_ID(0xa), STLB_ID(0x10), FETCH_SIZE(SIZE2), PTLB_DIS, STLB_EN)
			 STREAM_MATCH_CFG(DIR_READ)
			 STREAM_MATCH_SID_VALUE(0x24C)
			 STREAM_MATCH_SID_MASK(0x3FF)>,
			<62 STREAM_CFG(PTLB_ID(0xa), STLB_ID(0x7), FETCH_SIZE(SIZE2), PTLB_DIS, STLB_EN)
			 STREAM_MATCH_CFG(DIR_READ)
			 STREAM_MATCH_SID_VALUE(0xCC)
			 STREAM_MATCH_SID_MASK(0x3FF)>,
			<63 STREAM_CFG(PTLB_ID(0xa), STLB_ID(0xc), FETCH_SIZE(SIZE2), PTLB_DIS, STLB_EN)
			 STREAM_MATCH_CFG(DIR_READ)
			 STREAM_MATCH_SID_VALUE(0x1CC)
			 STREAM_MATCH_SID_MASK(0x3FF)>,
			<64 STREAM_CFG(PTLB_ID(0xa), STLB_ID(0x1a), FETCH_SIZE(SIZE1), PTLB_DIS, STLB_EN)
			 STREAM_MATCH_CFG(DIR_READ)
			 STREAM_MATCH_SID_VALUE(0x2CC)
			 STREAM_MATCH_SID_MASK(0x3FF)>,
			<65 STREAM_CFG(PTLB_ID(0xb), STLB_ID(0x8), FETCH_SIZE(SIZE2), PTLB_DIS, STLB_EN)
			 STREAM_MATCH_CFG(DIR_READ)
			 STREAM_MATCH_SID_VALUE(0xED)
			 STREAM_MATCH_SID_MASK(0x3FF)>,
			<66 STREAM_CFG(PTLB_ID(0xb), STLB_ID(0x15), FETCH_SIZE(SIZE1), PTLB_DIS, STLB_EN)
			 STREAM_MATCH_CFG(DIR_READ)
			 STREAM_MATCH_SID_VALUE(0x1ED)
			 STREAM_MATCH_SID_MASK(0x3FF)>,
			<67 STREAM_CFG(PTLB_ID(0xb), STLB_ID(0x1b), FETCH_SIZE(SIZE1), PTLB_DIS, STLB_EN)
			 STREAM_MATCH_CFG(DIR_READ)
			 STREAM_MATCH_SID_VALUE(0x2ED)
			 STREAM_MATCH_SID_MASK(0x3FF)>,
			<68 STREAM_CFG(PTLB_ID(0xc), STLB_ID(0x16), FETCH_SIZE(SIZE1), PTLB_DIS, STLB_EN)
			 STREAM_MATCH_CFG(DIR_READ)
			 STREAM_MATCH_SID_VALUE(0x10)
			 STREAM_MATCH_SID_MASK(0x3FF)>,
			<69 STREAM_CFG(PTLB_ID(0xd), STLB_ID(0x17), FETCH_SIZE(SIZE1), PTLB_DIS, STLB_EN)
			 STREAM_MATCH_CFG(DIR_READ)
			 STREAM_MATCH_SID_VALUE(0x14)
			 STREAM_MATCH_SID_MASK(0x3FF)>,
			<70 STREAM_CFG(PTLB_ID(0xe), STLB_ID(0x18), FETCH_SIZE(SIZE1), PTLB_DIS, STLB_EN)
			 STREAM_MATCH_CFG(DIR_WRITE)
			 STREAM_MATCH_SID_VALUE(0x0)
			 STREAM_MATCH_SID_MASK(0x3FF)>,
			<71 STREAM_CFG(PTLB_ID(0xf), STLB_ID(0x19), FETCH_SIZE(SIZE1), PTLB_DIS, STLB_EN)
			 STREAM_MATCH_CFG(DIR_WRITE)
			 STREAM_MATCH_SID_VALUE(0x1)
			 STREAM_MATCH_SID_MASK(0x3FF)>;
		pmmu1,num_stream_table = <71>;
		pmmu1,num_ptlb = <14>;
		pmmu1,default_stream =
			<STREAM_CFG(PTLB_ID(0x0), STLB_ID(0x2), FETCH_SIZE(SIZE16), PTLB_DIS, STLB_EN)>;
		pmmu1,stream_property =
			<1 STREAM_CFG(PTLB_ID(0x0), STLB_ID(0x0), FETCH_SIZE(SIZE64), PTLB_DIS, STLB_DIS)
			 STREAM_MATCH_CFG(DIR_READ)
			 STREAM_MATCH_SID_VALUE(0x82)
			 STREAM_MATCH_SID_MASK(0x3FF)>,
			<2 STREAM_CFG(PTLB_ID(0x0), STLB_ID(0x3), FETCH_SIZE(SIZE16), PTLB_DIS, STLB_EN)
			 STREAM_MATCH_CFG(DIR_READ)
			 STREAM_MATCH_SID_VALUE(0x102)
			 STREAM_MATCH_SID_MASK(0x3FF)>,
			<3 STREAM_CFG(PTLB_ID(0x0), STLB_ID(0x4), FETCH_SIZE(SIZE16), PTLB_DIS, STLB_EN)
			 STREAM_MATCH_CFG(DIR_READ)
			 STREAM_MATCH_SID_VALUE(0x202)
			 STREAM_MATCH_SID_MASK(0x3FF)>,
			<4 STREAM_CFG(PTLB_ID(0x0), STLB_ID(0x5), FETCH_SIZE(SIZE16), PTLB_DIS, STLB_EN)
			 STREAM_MATCH_CFG(DIR_READ)
			 STREAM_MATCH_SID_VALUE(0x302)
			 STREAM_MATCH_SID_MASK(0x3FF)>,
			<5 STREAM_CFG(PTLB_ID(0x0), STLB_ID(0xa), FETCH_SIZE(SIZE2), PTLB_DIS, STLB_EN)
			 STREAM_MATCH_CFG(DIR_READ)
			 STREAM_MATCH_SID_VALUE(0x182)
			 STREAM_MATCH_SID_MASK(0x3FF)>,
			<6 STREAM_CFG(PTLB_ID(0x0), STLB_ID(0xe), FETCH_SIZE(SIZE2), PTLB_DIS, STLB_EN)
			 STREAM_MATCH_CFG(DIR_READ)
			 STREAM_MATCH_SID_VALUE(0x282)
			 STREAM_MATCH_SID_MASK(0x3FF)>,
			<7 STREAM_CFG(PTLB_ID(0x0), STLB_ID(0x11), FETCH_SIZE(SIZE2), PTLB_DIS, STLB_EN)
			 STREAM_MATCH_CFG(DIR_READ)
			 STREAM_MATCH_SID_VALUE(0x382)
			 STREAM_MATCH_SID_MASK(0x3FF)>,
			<8 STREAM_CFG(PTLB_ID(0x1), STLB_ID(0x6), FETCH_SIZE(SIZE2), PTLB_DIS, STLB_EN)
			 STREAM_MATCH_CFG(DIR_READ)
			 STREAM_MATCH_SID_VALUE(0x40)
			 STREAM_MATCH_SID_MASK(0x3FF)>,
			<9 STREAM_CFG(PTLB_ID(0x1), STLB_ID(0x9), FETCH_SIZE(SIZE2), PTLB_DIS, STLB_EN)
			 STREAM_MATCH_CFG(DIR_READ)
			 STREAM_MATCH_SID_VALUE(0x140)
			 STREAM_MATCH_SID_MASK(0x3FF)>,
			<10 STREAM_CFG(PTLB_ID(0x1), STLB_ID(0xd), FETCH_SIZE(SIZE2), PTLB_DIS, STLB_EN)
			 STREAM_MATCH_CFG(DIR_READ)
			 STREAM_MATCH_SID_VALUE(0x240)
			 STREAM_MATCH_SID_MASK(0x3FF)>,
			<11 STREAM_CFG(PTLB_ID(0x1), STLB_ID(0x10), FETCH_SIZE(SIZE2), PTLB_DIS, STLB_EN)
			 STREAM_MATCH_CFG(DIR_READ)
			 STREAM_MATCH_SID_VALUE(0x340)
			 STREAM_MATCH_SID_MASK(0x3FF)>,
			<12 STREAM_CFG(PTLB_ID(0x2), STLB_ID(0x2), FETCH_SIZE(SIZE16), PTLB_DIS, STLB_EN)
			 STREAM_MATCH_CFG(DIR_READ)
			 STREAM_MATCH_SID_VALUE(0x6)
			 STREAM_MATCH_SID_MASK(0x3FF)>,
			<13 STREAM_CFG(PTLB_ID(0x2), STLB_ID(0x0), FETCH_SIZE(SIZE64), PTLB_DIS, STLB_DIS)
			 STREAM_MATCH_CFG(DIR_READ)
			 STREAM_MATCH_SID_VALUE(0x86)
			 STREAM_MATCH_SID_MASK(0x3FF)>,
			<14 STREAM_CFG(PTLB_ID(0x2), STLB_ID(0x3), FETCH_SIZE(SIZE16), PTLB_DIS, STLB_EN)
			 STREAM_MATCH_CFG(DIR_READ)
			 STREAM_MATCH_SID_VALUE(0x106)
			 STREAM_MATCH_SID_MASK(0x3FF)>,
			<15 STREAM_CFG(PTLB_ID(0x2), STLB_ID(0x4), FETCH_SIZE(SIZE16), PTLB_DIS, STLB_EN)
			 STREAM_MATCH_CFG(DIR_READ)
			 STREAM_MATCH_SID_VALUE(0x206)
			 STREAM_MATCH_SID_MASK(0x3FF)>,
			<16 STREAM_CFG(PTLB_ID(0x2), STLB_ID(0x5), FETCH_SIZE(SIZE16), PTLB_DIS, STLB_EN)
			 STREAM_MATCH_CFG(DIR_READ)
			 STREAM_MATCH_SID_VALUE(0x306)
			 STREAM_MATCH_SID_MASK(0x3FF)>,
			<17 STREAM_CFG(PTLB_ID(0x2), STLB_ID(0xa), FETCH_SIZE(SIZE2), PTLB_DIS, STLB_EN)
			 STREAM_MATCH_CFG(DIR_READ)
			 STREAM_MATCH_SID_VALUE(0x186)
			 STREAM_MATCH_SID_MASK(0x3FF)>,
			<18 STREAM_CFG(PTLB_ID(0x2), STLB_ID(0xe), FETCH_SIZE(SIZE2), PTLB_DIS, STLB_EN)
			 STREAM_MATCH_CFG(DIR_READ)
			 STREAM_MATCH_SID_VALUE(0x286)
			 STREAM_MATCH_SID_MASK(0x3FF)>,
			<19 STREAM_CFG(PTLB_ID(0x2), STLB_ID(0x11), FETCH_SIZE(SIZE2), PTLB_DIS, STLB_EN)
			 STREAM_MATCH_CFG(DIR_READ)
			 STREAM_MATCH_SID_VALUE(0x386)
			 STREAM_MATCH_SID_MASK(0x3FF)>,
			<20 STREAM_CFG(PTLB_ID(0x3), STLB_ID(0x1), FETCH_SIZE(SIZE64), PTLB_DIS, STLB_DIS)
			 STREAM_MATCH_CFG(DIR_READ)
			 STREAM_MATCH_SID_VALUE(0xA7)
			 STREAM_MATCH_SID_MASK(0x3FF)>,
			<21 STREAM_CFG(PTLB_ID(0x3), STLB_ID(0xb), FETCH_SIZE(SIZE2), PTLB_DIS, STLB_EN)
			 STREAM_MATCH_CFG(DIR_READ)
			 STREAM_MATCH_SID_VALUE(0x1A7)
			 STREAM_MATCH_SID_MASK(0x3FF)>,
			<22 STREAM_CFG(PTLB_ID(0x3), STLB_ID(0xf), FETCH_SIZE(SIZE2), PTLB_DIS, STLB_EN)
			 STREAM_MATCH_CFG(DIR_READ)
			 STREAM_MATCH_SID_VALUE(0x2A7)
			 STREAM_MATCH_SID_MASK(0x3FF)>,
			<23 STREAM_CFG(PTLB_ID(0x3), STLB_ID(0x12), FETCH_SIZE(SIZE2), PTLB_DIS, STLB_EN)
			 STREAM_MATCH_CFG(DIR_READ)
			 STREAM_MATCH_SID_VALUE(0x3A7)
			 STREAM_MATCH_SID_MASK(0x3FF)>,
			<24 STREAM_CFG(PTLB_ID(0x4), STLB_ID(0x6), FETCH_SIZE(SIZE2), PTLB_DIS, STLB_EN)
			 STREAM_MATCH_CFG(DIR_READ)
			 STREAM_MATCH_SID_VALUE(0x44)
			 STREAM_MATCH_SID_MASK(0x3FF)>,
			<25 STREAM_CFG(PTLB_ID(0x4), STLB_ID(0x9), FETCH_SIZE(SIZE2), PTLB_DIS, STLB_EN)
			 STREAM_MATCH_CFG(DIR_READ)
			 STREAM_MATCH_SID_VALUE(0x144)
			 STREAM_MATCH_SID_MASK(0x3FF)>,
			<26 STREAM_CFG(PTLB_ID(0x4), STLB_ID(0xd), FETCH_SIZE(SIZE2), PTLB_DIS, STLB_EN)
			 STREAM_MATCH_CFG(DIR_READ)
			 STREAM_MATCH_SID_VALUE(0x244)
			 STREAM_MATCH_SID_MASK(0x3FF)>,
			<27 STREAM_CFG(PTLB_ID(0x4), STLB_ID(0x10), FETCH_SIZE(SIZE2), PTLB_DIS, STLB_EN)
			 STREAM_MATCH_CFG(DIR_READ)
			 STREAM_MATCH_SID_VALUE(0x344)
			 STREAM_MATCH_SID_MASK(0x3FF)>,
			<28 STREAM_CFG(PTLB_ID(0x4), STLB_ID(0x7), FETCH_SIZE(SIZE2), PTLB_DIS, STLB_EN)
			 STREAM_MATCH_CFG(DIR_READ)
			 STREAM_MATCH_SID_VALUE(0xC4)
			 STREAM_MATCH_SID_MASK(0x3FF)>,
			<29 STREAM_CFG(PTLB_ID(0x4), STLB_ID(0xc), FETCH_SIZE(SIZE2), PTLB_DIS, STLB_EN)
			 STREAM_MATCH_CFG(DIR_READ)
			 STREAM_MATCH_SID_VALUE(0x1C4)
			 STREAM_MATCH_SID_MASK(0x3FF)>,
			<30 STREAM_CFG(PTLB_ID(0x4), STLB_ID(0x1a), FETCH_SIZE(SIZE1), PTLB_DIS, STLB_EN)
			 STREAM_MATCH_CFG(DIR_READ)
			 STREAM_MATCH_SID_VALUE(0x2C4)
			 STREAM_MATCH_SID_MASK(0x3FF)>,
			<31 STREAM_CFG(PTLB_ID(0x5), STLB_ID(0x8), FETCH_SIZE(SIZE2), PTLB_DIS, STLB_EN)
			 STREAM_MATCH_CFG(DIR_READ)
			 STREAM_MATCH_SID_VALUE(0xE5)
			 STREAM_MATCH_SID_MASK(0x3FF)>,
			<32 STREAM_CFG(PTLB_ID(0x5), STLB_ID(0x15), FETCH_SIZE(SIZE1), PTLB_DIS, STLB_EN)
			 STREAM_MATCH_CFG(DIR_READ)
			 STREAM_MATCH_SID_VALUE(0x1E5)
			 STREAM_MATCH_SID_MASK(0x3FF)>,
			<33 STREAM_CFG(PTLB_ID(0x5), STLB_ID(0x1b), FETCH_SIZE(SIZE1), PTLB_DIS, STLB_EN)
			 STREAM_MATCH_CFG(DIR_READ)
			 STREAM_MATCH_SID_VALUE(0x2E5)
			 STREAM_MATCH_SID_MASK(0x3FF)>,
			<34 STREAM_CFG(PTLB_ID(0x6), STLB_ID(0x2), FETCH_SIZE(SIZE16), PTLB_DIS, STLB_EN)
			 STREAM_MATCH_CFG(DIR_READ)
			 STREAM_MATCH_SID_VALUE(0xA)
			 STREAM_MATCH_SID_MASK(0x3FF)>,
			<35 STREAM_CFG(PTLB_ID(0x6), STLB_ID(0x0), FETCH_SIZE(SIZE64), PTLB_DIS, STLB_DIS)
			 STREAM_MATCH_CFG(DIR_READ)
			 STREAM_MATCH_SID_VALUE(0x8A)
			 STREAM_MATCH_SID_MASK(0x3FF)>,
			<36 STREAM_CFG(PTLB_ID(0x6), STLB_ID(0x3), FETCH_SIZE(SIZE16), PTLB_DIS, STLB_EN)
			 STREAM_MATCH_CFG(DIR_READ)
			 STREAM_MATCH_SID_VALUE(0x10A)
			 STREAM_MATCH_SID_MASK(0x3FF)>,
			<37 STREAM_CFG(PTLB_ID(0x6), STLB_ID(0x4), FETCH_SIZE(SIZE16), PTLB_DIS, STLB_EN)
			 STREAM_MATCH_CFG(DIR_READ)
			 STREAM_MATCH_SID_VALUE(0x20A)
			 STREAM_MATCH_SID_MASK(0x3FF)>,
			<38 STREAM_CFG(PTLB_ID(0x6), STLB_ID(0x5), FETCH_SIZE(SIZE16), PTLB_DIS, STLB_EN)
			 STREAM_MATCH_CFG(DIR_READ)
			 STREAM_MATCH_SID_VALUE(0x30A)
			 STREAM_MATCH_SID_MASK(0x3FF)>,
			<39 STREAM_CFG(PTLB_ID(0x6), STLB_ID(0xa), FETCH_SIZE(SIZE2), PTLB_DIS, STLB_EN)
			 STREAM_MATCH_CFG(DIR_READ)
			 STREAM_MATCH_SID_VALUE(0x18A)
			 STREAM_MATCH_SID_MASK(0x3FF)>,
			<40 STREAM_CFG(PTLB_ID(0x6), STLB_ID(0xe), FETCH_SIZE(SIZE2), PTLB_DIS, STLB_EN)
			 STREAM_MATCH_CFG(DIR_READ)
			 STREAM_MATCH_SID_VALUE(0x28A)
			 STREAM_MATCH_SID_MASK(0x3FF)>,
			<41 STREAM_CFG(PTLB_ID(0x6), STLB_ID(0x11), FETCH_SIZE(SIZE2), PTLB_DIS, STLB_EN)
			 STREAM_MATCH_CFG(DIR_READ)
			 STREAM_MATCH_SID_VALUE(0x38A)
			 STREAM_MATCH_SID_MASK(0x3FF)>,
			<42 STREAM_CFG(PTLB_ID(0x7), STLB_ID(0x6), FETCH_SIZE(SIZE2), PTLB_DIS, STLB_EN)
			 STREAM_MATCH_CFG(DIR_READ)
			 STREAM_MATCH_SID_VALUE(0x48)
			 STREAM_MATCH_SID_MASK(0x3FF)>,
			<43 STREAM_CFG(PTLB_ID(0x7), STLB_ID(0x9), FETCH_SIZE(SIZE2), PTLB_DIS, STLB_EN)
			 STREAM_MATCH_CFG(DIR_READ)
			 STREAM_MATCH_SID_VALUE(0x148)
			 STREAM_MATCH_SID_MASK(0x3FF)>,
			<44 STREAM_CFG(PTLB_ID(0x7), STLB_ID(0xd), FETCH_SIZE(SIZE2), PTLB_DIS, STLB_EN)
			 STREAM_MATCH_CFG(DIR_READ)
			 STREAM_MATCH_SID_VALUE(0x248)
			 STREAM_MATCH_SID_MASK(0x3FF)>,
			<45 STREAM_CFG(PTLB_ID(0x7), STLB_ID(0x10), FETCH_SIZE(SIZE2), PTLB_DIS, STLB_EN)
			 STREAM_MATCH_CFG(DIR_READ)
			 STREAM_MATCH_SID_VALUE(0x248)
			 STREAM_MATCH_SID_MASK(0x3FF)>,
			<46 STREAM_CFG(PTLB_ID(0x8), STLB_ID(0x2), FETCH_SIZE(SIZE16), PTLB_DIS, STLB_EN)
			 STREAM_MATCH_CFG(DIR_READ)
			 STREAM_MATCH_SID_VALUE(0xE)
			 STREAM_MATCH_SID_MASK(0x3FF)>,
			<47 STREAM_CFG(PTLB_ID(0x8), STLB_ID(0x0), FETCH_SIZE(SIZE64), PTLB_DIS, STLB_DIS)
			 STREAM_MATCH_CFG(DIR_READ)
			 STREAM_MATCH_SID_VALUE(0x8E)
			 STREAM_MATCH_SID_MASK(0x3FF)>,
			<48 STREAM_CFG(PTLB_ID(0x8), STLB_ID(0x3), FETCH_SIZE(SIZE16), PTLB_DIS, STLB_EN)
			 STREAM_MATCH_CFG(DIR_READ)
			 STREAM_MATCH_SID_VALUE(0x10E)
			 STREAM_MATCH_SID_MASK(0x3FF)>,
			<49 STREAM_CFG(PTLB_ID(0x8), STLB_ID(0x4), FETCH_SIZE(SIZE16), PTLB_DIS, STLB_EN)
			 STREAM_MATCH_CFG(DIR_READ)
			 STREAM_MATCH_SID_VALUE(0x20E)
			 STREAM_MATCH_SID_MASK(0x3FF)>,
			<50 STREAM_CFG(PTLB_ID(0x8), STLB_ID(0x5), FETCH_SIZE(SIZE16), PTLB_DIS, STLB_EN)
			 STREAM_MATCH_CFG(DIR_READ)
			 STREAM_MATCH_SID_VALUE(0x30E)
			 STREAM_MATCH_SID_MASK(0x3FF)>,
			<51 STREAM_CFG(PTLB_ID(0x8), STLB_ID(0xa), FETCH_SIZE(SIZE2), PTLB_DIS, STLB_EN)
			 STREAM_MATCH_CFG(DIR_READ)
			 STREAM_MATCH_SID_VALUE(0x18E)
			 STREAM_MATCH_SID_MASK(0x3FF)>,
			<52 STREAM_CFG(PTLB_ID(0x8), STLB_ID(0xe), FETCH_SIZE(SIZE2), PTLB_DIS, STLB_EN)
			 STREAM_MATCH_CFG(DIR_READ)
			 STREAM_MATCH_SID_VALUE(0x28E)
			 STREAM_MATCH_SID_MASK(0x3FF)>,
			<53 STREAM_CFG(PTLB_ID(0x8), STLB_ID(0x11), FETCH_SIZE(SIZE2), PTLB_DIS, STLB_EN)
			 STREAM_MATCH_CFG(DIR_READ)
			 STREAM_MATCH_SID_VALUE(0x38E)
			 STREAM_MATCH_SID_MASK(0x3FF)>,
			<54 STREAM_CFG(PTLB_ID(0x9), STLB_ID(0x1), FETCH_SIZE(SIZE64), PTLB_DIS, STLB_DIS)
			 STREAM_MATCH_CFG(DIR_READ)
			 STREAM_MATCH_SID_VALUE(0xAF)
			 STREAM_MATCH_SID_MASK(0x3FF)>,
			<55 STREAM_CFG(PTLB_ID(0x9), STLB_ID(0xb), FETCH_SIZE(SIZE2), PTLB_DIS, STLB_EN)
			 STREAM_MATCH_CFG(DIR_READ)
			 STREAM_MATCH_SID_VALUE(0x1AF)
			 STREAM_MATCH_SID_MASK(0x3FF)>,
			<56 STREAM_CFG(PTLB_ID(0x9), STLB_ID(0xf), FETCH_SIZE(SIZE2), PTLB_DIS, STLB_EN)
			 STREAM_MATCH_CFG(DIR_READ)
			 STREAM_MATCH_SID_VALUE(0x2AF)
			 STREAM_MATCH_SID_MASK(0x3FF)>,
			<57 STREAM_CFG(PTLB_ID(0x9), STLB_ID(0x12), FETCH_SIZE(SIZE2), PTLB_DIS, STLB_EN)
			 STREAM_MATCH_CFG(DIR_READ)
			 STREAM_MATCH_SID_VALUE(0x3AF)
			 STREAM_MATCH_SID_MASK(0x3FF)>,
			<58 STREAM_CFG(PTLB_ID(0xa), STLB_ID(0x6), FETCH_SIZE(SIZE2), PTLB_DIS, STLB_EN)
			 STREAM_MATCH_CFG(DIR_READ)
			 STREAM_MATCH_SID_VALUE(0x4C)
			 STREAM_MATCH_SID_MASK(0x3FF)>,
			<59 STREAM_CFG(PTLB_ID(0xa), STLB_ID(0x9), FETCH_SIZE(SIZE2), PTLB_DIS, STLB_EN)
			 STREAM_MATCH_CFG(DIR_READ)
			 STREAM_MATCH_SID_VALUE(0x14C)
			 STREAM_MATCH_SID_MASK(0x3FF)>,
			<60 STREAM_CFG(PTLB_ID(0xa), STLB_ID(0xd), FETCH_SIZE(SIZE2), PTLB_DIS, STLB_EN)
			 STREAM_MATCH_CFG(DIR_READ)
			 STREAM_MATCH_SID_VALUE(0x24C)
			 STREAM_MATCH_SID_MASK(0x3FF)>,
			<61 STREAM_CFG(PTLB_ID(0xa), STLB_ID(0x10), FETCH_SIZE(SIZE2), PTLB_DIS, STLB_EN)
			 STREAM_MATCH_CFG(DIR_READ)
			 STREAM_MATCH_SID_VALUE(0x24C)
			 STREAM_MATCH_SID_MASK(0x3FF)>,
			<62 STREAM_CFG(PTLB_ID(0xa), STLB_ID(0x7), FETCH_SIZE(SIZE2), PTLB_DIS, STLB_EN)
			 STREAM_MATCH_CFG(DIR_READ)
			 STREAM_MATCH_SID_VALUE(0xCC)
			 STREAM_MATCH_SID_MASK(0x3FF)>,
			<63 STREAM_CFG(PTLB_ID(0xa), STLB_ID(0xc), FETCH_SIZE(SIZE2), PTLB_DIS, STLB_EN)
			 STREAM_MATCH_CFG(DIR_READ)
			 STREAM_MATCH_SID_VALUE(0x1CC)
			 STREAM_MATCH_SID_MASK(0x3FF)>,
			<64 STREAM_CFG(PTLB_ID(0xa), STLB_ID(0x1a), FETCH_SIZE(SIZE1), PTLB_DIS, STLB_EN)
			 STREAM_MATCH_CFG(DIR_READ)
			 STREAM_MATCH_SID_VALUE(0x2CC)
			 STREAM_MATCH_SID_MASK(0x3FF)>,
			<65 STREAM_CFG(PTLB_ID(0xb), STLB_ID(0x8), FETCH_SIZE(SIZE2), PTLB_DIS, STLB_EN)
			 STREAM_MATCH_CFG(DIR_READ)
			 STREAM_MATCH_SID_VALUE(0xED)
			 STREAM_MATCH_SID_MASK(0x3FF)>,
			<66 STREAM_CFG(PTLB_ID(0xb), STLB_ID(0x15), FETCH_SIZE(SIZE1), PTLB_DIS, STLB_EN)
			 STREAM_MATCH_CFG(DIR_READ)
			 STREAM_MATCH_SID_VALUE(0x1ED)
			 STREAM_MATCH_SID_MASK(0x3FF)>,
			<67 STREAM_CFG(PTLB_ID(0xb), STLB_ID(0x1b), FETCH_SIZE(SIZE1), PTLB_DIS, STLB_EN)
			 STREAM_MATCH_CFG(DIR_READ)
			 STREAM_MATCH_SID_VALUE(0x2ED)
			 STREAM_MATCH_SID_MASK(0x3FF)>,
			<68 STREAM_CFG(PTLB_ID(0xc), STLB_ID(0x16), FETCH_SIZE(SIZE1), PTLB_DIS, STLB_EN)
			 STREAM_MATCH_CFG(DIR_READ)
			 STREAM_MATCH_SID_VALUE(0x10)
			 STREAM_MATCH_SID_MASK(0x3FF)>,
			<69 STREAM_CFG(PTLB_ID(0xd), STLB_ID(0x1c), FETCH_SIZE(SIZE1), PTLB_DIS, STLB_DIS)
			 STREAM_MATCH_CFG(DIR_WRITE)
			 STREAM_MATCH_SID_VALUE(0x0)
			 STREAM_MATCH_SID_MASK(0x3FF)>,
			<70 STREAM_CFG(PTLB_ID(0xe), STLB_ID(0x1d), FETCH_SIZE(SIZE1), PTLB_DIS, STLB_DIS)
			 STREAM_MATCH_CFG(DIR_WRITE)
			 STREAM_MATCH_SID_VALUE(0x1)
			 STREAM_MATCH_SID_MASK(0x3FF)>;
		num_pmmu = <2>;
		vmid_mask = <0x3>;
		sysmmu,feature-info = <0x0>;
		port-name = "DPU_DMA_TOP DPU_DMA_TOP ";
		power-domains = <&pd_dpuf1>;
	};

};
